VERSION "FL_IC_CANFD"

NS_ :

BS_:

BU_: AVAS BBCM CMSM DVR EAMP EPC FLZCU ICC PCL PLG SBOX SCU

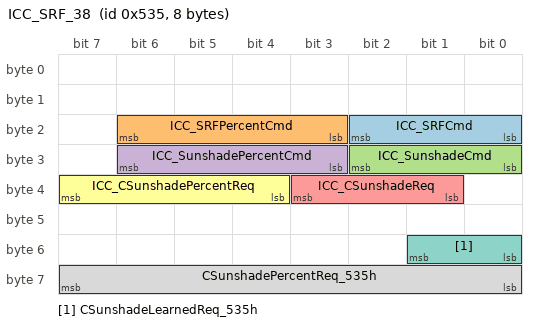
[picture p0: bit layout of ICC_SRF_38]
BO_ 1333 ICC_SRF_38: 8 ICC
 SG_ ICC_SRFCmd : 18|3@0+ (1,0) [0|7] ""  FLZCU
 SG_ ICC_SRFPercentCmd : 22|4@0+ (1,0) [0|15] ""  FLZCU
 SG_ ICC_SunshadeCmd : 26|3@0+ (1,0) [0|7] ""  FLZCU
 SG_ ICC_SunshadePercentCmd : 30|4@0+ (1,0) [0|15] ""  FLZCU
 SG_ ICC_CSunshadeReq : 35|3@0+ (1,0) [0|7] ""  FLZCU
 SG_ ICC_CSunshadePercentReq : 39|4@0+ (1,0) [0|15] ""  FLZCU
 SG_ CSunshadeLearnedReq_535h : 49|2@0+ (1,0) [0|3] ""  FLZCU
 SG_ CSunshadePercentReq_535h : 63|8@0+ (1,0) [0|255] "%"  FLZCU

BO_ 1335 ICC_CH_39: 32 ICC
 SG_ ICC_SET_EPS_SteerReturnRmdSts : 17|2@0+ (1,0) [0|3] ""  FLZCU
 SG_ ICC_SET_MFSShake : 19|2@0+ (1,0) [0|3] ""  FLZCU
 SG_ ICC_DMS_1_DistractionLevel : 22|3@0+ (1,0) [0|7] ""  FLZCU
 SG_ ICC_SET_EPS_AsociWithDrvModSts : 25|2@0+ (1,0) [0|3] ""  FLZCU
 SG_ ICC_OverLoadWarnShieldSet : 27|2@0+ (1,0) [0|3] ""  FLZCU
 SG_ ICC_BSWReq : 29|2@0+ (1,0) [0|3] ""  FLZCU
 SG_ ICC_horizontalReq : 31|2@0+ (1,0) [0|3] ""  FLZCU
 SG_ ICC_RolloverSetCmd : 33|2@0+ (1,0) [0|3] ""  FLZCU
 SG_ ICC_TrekThroughReq_537h : 35|2@0+ (1,0) [0|3] ""  FLZCU
 SG_ ICC_InflateReq_537h : 37|2@0+ (1,0) [0|3] ""  FLZCU
 SG_ ICC_UndergroundModeReq_537h : 39|2@0+ (1,0) [0|3] ""  FLZCU
 SG_ ICC_SandABSSw_537h : 41|2@0+ (1,0) [0|3] ""  FLZCU
 SG_ ICC_SandABSCmd_537h : 43|2@0+ (1,0) [0|3] ""  FLZCU
 SG_ ICC_EPBAUTOCmd_537h : 45|2@0+ (1,0) [0|3] ""  FLZCU
 SG_ ICC_SpeParkSet_537h : 47|2@0+ (1,0) [0|3] ""  FLZCU

BO_ 1337 ICC_TMS_40: 16 ICC
 SG_ ICC_SET_BT_ReduceWindSpeed : 17|2@0+ (1,0) [0|3] ""  FLZCU
 SG_ ICC_SET_IPM_FirstBlowing : 19|2@0+ (1,0) [0|3] ""  FLZCU
 SG_ ICC_SET_IPM_BlowerDelay : 21|2@0+ (1,0) [0|3] ""  FLZCU
 SG_ ICC_SET_CirculationInTunnels : 23|2@0+ (1,0) [0|3] ""  FLZCU
 SG_ ICC_UVCLuminanceReq : 25|2@0+ (1,0) [0|3] ""  FLZCU
 SG_ ICC_UVCControlReq : 27|2@0+ (1,0) [0|3] ""  FLZCU
 SG_ ICC_CrossCountryCoolingReq : 29|2@0+ (1,0) [0|3] ""  FLZCU
 SG_ ICC_KeepWarmReq : 31|2@0+ (1,0) [0|3] ""  FLZCU
 SG_ ICC_keepwarmSetTemperatureReq : 39|8@0+ (1,0) [0|255] ""  FLZCU
 SG_ ICC_ParkingAirConditioning : 41|2@0+ (1,0) [0|3] ""  FLZCU
 SG_ ICC_CoolantFill_Req : 43|2@0+ (1,0) [0|3] ""  FLZCU
 SG_ ICC_FraganceLightoffReq : 45|2@0+ (1,0) [0|3] ""  FLZCU
 SG_ ICC_FraganceMemoffReq : 47|2@0+ (1,0) [0|3] ""  FLZCU
 SG_ ICC_TimingLevel : 50|3@0+ (1,0) [0|7] ""  FLZCU
 SG_ ICC_CFSCycleLevel : 53|3@0+ (1,0) [0|7] ""  FLZCU
 SG_ ICC_AirPurgeReminderReq : 55|2@0+ (1,0) [0|3] ""  FLZCU
 SG_ ICC_TimedVentilationReq : 57|2@0+ (1,0) [0|3] ""  FLZCU
 SG_ ICC_BiochemicalFuncReq : 59|2@0+ (1,0) [0|3] ""  FLZCU
 SG_ ICC_ModeAdjustDisplaySts : 63|4@0+ (1,0) [0|15] ""  FLZCU
 SG_ ICC_PetModeSetTemperature_R_C : 82|5@0+ (0.5,15.5) [15.5|30.5] "℃"  FLZCU
 SG_ ICC_PetmodeSetTemperature_L_C : 87|5@0+ (0.5,15.5) [15.5|30.5] "℃"  FLZCU
 SG_ ICC_PetModeSetCirculationSts : 89|2@0+ (1,0) [0|3] ""  FLZCU
 SG_ ICC_PetModeSetAutoKeySts : 91|2@0+ (1,0) [0|3] ""  FLZCU
 SG_ ICC_PetModeSetCLMOn : 93|2@0+ (1,0) [0|3] ""  FLZCU
 SG_ ICC_ISSFctCmd_539h : 97|2@0+ (1,0) [0|3] ""  FLZCU

BO_ 1338 FMCU_1_G: 8 FLZCU
 SG_ FMCU_ErrLvlDis : 19|3@0+ (1,0) [0|7] ""  ICC
 SG_ FMCU_SpdAct_EDR : 39|16@0+ (1,-32767) [-32767|32766] "rpm"  ICC

BO_ 1341 BMS_44: 48 FLZCU
 SG_ BMS_44_PackPowerRealTime : 23|15@0+ (0.1,-1024) [-1024|1024] "kW"  ICC

BO_ 1345 DVR_1: 16 DVR
 SG_ DVR_1_DVRFailReasons : 20|3@0+ (1,0) [0|7] ""  ICC
 SG_ DVR_1_RecordSts : 22|2@0+ (1,0) [0|3] ""  ICC
 SG_ DVR_1_Sdcard_Sts : 26|3@0+ (1,0) [0|7] ""  ICC

BO_ 1349 SBOX_MSD_1: 16 SBOX
 SG_ SBOX_MSD_Res : 3|4@0+ (1,0) [0|15] ""  ICC
 SG_ SBOX_Ecallphonenub_Res : 7|4@0+ (1,0) [0|15] ""  ICC

BO_ 1351 SBOX_CFG_3: 32 SBOX
 SG_ SBOX_SetMsgTotal : 15|16@0+ (1,0) [0|1000] ""  ICC
 SG_ SBOX_SetMSDTotal : 31|16@0+ (1,0) [0|1000] ""  ICC
 SG_ SBOX_SetCallTimeThreshold : 55|16@0+ (1,0) [0|65535] "min"  ICC
 SG_ SBOX_SetTodayCallTimeThreshold : 71|16@0+ (1,0) [0|65535] "min"  ICC
 SG_ SBOX_SetCurretnCallTime : 87|16@0+ (1,0) [0|65535] "min"  ICC
 SG_ SBOX_SetCurretnMsgThreshold : 103|16@0+ (1,0) [0|1000] ""  ICC
 SG_ SBOX_SetMsgTotalThreshold : 119|16@0+ (1,0) [0|1000] ""  ICC
 SG_ SBOX_SetMsdThreshold : 135|16@0+ (1,0) [0|1000] ""  ICC
 SG_ SBOX_SetCurrenMsdCnt : 151|16@0+ (1,0) [0|1000] ""  ICC
 SG_ SBOX_SetCustomMsgThreshold : 167|16@0+ (1,0) [0|1000] ""  ICC
 SG_ SBOX_SetCurrentCustomMsgCnt : 183|16@0+ (1,0) [0|1000] ""  ICC

BO_ 1353 SBOX_CFG_4: 16 SBOX
 SG_ SBOX_ICC_MACReq : 0|1@0+ (1,0) [0|1] ""  ICC
 SG_ SBOX_MAC_Req0 : 15|8@0+ (1,0) [0|255] ""  ICC
 SG_ SBOX_MAC_Req1 : 23|8@0+ (1,0) [0|255] ""  ICC
 SG_ SBOX_MAC_Req2 : 31|8@0+ (1,0) [0|255] ""  ICC
 SG_ SBOX_MAC_Req3 : 39|8@0+ (1,0) [0|255] ""  ICC
 SG_ SBOX_MAC_Req4 : 47|8@0+ (1,0) [0|255] ""  ICC
 SG_ SBOX_MAC_Req5 : 55|8@0+ (1,0) [0|255] ""  ICC

BO_ 1354 ICC_CFG_46: 32 ICC
 SG_ ICC_SetMsgTotal : 15|16@0+ (1,0) [0|1000] ""  SBOX
 SG_ ICC_SetMSDTotal : 31|16@0+ (1,0) [0|1000] ""  SBOX
 SG_ ICC_SetCallTimeThreshold : 55|16@0+ (1,0) [0|65535] "min"  SBOX
 SG_ ICC_SetTodayCallTimeThreshold : 71|16@0+ (1,0) [0|65535] "min"  SBOX
 SG_ ICC_SetCurretnCallTime : 87|16@0+ (1,0) [0|65535] "min"  SBOX
 SG_ ICC_SetCurretnMsgThreshold : 103|16@0+ (1,0) [0|1000] ""  SBOX
 SG_ ICC_SetMsgTotalThreshold : 119|16@0+ (1,0) [0|1000] ""  SBOX
 SG_ ICC_SetMsdThreshold : 135|16@0+ (1,0) [0|1000] ""  SBOX
 SG_ ICC_SetCurrenMsdCnt : 151|16@0+ (1,0) [0|1000] ""  SBOX
 SG_ ICC_SetCustomMsgThreshold : 167|16@0+ (1,0) [0|1000] ""  SBOX
 SG_ ICC_SetCurrentCustomMsgCnt : 183|16@0+ (1,0) [0|1000] ""  SBOX

BO_ 1356 ICC_CFG_47: 32 ICC
 SG_ ICC_flag : 1|2@0+ (1,0) [0|3] ""  SBOX
 SG_ ICC_ActiveTsp_Req : 3|2@0+ (1,0) [0|3] ""  SBOX
 SG_ ICC_ActiveSim_Req : 5|2@0+ (1,0) [0|3] ""  SBOX
 SG_ ICC_GetMac_req : 6|1@0+ (1,0) [0|1] ""  SBOX
 SG_ ICC_GetIccid_Vin : 7|1@0+ (1,0) [0|1] ""  SBOX
 SG_ ICC_Platform_Phonenub1 : 11|4@0+ (1,0) [0|9] ""  SBOX
 SG_ ICC_Platform_Phonenub2 : 15|4@0+ (1,0) [0|9] ""  SBOX
 SG_ ICC_Platform_Phonenub3 : 19|4@0+ (1,0) [0|9] ""  SBOX
 SG_ ICC_Platform_Phonenub4 : 23|4@0+ (1,0) [0|9] ""  SBOX
 SG_ ICC_Platform_Phonenub5 : 27|4@0+ (1,0) [0|9] ""  SBOX
 SG_ ICC_Platform_Phonenub6 : 31|4@0+ (1,0) [0|9] ""  SBOX
 SG_ ICC_Platform_Phonenub7 : 35|4@0+ (1,0) [0|9] ""  SBOX
 SG_ ICC_Platform_Phonenub8 : 39|4@0+ (1,0) [0|9] ""  SBOX
 SG_ ICC_Platform_Phonenub9 : 43|4@0+ (1,0) [0|9] ""  SBOX
 SG_ ICC_Platform_Phonenub10 : 47|4@0+ (1,0) [0|9] ""  SBOX
 SG_ ICC_Platform_Phonenub11 : 51|4@0+ (1,0) [0|9] ""  SBOX
 SG_ ICC_Platform_Phonenub12 : 55|4@0+ (1,0) [0|9] ""  SBOX
 SG_ ICC_Platform_Phonenub13 : 59|4@0+ (1,0) [0|9] ""  SBOX
 SG_ ICC_Platform_Phonenub14 : 63|4@0+ (1,0) [0|9] ""  SBOX
 SG_ ICC_Platform_Phonenub15 : 67|4@0+ (1,0) [0|9] ""  SBOX
 SG_ ICC_Platform_Phonenub16 : 71|4@0+ (1,0) [0|9] ""  SBOX
 SG_ ICC_Platform_Phonenub17 : 75|4@0+ (1,0) [0|9] ""  SBOX
 SG_ ICC_Platform_Phonenub18 : 79|4@0+ (1,0) [0|9] ""  SBOX
 SG_ ICC_Platform_Phonenub19 : 83|4@0+ (1,0) [0|9] ""  SBOX
 SG_ ICC_Platform_Phonenub20 : 87|4@0+ (1,0) [0|9] ""  SBOX
 SG_ ICC_Mac0 : 95|8@0+ (1,0) [0|255] ""  SBOX
 SG_ ICC_Mac1 : 103|8@0+ (1,0) [0|255] ""  SBOX
 SG_ ICC_Mac2 : 111|8@0+ (1,0) [0|255] ""  SBOX
 SG_ ICC_Mac3 : 119|8@0+ (1,0) [0|255] ""  SBOX
 SG_ ICC_Mac4 : 127|8@0+ (1,0) [0|255] ""  SBOX
 SG_ ICC_Mac5 : 135|8@0+ (1,0) [0|255] ""  SBOX
 SG_ ICC_GivePlatformNumber_Flag : 248|1@0+ (1,0) [0|1] ""  SBOX
 SG_ ICC_Mac_Flag : 249|1@0+ (1,0) [0|1] ""  SBOX

BO_ 1358 SBOX_CFG_5: 64 SBOX
 SG_ SBOX_ActiveTsp_Res : 0|1@0+ (1,0) [0|1] ""  ICC
 SG_ SBOX_ActiveSim_Res : 1|1@0+ (1,0) [0|1] ""  ICC
 SG_ SBOX_GetPlatformNumberRes : 2|1@0+ (1,0) [0|1] ""  ICC
 SG_ SBOX_Mac_Res0 : 15|8@0+ (1,0) [0|255] ""  ICC
 SG_ SBOX_Mac_Res1 : 23|8@0+ (1,0) [0|255] ""  ICC
 SG_ SBOX_Mac_Res2 : 31|8@0+ (1,0) [0|255] ""  ICC
 SG_ SBOX_Mac_Res3 : 39|8@0+ (1,0) [0|255] ""  ICC
 SG_ SBOX_Mac_Res4 : 47|8@0+ (1,0) [0|255] ""  ICC
 SG_ SBOX_Mac_Res5 : 55|8@0+ (1,0) [0|255] ""  ICC
 SG_ SBOX_ICCId_Res0 : 99|4@0+ (1,0) [0|9] ""  ICC
 SG_ SBOX_ICCId_Res1 : 103|4@0+ (1,0) [0|9] ""  ICC
 SG_ SBOX_ICCId_Res2 : 107|4@0+ (1,0) [0|9] ""  ICC
 SG_ SBOX_ICCId_Res3 : 111|4@0+ (1,0) [0|9] ""  ICC
 SG_ SBOX_ICCId_Res4 : 115|4@0+ (1,0) [0|9] ""  ICC
 SG_ SBOX_ICCId_Res5 : 119|4@0+ (1,0) [0|9] ""  ICC
 SG_ SBOX_ICCId_Res6 : 123|4@0+ (1,0) [0|9] ""  ICC
 SG_ SBOX_ICCId_Res7 : 127|4@0+ (1,0) [0|9] ""  ICC
 SG_ SBOX_ICCId_Res8 : 131|4@0+ (1,0) [0|9] ""  ICC
 SG_ SBOX_ICCId_Res9 : 135|4@0+ (1,0) [0|9] ""  ICC
 SG_ SBOX_ICCId_Res10 : 139|4@0+ (1,0) [0|9] ""  ICC
 SG_ SBOX_ICCId_Res11 : 143|4@0+ (1,0) [0|9] ""  ICC
 SG_ SBOX_ICCId_Res12 : 147|4@0+ (1,0) [0|9] ""  ICC
 SG_ SBOX_ICCId_Res13 : 151|4@0+ (1,0) [0|9] ""  ICC
 SG_ SBOX_ICCId_Res14 : 155|4@0+ (1,0) [0|9] ""  ICC
 SG_ SBOX_ICCId_Res15 : 159|4@0+ (1,0) [0|9] ""  ICC
 SG_ SBOX_ICCId_Res16 : 163|4@0+ (1,0) [0|9] ""  ICC
 SG_ SBOX_ICCId_Res17 : 167|4@0+ (1,0) [0|9] ""  ICC
 SG_ SBOX_ICCId_Res18 : 171|4@0+ (1,0) [0|9] ""  ICC
 SG_ SBOX_ICCId_Res19 : 175|4@0+ (1,0) [0|9] ""  ICC
 SG_ SBOX_Vin0 : 183|8@0+ (1,0) [0|90] ""  ICC
 SG_ SBOX_Vin1 : 191|8@0+ (1,0) [0|90] ""  ICC
 SG_ SBOX_Vin2 : 199|8@0+ (1,0) [0|90] ""  ICC
 SG_ SBOX_Vin3 : 207|8@0+ (1,0) [0|90] ""  ICC
 SG_ SBOX_Vin4 : 215|8@0+ (1,0) [0|90] ""  ICC
 SG_ SBOX_Vin5 : 223|8@0+ (1,0) [0|90] ""  ICC
 SG_ SBOX_Vin6 : 231|8@0+ (1,0) [0|90] ""  ICC
 SG_ SBOX_Vin7 : 239|8@0+ (1,0) [0|90] ""  ICC
 SG_ SBOX_Vin8 : 247|8@0+ (1,0) [0|90] ""  ICC
 SG_ SBOX_Vin9 : 255|8@0+ (1,0) [0|90] ""  ICC
 SG_ SBOX_Vin10 : 263|8@0+ (1,0) [0|90] ""  ICC
 SG_ SBOX_Vin11 : 271|8@0+ (1,0) [0|90] ""  ICC
 SG_ SBOX_Vin12 : 279|8@0+ (1,0) [0|90] ""  ICC
 SG_ SBOX_Vin13 : 287|8@0+ (1,0) [0|90] ""  ICC
 SG_ SBOX_Vin14 : 295|8@0+ (1,0) [0|90] ""  ICC
 SG_ SBOX_Vin15 : 303|8@0+ (1,0) [0|90] ""  ICC
 SG_ SBOX_Vin16 : 311|8@0+ (1,0) [0|90] ""  ICC

BO_ 1360 ICC_LC_42: 64 ICC
 SG_ ICC_LISD_DisplaySwitch : 1|2@0+ (1,0) [0|3] ""  FLZCU
 SG_ ICC_LISD_ParkingShowCMD : 3|2@0+ (1,0) [0|3] ""  FLZCU
 SG_ ICC_RISD_DisplaySwitch : 7|2@0+ (1,0) [0|3] ""  FLZCU
 SG_ ICC_RISD_ParkingShowCMD : 9|2@0+ (1,0) [0|3] ""  FLZCU
 SG_ ICC_LogoParkingReq : 13|2@0+ (1,0) [0|3] ""  FLZCU
 SG_ ICC_LogoChargingReq : 15|2@0+ (1,0) [0|3] ""  FLZCU
 SG_ ICC_DRLSw : 17|2@0+ (1,0) [0|3] ""  FLZCU
 SG_ ICC_LISD_ParkingShowMod : 27|4@0+ (1,0) [0|15] ""  FLZCU
 SG_ ICC_RISD_ParkingShowMod : 31|4@0+ (1,0) [0|15] ""  FLZCU
 SG_ ICC_LogoColorReq : 33|9@0+ (1,0) [0|511] ""  FLZCU
 SG_ ICC_MusicLampShowSW : 35|2@0+ (1,0) [0|3] ""  FLZCU
 SG_ ICC_PenetrationLampSetF : 37|2@0+ (1,0) [0|3] ""  FLZCU
 SG_ ICC_XDriveMode : 40|5@0+ (1,0) [0|31] ""  FLZCU
 SG_ ICC_DowWaringSw : 57|2@0+ (1,0) [0|3] ""  FLZCU
 SG_ ICC_CarSearhSetSwitchSts : 59|2@0+ (1,0) [0|3] ""  FLZCU
 SG_ ICC_TDL_NightBright_SW_550h : 61|2@0+ (1,0) [0|3] ""  FLZCU

BO_ 1361 EPC_1: 64 EPC
 SG_ EPC_LeftPedalSystem_Sts : 27|4@0+ (1,0) [0|15] ""  ICC
 SG_ EPC_RightPedalSystem_Sts : 31|4@0+ (1,0) [0|15] ""  ICC
 SG_ EPC_LeftPedalTimeTravel : 39|8@0+ (1,0) [0|100] "%"  ICC
 SG_ EPC_RightPedalTimeTravel : 47|8@0+ (1,0) [0|100] "%"  ICC
 SG_ EPC_RightPedalRealTime_Sts : 50|3@0+ (1,0) [0|7] ""  ICC
 SG_ EPC_LeftPedalBreakIce_Sts : 52|2@0+ (1,0) [0|3] ""  ICC
 SG_ EPC_LeftPedalRealTime_Sts : 55|3@0+ (1,0) [0|7] ""  ICC
 SG_ EPC_RightPedalCmdStatus : 57|2@0+ (1,0) [0|3] ""  ICC
 SG_ EPC_LeftPedalCmdStatus : 59|2@0+ (1,0) [0|3] ""  ICC
 SG_ EPC_Enable_CmdStatus : 61|2@0+ (1,0) [0|3] ""  ICC
 SG_ EPC_RightPedalBreakIce_Sts : 63|2@0+ (1,0) [0|3] ""  ICC
 SG_ EPC_RightPedal3D_Sts : 253|2@0+ (1,0) [0|3] ""  ICC
 SG_ EPC_LeftPedal3D_Sts : 255|2@0+ (1,0) [0|3] ""  ICC

BO_ 1362 ICC_LISD_43: 64 ICC
 SG_ ICC_LISD_FrameCounter : 1|2@0+ (1,0) [0|3] ""  FLZCU
 SG_ ICC_LISD_RollingCounter : 3|2@0+ (1,0) [0|3] ""  FLZCU
 SG_ ICC_LISD_Pixel1_OnOff : 8|1@0+ (1,0) [0|1] ""  FLZCU
 SG_ ICC_LISD_Pixel2_OnOff : 9|1@0+ (1,0) [0|1] ""  FLZCU
 SG_ ICC_LISD_Pixel3_OnOff : 10|1@0+ (1,0) [0|1] ""  FLZCU
 SG_ ICC_LISD_Pixel4_OnOff : 11|1@0+ (1,0) [0|1] ""  FLZCU
 SG_ ICC_LISD_Pixel5_OnOff : 12|1@0+ (1,0) [0|1] ""  FLZCU
 SG_ ICC_LISD_Pixel6_OnOff : 13|1@0+ (1,0) [0|1] ""  FLZCU
 SG_ ICC_LISD_Pixel7_OnOff : 14|1@0+ (1,0) [0|1] ""  FLZCU
 SG_ ICC_LISD_Pixel8_OnOff : 15|1@0+ (1,0) [0|1] ""  FLZCU
 SG_ ICC_LISD_Pixel9_OnOff : 16|1@0+ (1,0) [0|1] ""  FLZCU
 SG_ ICC_LISD_Pixel10_OnOff : 17|1@0+ (1,0) [0|1] ""  FLZCU
 SG_ ICC_LISD_Pixel11_OnOff : 18|1@0+ (1,0) [0|1] ""  FLZCU
 SG_ ICC_LISD_Pixel12_OnOff : 19|1@0+ (1,0) [0|1] ""  FLZCU
 SG_ ICC_LISD_Pixel13_OnOff : 20|1@0+ (1,0) [0|1] ""  FLZCU
 SG_ ICC_LISD_Pixel14_OnOff : 21|1@0+ (1,0) [0|1] ""  FLZCU
 SG_ ICC_LISD_Pixel15_OnOff : 22|1@0+ (1,0) [0|1] ""  FLZCU
 SG_ ICC_LISD_Pixel16_OnOff : 23|1@0+ (1,0) [0|1] ""  FLZCU
 SG_ ICC_LISD_Pixel17_OnOff : 24|1@0+ (1,0) [0|1] ""  FLZCU
 SG_ ICC_LISD_Pixel18_OnOff : 25|1@0+ (1,0) [0|1] ""  FLZCU
 SG_ ICC_LISD_Pixel19_OnOff : 26|1@0+ (1,0) [0|1] ""  FLZCU
 SG_ ICC_LISD_Pixel20_OnOff : 27|1@0+ (1,0) [0|1] ""  FLZCU
 SG_ ICC_LISD_Pixel21_OnOff : 28|1@0+ (1,0) [0|1] ""  FLZCU
 SG_ ICC_LISD_Pixel22_OnOff : 29|1@0+ (1,0) [0|1] ""  FLZCU
 SG_ ICC_LISD_Pixel23_OnOff : 30|1@0+ (1,0) [0|1] ""  FLZCU
 SG_ ICC_LISD_Pixel24_OnOff : 31|1@0+ (1,0) [0|1] ""  FLZCU
 SG_ ICC_LISD_Pixel25_OnOff : 32|1@0+ (1,0) [0|1] ""  FLZCU
 SG_ ICC_LISD_Pixel26_OnOff : 33|1@0+ (1,0) [0|1] ""  FLZCU
 SG_ ICC_LISD_Pixel27_OnOff : 34|1@0+ (1,0) [0|1] ""  FLZCU
 SG_ ICC_LISD_Pixel28_OnOff : 35|1@0+ (1,0) [0|1] ""  FLZCU
 SG_ ICC_LISD_Pixel29_OnOff : 36|1@0+ (1,0) [0|1] ""  FLZCU
 SG_ ICC_LISD_Pixel30_OnOff : 37|1@0+ (1,0) [0|1] ""  FLZCU
 SG_ ICC_LISD_Pixel31_OnOff : 38|1@0+ (1,0) [0|1] ""  FLZCU
 SG_ ICC_LISD_Pixel32_OnOff : 39|1@0+ (1,0) [0|1] ""  FLZCU
 SG_ ICC_LISD_Pixel33_OnOff : 40|1@0+ (1,0) [0|1] ""  FLZCU
 SG_ ICC_LISD_Pixel34_OnOff : 41|1@0+ (1,0) [0|1] ""  FLZCU
 SG_ ICC_LISD_Pixel35_OnOff : 42|1@0+ (1,0) [0|1] ""  FLZCU
 SG_ ICC_LISD_Pixel36_OnOff : 43|1@0+ (1,0) [0|1] ""  FLZCU
 SG_ ICC_LISD_Pixel37_OnOff : 44|1@0+ (1,0) [0|1] ""  FLZCU
 SG_ ICC_LISD_Pixel38_OnOff : 45|1@0+ (1,0) [0|1] ""  FLZCU
 SG_ ICC_LISD_Pixel39_OnOff : 46|1@0+ (1,0) [0|1] ""  FLZCU
 SG_ ICC_LISD_Pixel40_OnOff : 47|1@0+ (1,0) [0|1] ""  FLZCU
 SG_ ICC_LISD_Pixel41_OnOff : 48|1@0+ (1,0) [0|1] ""  FLZCU
 SG_ ICC_LISD_Pixel42_OnOff : 49|1@0+ (1,0) [0|1] ""  FLZCU
 SG_ ICC_LISD_Pixel43_OnOff : 50|1@0+ (1,0) [0|1] ""  FLZCU
 SG_ ICC_LISD_Pixel44_OnOff : 51|1@0+ (1,0) [0|1] ""  FLZCU
 SG_ ICC_LISD_Pixel45_OnOff : 52|1@0+ (1,0) [0|1] ""  FLZCU
 SG_ ICC_LISD_Pixel46_OnOff : 53|1@0+ (1,0) [0|1] ""  FLZCU
 SG_ ICC_LISD_Pixel47_OnOff : 54|1@0+ (1,0) [0|1] ""  FLZCU
 SG_ ICC_LISD_Pixel48_OnOff : 55|1@0+ (1,0) [0|1] ""  FLZCU
 SG_ ICC_LISD_Pixel49_OnOff : 56|1@0+ (1,0) [0|1] ""  FLZCU
 SG_ ICC_LISD_Pixel50_OnOff : 57|1@0+ (1,0) [0|1] ""  FLZCU
 SG_ ICC_LISD_Pixel51_OnOff : 58|1@0+ (1,0) [0|1] ""  FLZCU
 SG_ ICC_LISD_Pixel52_OnOff : 59|1@0+ (1,0) [0|1] ""  FLZCU
 SG_ ICC_LISD_Pixel53_OnOff : 60|1@0+ (1,0) [0|1] ""  FLZCU
 SG_ ICC_LISD_Pixel54_OnOff : 61|1@0+ (1,0) [0|1] ""  FLZCU
 SG_ ICC_LISD_Pixel55_OnOff : 62|1@0+ (1,0) [0|1] ""  FLZCU
 SG_ ICC_LISD_Pixel56_OnOff : 63|1@0+ (1,0) [0|1] ""  FLZCU
 SG_ ICC_LISD_Pixel57_OnOff : 64|1@0+ (1,0) [0|1] ""  FLZCU
 SG_ ICC_LISD_Pixel58_OnOff : 65|1@0+ (1,0) [0|1] ""  FLZCU
 SG_ ICC_LISD_Pixel59_OnOff : 66|1@0+ (1,0) [0|1] ""  FLZCU
 SG_ ICC_LISD_Pixel60_OnOff : 67|1@0+ (1,0) [0|1] ""  FLZCU
 SG_ ICC_LISD_Pixel61_OnOff : 68|1@0+ (1,0) [0|1] ""  FLZCU
 SG_ ICC_LISD_Pixel62_OnOff : 69|1@0+ (1,0) [0|1] ""  FLZCU
 SG_ ICC_LISD_Pixel63_OnOff : 70|1@0+ (1,0) [0|1] ""  FLZCU
 SG_ ICC_LISD_Pixel64_OnOff : 71|1@0+ (1,0) [0|1] ""  FLZCU
 SG_ ICC_LISD_Pixel65_OnOff : 72|1@0+ (1,0) [0|1] ""  FLZCU
 SG_ ICC_LISD_Pixel66_OnOff : 73|1@0+ (1,0) [0|1] ""  FLZCU
 SG_ ICC_LISD_Pixel67_OnOff : 74|1@0+ (1,0) [0|1] ""  FLZCU
 SG_ ICC_LISD_Pixel68_OnOff : 75|1@0+ (1,0) [0|1] ""  FLZCU
 SG_ ICC_LISD_Pixel69_OnOff : 76|1@0+ (1,0) [0|1] ""  FLZCU
 SG_ ICC_LISD_Pixel70_OnOff : 77|1@0+ (1,0) [0|1] ""  FLZCU
 SG_ ICC_LISD_Pixel71_OnOff : 78|1@0+ (1,0) [0|1] ""  FLZCU
 SG_ ICC_LISD_Pixel72_OnOff : 79|1@0+ (1,0) [0|1] ""  FLZCU
 SG_ ICC_LISD_Pixel73_OnOff : 80|1@0+ (1,0) [0|1] ""  FLZCU
 SG_ ICC_LISD_Pixel74_OnOff : 81|1@0+ (1,0) [0|1] ""  FLZCU
 SG_ ICC_LISD_Pixel75_OnOff : 82|1@0+ (1,0) [0|1] ""  FLZCU
 SG_ ICC_LISD_Pixel76_OnOff : 83|1@0+ (1,0) [0|1] ""  FLZCU
 SG_ ICC_LISD_Pixel77_OnOff : 84|1@0+ (1,0) [0|1] ""  FLZCU
 SG_ ICC_LISD_Pixel78_OnOff : 85|1@0+ (1,0) [0|1] ""  FLZCU
 SG_ ICC_LISD_Pixel79_OnOff : 86|1@0+ (1,0) [0|1] ""  FLZCU
 SG_ ICC_LISD_Pixel80_OnOff : 87|1@0+ (1,0) [0|1] ""  FLZCU
 SG_ ICC_LISD_Pixel81_OnOff : 88|1@0+ (1,0) [0|1] ""  FLZCU
 SG_ ICC_LISD_Pixel82_OnOff : 89|1@0+ (1,0) [0|1] ""  FLZCU
 SG_ ICC_LISD_Pixel83_OnOff : 90|1@0+ (1,0) [0|1] ""  FLZCU
 SG_ ICC_LISD_Pixel84_OnOff : 91|1@0+ (1,0) [0|1] ""  FLZCU
 SG_ ICC_LISD_Pixel85_OnOff : 92|1@0+ (1,0) [0|1] ""  FLZCU
 SG_ ICC_LISD_Pixel86_OnOff : 93|1@0+ (1,0) [0|1] ""  FLZCU
 SG_ ICC_LISD_Pixel87_OnOff : 94|1@0+ (1,0) [0|1] ""  FLZCU
 SG_ ICC_LISD_Pixel88_OnOff : 95|1@0+ (1,0) [0|1] ""  FLZCU
 SG_ ICC_LISD_Pixel89_OnOff : 96|1@0+ (1,0) [0|1] ""  FLZCU
 SG_ ICC_LISD_Pixel90_OnOff : 97|1@0+ (1,0) [0|1] ""  FLZCU
 SG_ ICC_LISD_Pixel91_OnOff : 98|1@0+ (1,0) [0|1] ""  FLZCU
 SG_ ICC_LISD_Pixel92_OnOff : 99|1@0+ (1,0) [0|1] ""  FLZCU
 SG_ ICC_LISD_Pixel93_OnOff : 100|1@0+ (1,0) [0|1] ""  FLZCU
 SG_ ICC_LISD_Pixel94_OnOff : 101|1@0+ (1,0) [0|1] ""  FLZCU
 SG_ ICC_LISD_Pixel95_OnOff : 102|1@0+ (1,0) [0|1] ""  FLZCU
 SG_ ICC_LISD_Pixel96_OnOff : 103|1@0+ (1,0) [0|1] ""  FLZCU
 SG_ ICC_LISD_Pixel97_OnOff : 104|1@0+ (1,0) [0|1] ""  FLZCU
 SG_ ICC_LISD_Pixel98_OnOff : 105|1@0+ (1,0) [0|1] ""  FLZCU
 SG_ ICC_LISD_Pixel99_OnOff : 106|1@0+ (1,0) [0|1] ""  FLZCU
 SG_ ICC_LISD_Pixel100_OnOff : 107|1@0+ (1,0) [0|1] ""  FLZCU
 SG_ ICC_LISD_Pixel101_OnOff : 108|1@0+ (1,0) [0|1] ""  FLZCU
 SG_ ICC_LISD_Pixel102_OnOff : 109|1@0+ (1,0) [0|1] ""  FLZCU
 SG_ ICC_LISD_Pixel103_OnOff : 110|1@0+ (1,0) [0|1] ""  FLZCU
 SG_ ICC_LISD_Pixel104_OnOff : 111|1@0+ (1,0) [0|1] ""  FLZCU
 SG_ ICC_LISD_Pixel105_OnOff : 112|1@0+ (1,0) [0|1] ""  FLZCU
 SG_ ICC_LISD_Pixel106_OnOff : 113|1@0+ (1,0) [0|1] ""  FLZCU
 SG_ ICC_LISD_Pixel107_OnOff : 114|1@0+ (1,0) [0|1] ""  FLZCU
 SG_ ICC_LISD_Pixel108_OnOff : 115|1@0+ (1,0) [0|1] ""  FLZCU
 SG_ ICC_LISD_Pixel109_OnOff : 116|1@0+ (1,0) [0|1] ""  FLZCU
 SG_ ICC_LISD_Pixel110_OnOff : 117|1@0+ (1,0) [0|1] ""  FLZCU
 SG_ ICC_LISD_Pixel111_OnOff : 118|1@0+ (1,0) [0|1] ""  FLZCU
 SG_ ICC_LISD_Pixel112_OnOff : 119|1@0+ (1,0) [0|1] ""  FLZCU
 SG_ ICC_LISD_Pixel113_OnOff : 120|1@0+ (1,0) [0|1] ""  FLZCU
 SG_ ICC_LISD_Pixel114_OnOff : 121|1@0+ (1,0) [0|1] ""  FLZCU
 SG_ ICC_LISD_Pixel115_OnOff : 122|1@0+ (1,0) [0|1] ""  FLZCU
 SG_ ICC_LISD_Pixel116_OnOff : 123|1@0+ (1,0) [0|1] ""  FLZCU
 SG_ ICC_LISD_Pixel117_OnOff : 124|1@0+ (1,0) [0|1] ""  FLZCU
 SG_ ICC_LISD_Pixel118_OnOff : 125|1@0+ (1,0) [0|1] ""  FLZCU
 SG_ ICC_LISD_Pixel119_OnOff : 126|1@0+ (1,0) [0|1] ""  FLZCU
 SG_ ICC_LISD_Pixel120_OnOff : 127|1@0+ (1,0) [0|1] ""  FLZCU
 SG_ ICC_LISD_Pixel121_OnOff : 128|1@0+ (1,0) [0|1] ""  FLZCU
 SG_ ICC_LISD_Pixel122_OnOff : 129|1@0+ (1,0) [0|1] ""  FLZCU
 SG_ ICC_LISD_Pixel123_OnOff : 130|1@0+ (1,0) [0|1] ""  FLZCU
 SG_ ICC_LISD_Pixel124_OnOff : 131|1@0+ (1,0) [0|1] ""  FLZCU
 SG_ ICC_LISD_Pixel125_OnOff : 132|1@0+ (1,0) [0|1] ""  FLZCU
 SG_ ICC_LISD_Pixel126_OnOff : 133|1@0+ (1,0) [0|1] ""  FLZCU
 SG_ ICC_LISD_Pixel127_OnOff : 134|1@0+ (1,0) [0|1] ""  FLZCU
 SG_ ICC_LISD_Pixel128_OnOff : 135|1@0+ (1,0) [0|1] ""  FLZCU
 SG_ ICC_LISD_Pixel129_OnOff : 136|1@0+ (1,0) [0|1] ""  FLZCU
 SG_ ICC_LISD_Pixel130_OnOff : 137|1@0+ (1,0) [0|1] ""  FLZCU
 SG_ ICC_LISD_Pixel131_OnOff : 138|1@0+ (1,0) [0|1] ""  FLZCU
 SG_ ICC_LISD_Pixel132_OnOff : 139|1@0+ (1,0) [0|1] ""  FLZCU
 SG_ ICC_LISD_Pixel133_OnOff : 140|1@0+ (1,0) [0|1] ""  FLZCU
 SG_ ICC_LISD_Pixel134_OnOff : 141|1@0+ (1,0) [0|1] ""  FLZCU
 SG_ ICC_LISD_Pixel135_OnOff : 142|1@0+ (1,0) [0|1] ""  FLZCU
 SG_ ICC_LISD_Pixel136_OnOff : 143|1@0+ (1,0) [0|1] ""  FLZCU
 SG_ ICC_LISD_Pixel137_OnOff : 144|1@0+ (1,0) [0|1] ""  FLZCU
 SG_ ICC_LISD_Pixel138_OnOff : 145|1@0+ (1,0) [0|1] ""  FLZCU
 SG_ ICC_LISD_Pixel139_OnOff : 146|1@0+ (1,0) [0|1] ""  FLZCU
 SG_ ICC_LISD_Pixel140_OnOff : 147|1@0+ (1,0) [0|1] ""  FLZCU
 SG_ ICC_LISD_Pixel141_OnOff : 148|1@0+ (1,0) [0|1] ""  FLZCU
 SG_ ICC_LISD_Pixel142_OnOff : 149|1@0+ (1,0) [0|1] ""  FLZCU
 SG_ ICC_LISD_Pixel143_OnOff : 150|1@0+ (1,0) [0|1] ""  FLZCU
 SG_ ICC_LISD_Pixel144_OnOff : 151|1@0+ (1,0) [0|1] ""  FLZCU
 SG_ ICC_LISD_Pixel145_OnOff : 152|1@0+ (1,0) [0|1] ""  FLZCU
 SG_ ICC_LISD_Pixel146_OnOff : 153|1@0+ (1,0) [0|1] ""  FLZCU
 SG_ ICC_LISD_Pixel147_OnOff : 154|1@0+ (1,0) [0|1] ""  FLZCU
 SG_ ICC_LISD_Pixel148_OnOff : 155|1@0+ (1,0) [0|1] ""  FLZCU
 SG_ ICC_LISD_Pixel149_OnOff : 156|1@0+ (1,0) [0|1] ""  FLZCU
 SG_ ICC_LISD_Pixel150_OnOff : 157|1@0+ (1,0) [0|1] ""  FLZCU
 SG_ ICC_LISD_Pixel151_OnOff : 158|1@0+ (1,0) [0|1] ""  FLZCU
 SG_ ICC_LISD_Pixel152_OnOff : 159|1@0+ (1,0) [0|1] ""  FLZCU
 SG_ ICC_LISD_Pixel153_OnOff : 160|1@0+ (1,0) [0|1] ""  FLZCU
 SG_ ICC_LISD_Pixel154_OnOff : 161|1@0+ (1,0) [0|1] ""  FLZCU
 SG_ ICC_LISD_Pixel155_OnOff : 162|1@0+ (1,0) [0|1] ""  FLZCU
 SG_ ICC_LISD_Pixel156_OnOff : 163|1@0+ (1,0) [0|1] ""  FLZCU
 SG_ ICC_LISD_Pixel157_OnOff : 164|1@0+ (1,0) [0|1] ""  FLZCU
 SG_ ICC_LISD_Pixel158_OnOff : 165|1@0+ (1,0) [0|1] ""  FLZCU
 SG_ ICC_LISD_Pixel159_OnOff : 166|1@0+ (1,0) [0|1] ""  FLZCU
 SG_ ICC_LISD_Pixel160_OnOff : 167|1@0+ (1,0) [0|1] ""  FLZCU
 SG_ ICC_LISD_Pixel161_OnOff : 168|1@0+ (1,0) [0|1] ""  FLZCU
 SG_ ICC_LISD_Pixel162_OnOff : 169|1@0+ (1,0) [0|1] ""  FLZCU
 SG_ ICC_LISD_Pixel163_OnOff : 170|1@0+ (1,0) [0|1] ""  FLZCU
 SG_ ICC_LISD_Pixel164_OnOff : 171|1@0+ (1,0) [0|1] ""  FLZCU
 SG_ ICC_LISD_Pixel165_OnOff : 172|1@0+ (1,0) [0|1] ""  FLZCU
 SG_ ICC_LISD_Pixel166_OnOff : 173|1@0+ (1,0) [0|1] ""  FLZCU
 SG_ ICC_LISD_Pixel167_OnOff : 174|1@0+ (1,0) [0|1] ""  FLZCU
 SG_ ICC_LISD_Pixel168_OnOff : 175|1@0+ (1,0) [0|1] ""  FLZCU
 SG_ ICC_LISD_Pixel169_OnOff : 176|1@0+ (1,0) [0|1] ""  FLZCU
 SG_ ICC_LISD_Pixel170_OnOff : 177|1@0+ (1,0) [0|1] ""  FLZCU
 SG_ ICC_LISD_Pixel171_OnOff : 178|1@0+ (1,0) [0|1] ""  FLZCU
 SG_ ICC_LISD_Pixel172_OnOff : 179|1@0+ (1,0) [0|1] ""  FLZCU
 SG_ ICC_LISD_Pixel173_OnOff : 180|1@0+ (1,0) [0|1] ""  FLZCU
 SG_ ICC_LISD_Pixel174_OnOff : 181|1@0+ (1,0) [0|1] ""  FLZCU
 SG_ ICC_LISD_Pixel175_OnOff : 182|1@0+ (1,0) [0|1] ""  FLZCU
 SG_ ICC_LISD_Pixel176_OnOff : 183|1@0+ (1,0) [0|1] ""  FLZCU
 SG_ ICC_LISD_Pixel177_OnOff : 184|1@0+ (1,0) [0|1] ""  FLZCU
 SG_ ICC_LISD_Pixel178_OnOff : 185|1@0+ (1,0) [0|1] ""  FLZCU
 SG_ ICC_LISD_Pixel179_OnOff : 186|1@0+ (1,0) [0|1] ""  FLZCU
 SG_ ICC_LISD_Pixel180_OnOff : 187|1@0+ (1,0) [0|1] ""  FLZCU
 SG_ ICC_LISD_Pixel181_OnOff : 188|1@0+ (1,0) [0|1] ""  FLZCU
 SG_ ICC_LISD_Pixel182_OnOff : 189|1@0+ (1,0) [0|1] ""  FLZCU
 SG_ ICC_LISD_Pixel183_OnOff : 190|1@0+ (1,0) [0|1] ""  FLZCU
 SG_ ICC_LISD_Pixel184_OnOff : 191|1@0+ (1,0) [0|1] ""  FLZCU
 SG_ ICC_LISD_Pixel185_OnOff : 192|1@0+ (1,0) [0|1] ""  FLZCU
 SG_ ICC_LISD_Pixel186_OnOff : 193|1@0+ (1,0) [0|1] ""  FLZCU
 SG_ ICC_LISD_Pixel187_OnOff : 194|1@0+ (1,0) [0|1] ""  FLZCU
 SG_ ICC_LISD_Pixel188_OnOff : 195|1@0+ (1,0) [0|1] ""  FLZCU
 SG_ ICC_LISD_Pixel189_OnOff : 196|1@0+ (1,0) [0|1] ""  FLZCU
 SG_ ICC_LISD_Pixel190_OnOff : 197|1@0+ (1,0) [0|1] ""  FLZCU
 SG_ ICC_LISD_Pixel191_OnOff : 198|1@0+ (1,0) [0|1] ""  FLZCU
 SG_ ICC_LISD_Pixel192_OnOff : 199|1@0+ (1,0) [0|1] ""  FLZCU
 SG_ ICC_LISD_Pixel193_OnOff : 200|1@0+ (1,0) [0|1] ""  FLZCU
 SG_ ICC_LISD_Pixel194_OnOff : 201|1@0+ (1,0) [0|1] ""  FLZCU
 SG_ ICC_LISD_Pixel195_OnOff : 202|1@0+ (1,0) [0|1] ""  FLZCU
 SG_ ICC_LISD_Pixel196_OnOff : 203|1@0+ (1,0) [0|1] ""  FLZCU
 SG_ ICC_LISD_Pixel197_OnOff : 204|1@0+ (1,0) [0|1] ""  FLZCU
 SG_ ICC_LISD_Pixel198_OnOff : 205|1@0+ (1,0) [0|1] ""  FLZCU
 SG_ ICC_LISD_Pixel199_OnOff : 206|1@0+ (1,0) [0|1] ""  FLZCU
 SG_ ICC_LISD_Pixel200_OnOff : 207|1@0+ (1,0) [0|1] ""  FLZCU
 SG_ ICC_LISD_Pixel201_OnOff : 208|1@0+ (1,0) [0|1] ""  FLZCU
 SG_ ICC_LISD_Pixel202_OnOff : 209|1@0+ (1,0) [0|1] ""  FLZCU
 SG_ ICC_LISD_Pixel203_OnOff : 210|1@0+ (1,0) [0|1] ""  FLZCU
 SG_ ICC_LISD_Pixel204_OnOff : 211|1@0+ (1,0) [0|1] ""  FLZCU
 SG_ ICC_LISD_Pixel205_OnOff : 212|1@0+ (1,0) [0|1] ""  FLZCU
 SG_ ICC_LISD_Pixel206_OnOff : 213|1@0+ (1,0) [0|1] ""  FLZCU
 SG_ ICC_LISD_Pixel207_OnOff : 214|1@0+ (1,0) [0|1] ""  FLZCU
 SG_ ICC_LISD_Pixel208_OnOff : 215|1@0+ (1,0) [0|1] ""  FLZCU
 SG_ ICC_LISD_Pixel209_OnOff : 216|1@0+ (1,0) [0|1] ""  FLZCU
 SG_ ICC_LISD_Pixel210_OnOff : 217|1@0+ (1,0) [0|1] ""  FLZCU
 SG_ ICC_LISD_Pixel211_OnOff : 218|1@0+ (1,0) [0|1] ""  FLZCU
 SG_ ICC_LISD_Pixel212_OnOff : 219|1@0+ (1,0) [0|1] ""  FLZCU
 SG_ ICC_LISD_Pixel213_OnOff : 220|1@0+ (1,0) [0|1] ""  FLZCU
 SG_ ICC_LISD_Pixel214_OnOff : 221|1@0+ (1,0) [0|1] ""  FLZCU
 SG_ ICC_LISD_Pixel215_OnOff : 222|1@0+ (1,0) [0|1] ""  FLZCU
 SG_ ICC_LISD_Pixel216_OnOff : 223|1@0+ (1,0) [0|1] ""  FLZCU
 SG_ ICC_LISD_Pixel217_OnOff : 224|1@0+ (1,0) [0|1] ""  FLZCU
 SG_ ICC_LISD_Pixel218_OnOff : 225|1@0+ (1,0) [0|1] ""  FLZCU
 SG_ ICC_LISD_Pixel219_OnOff : 226|1@0+ (1,0) [0|1] ""  FLZCU
 SG_ ICC_LISD_Pixel220_OnOff : 227|1@0+ (1,0) [0|1] ""  FLZCU
 SG_ ICC_LISD_Pixel221_OnOff : 228|1@0+ (1,0) [0|1] ""  FLZCU
 SG_ ICC_LISD_Pixel222_OnOff : 229|1@0+ (1,0) [0|1] ""  FLZCU
 SG_ ICC_LISD_Pixel223_OnOff : 230|1@0+ (1,0) [0|1] ""  FLZCU
 SG_ ICC_LISD_Pixel224_OnOff : 231|1@0+ (1,0) [0|1] ""  FLZCU
 SG_ ICC_LISD_Pixel225_OnOff : 232|1@0+ (1,0) [0|1] ""  FLZCU
 SG_ ICC_LISD_Pixel226_OnOff : 233|1@0+ (1,0) [0|1] ""  FLZCU
 SG_ ICC_LISD_Pixel227_OnOff : 234|1@0+ (1,0) [0|1] ""  FLZCU
 SG_ ICC_LISD_Pixel228_OnOff : 235|1@0+ (1,0) [0|1] ""  FLZCU
 SG_ ICC_LISD_Pixel229_OnOff : 236|1@0+ (1,0) [0|1] ""  FLZCU
 SG_ ICC_LISD_Pixel230_OnOff : 237|1@0+ (1,0) [0|1] ""  FLZCU
 SG_ ICC_LISD_Pixel231_OnOff : 238|1@0+ (1,0) [0|1] ""  FLZCU
 SG_ ICC_LISD_Pixel232_OnOff : 239|1@0+ (1,0) [0|1] ""  FLZCU
 SG_ ICC_LISD_Pixel233_OnOff : 240|1@0+ (1,0) [0|1] ""  FLZCU
 SG_ ICC_LISD_Pixel234_OnOff : 241|1@0+ (1,0) [0|1] ""  FLZCU
 SG_ ICC_LISD_Pixel235_OnOff : 242|1@0+ (1,0) [0|1] ""  FLZCU
 SG_ ICC_LISD_Pixel236_OnOff : 243|1@0+ (1,0) [0|1] ""  FLZCU
 SG_ ICC_LISD_Pixel237_OnOff : 244|1@0+ (1,0) [0|1] ""  FLZCU
 SG_ ICC_LISD_Pixel238_OnOff : 245|1@0+ (1,0) [0|1] ""  FLZCU
 SG_ ICC_LISD_Pixel239_OnOff : 246|1@0+ (1,0) [0|1] ""  FLZCU
 SG_ ICC_LISD_Pixel240_OnOff : 247|1@0+ (1,0) [0|1] ""  FLZCU
 SG_ ICC_LISD_Pixel241_OnOff : 248|1@0+ (1,0) [0|1] ""  FLZCU
 SG_ ICC_LISD_Pixel242_OnOff : 249|1@0+ (1,0) [0|1] ""  FLZCU
 SG_ ICC_LISD_Pixel243_OnOff : 250|1@0+ (1,0) [0|1] ""  FLZCU
 SG_ ICC_LISD_Pixel244_OnOff : 251|1@0+ (1,0) [0|1] ""  FLZCU
 SG_ ICC_LISD_Pixel245_OnOff : 252|1@0+ (1,0) [0|1] ""  FLZCU
 SG_ ICC_LISD_Pixel246_OnOff : 253|1@0+ (1,0) [0|1] ""  FLZCU
 SG_ ICC_LISD_Pixel247_OnOff : 254|1@0+ (1,0) [0|1] ""  FLZCU
 SG_ ICC_LISD_Pixel248_OnOff : 255|1@0+ (1,0) [0|1] ""  FLZCU
 SG_ ICC_LISD_Pixel249_OnOff : 256|1@0+ (1,0) [0|1] ""  FLZCU
 SG_ ICC_LISD_Pixel250_OnOff : 257|1@0+ (1,0) [0|1] ""  FLZCU
 SG_ ICC_LISD_Pixel251_OnOff : 258|1@0+ (1,0) [0|1] ""  FLZCU
 SG_ ICC_LISD_Pixel252_OnOff : 259|1@0+ (1,0) [0|1] ""  FLZCU
 SG_ ICC_LISD_Pixel253_OnOff : 260|1@0+ (1,0) [0|1] ""  FLZCU
 SG_ ICC_LISD_Pixel254_OnOff : 261|1@0+ (1,0) [0|1] ""  FLZCU
 SG_ ICC_LISD_Pixel255_OnOff : 262|1@0+ (1,0) [0|1] ""  FLZCU
 SG_ ICC_LISD_Pixel256_OnOff : 263|1@0+ (1,0) [0|1] ""  FLZCU
 SG_ ICC_LISD_Pixel257_OnOff : 264|1@0+ (1,0) [0|1] ""  FLZCU
 SG_ ICC_LISD_Pixel258_OnOff : 265|1@0+ (1,0) [0|1] ""  FLZCU
 SG_ ICC_LISD_Pixel259_OnOff : 266|1@0+ (1,0) [0|1] ""  FLZCU
 SG_ ICC_LISD_Pixel260_OnOff : 267|1@0+ (1,0) [0|1] ""  FLZCU
 SG_ ICC_LISD_Pixel261_OnOff : 268|1@0+ (1,0) [0|1] ""  FLZCU
 SG_ ICC_LISD_Pixel262_OnOff : 269|1@0+ (1,0) [0|1] ""  FLZCU
 SG_ ICC_LISD_Pixel263_OnOff : 270|1@0+ (1,0) [0|1] ""  FLZCU
 SG_ ICC_LISD_Pixel264_OnOff : 271|1@0+ (1,0) [0|1] ""  FLZCU
 SG_ ICC_LISD_Pixel265_OnOff : 272|1@0+ (1,0) [0|1] ""  FLZCU
 SG_ ICC_LISD_Pixel266_OnOff : 273|1@0+ (1,0) [0|1] ""  FLZCU
 SG_ ICC_LISD_Pixel267_OnOff : 274|1@0+ (1,0) [0|1] ""  FLZCU
 SG_ ICC_LISD_Pixel268_OnOff : 275|1@0+ (1,0) [0|1] ""  FLZCU
 SG_ ICC_LISD_Pixel269_OnOff : 276|1@0+ (1,0) [0|1] ""  FLZCU
 SG_ ICC_LISD_Pixel270_OnOff : 277|1@0+ (1,0) [0|1] ""  FLZCU
 SG_ ICC_LISD_Pixel271_OnOff : 278|1@0+ (1,0) [0|1] ""  FLZCU
 SG_ ICC_LISD_Pixel272_OnOff : 279|1@0+ (1,0) [0|1] ""  FLZCU
 SG_ ICC_LISD_Pixel273_OnOff : 280|1@0+ (1,0) [0|1] ""  FLZCU
 SG_ ICC_LISD_Pixel274_OnOff : 281|1@0+ (1,0) [0|1] ""  FLZCU
 SG_ ICC_LISD_Pixel275_OnOff : 282|1@0+ (1,0) [0|1] ""  FLZCU
 SG_ ICC_LISD_Pixel276_OnOff : 283|1@0+ (1,0) [0|1] ""  FLZCU
 SG_ ICC_LISD_Pixel277_OnOff : 284|1@0+ (1,0) [0|1] ""  FLZCU
 SG_ ICC_LISD_Pixel278_OnOff : 285|1@0+ (1,0) [0|1] ""  FLZCU
 SG_ ICC_LISD_Pixel279_OnOff : 286|1@0+ (1,0) [0|1] ""  FLZCU
 SG_ ICC_LISD_Pixel280_OnOff : 287|1@0+ (1,0) [0|1] ""  FLZCU
 SG_ ICC_LISD_Pixel281_OnOff : 288|1@0+ (1,0) [0|1] ""  FLZCU
 SG_ ICC_LISD_Pixel282_OnOff : 289|1@0+ (1,0) [0|1] ""  FLZCU
 SG_ ICC_LISD_Pixel283_OnOff : 290|1@0+ (1,0) [0|1] ""  FLZCU
 SG_ ICC_LISD_Pixel284_OnOff : 291|1@0+ (1,0) [0|1] ""  FLZCU
 SG_ ICC_LISD_Pixel285_OnOff : 292|1@0+ (1,0) [0|1] ""  FLZCU
 SG_ ICC_LISD_Pixel286_OnOff : 293|1@0+ (1,0) [0|1] ""  FLZCU
 SG_ ICC_LISD_Pixel287_OnOff : 294|1@0+ (1,0) [0|1] ""  FLZCU
 SG_ ICC_LISD_Pixel288_OnOff : 295|1@0+ (1,0) [0|1] ""  FLZCU
 SG_ ICC_LISD_Pixel289_OnOff : 296|1@0+ (1,0) [0|1] ""  FLZCU
 SG_ ICC_LISD_Pixel290_OnOff : 297|1@0+ (1,0) [0|1] ""  FLZCU
 SG_ ICC_LISD_Pixel291_OnOff : 298|1@0+ (1,0) [0|1] ""  FLZCU
 SG_ ICC_LISD_Pixel292_OnOff : 299|1@0+ (1,0) [0|1] ""  FLZCU
 SG_ ICC_LISD_Pixel293_OnOff : 300|1@0+ (1,0) [0|1] ""  FLZCU
 SG_ ICC_LISD_Pixel294_OnOff : 301|1@0+ (1,0) [0|1] ""  FLZCU
 SG_ ICC_LISD_Pixel295_OnOff : 302|1@0+ (1,0) [0|1] ""  FLZCU
 SG_ ICC_LISD_Pixel296_OnOff : 303|1@0+ (1,0) [0|1] ""  FLZCU
 SG_ ICC_LISD_Pixel297_OnOff : 304|1@0+ (1,0) [0|1] ""  FLZCU
 SG_ ICC_LISD_Pixel298_OnOff : 305|1@0+ (1,0) [0|1] ""  FLZCU
 SG_ ICC_LISD_Pixel299_OnOff : 306|1@0+ (1,0) [0|1] ""  FLZCU
 SG_ ICC_LISD_Pixel300_OnOff : 307|1@0+ (1,0) [0|1] ""  FLZCU
 SG_ ICC_LISD_Pixel301_OnOff : 308|1@0+ (1,0) [0|1] ""  FLZCU
 SG_ ICC_LISD_Pixel302_OnOff : 309|1@0+ (1,0) [0|1] ""  FLZCU
 SG_ ICC_LISD_Pixel303_OnOff : 310|1@0+ (1,0) [0|1] ""  FLZCU
 SG_ ICC_LISD_Pixel304_OnOff : 311|1@0+ (1,0) [0|1] ""  FLZCU
 SG_ ICC_LISD_Pixel305_OnOff : 312|1@0+ (1,0) [0|1] ""  FLZCU
 SG_ ICC_LISD_Pixel306_OnOff : 313|1@0+ (1,0) [0|1] ""  FLZCU
 SG_ ICC_LISD_Pixel307_OnOff : 314|1@0+ (1,0) [0|1] ""  FLZCU
 SG_ ICC_LISD_Pixel308_OnOff : 315|1@0+ (1,0) [0|1] ""  FLZCU
 SG_ ICC_LISD_Pixel309_OnOff : 316|1@0+ (1,0) [0|1] ""  FLZCU
 SG_ ICC_LISD_Pixel310_OnOff : 317|1@0+ (1,0) [0|1] ""  FLZCU
 SG_ ICC_LISD_Pixel311_OnOff : 318|1@0+ (1,0) [0|1] ""  FLZCU
 SG_ ICC_LISD_Pixel312_OnOff : 319|1@0+ (1,0) [0|1] ""  FLZCU
 SG_ ICC_LISD_Pixel313_OnOff : 320|1@0+ (1,0) [0|1] ""  FLZCU
 SG_ ICC_LISD_Pixel314_OnOff : 321|1@0+ (1,0) [0|1] ""  FLZCU
 SG_ ICC_LISD_Pixel315_OnOff : 322|1@0+ (1,0) [0|1] ""  FLZCU
 SG_ ICC_LISD_Pixel316_OnOff : 323|1@0+ (1,0) [0|1] ""  FLZCU
 SG_ ICC_LISD_Pixel317_OnOff : 324|1@0+ (1,0) [0|1] ""  FLZCU
 SG_ ICC_LISD_Pixel318_OnOff : 325|1@0+ (1,0) [0|1] ""  FLZCU
 SG_ ICC_LISD_Pixel319_OnOff : 326|1@0+ (1,0) [0|1] ""  FLZCU
 SG_ ICC_LISD_Pixel320_OnOff : 327|1@0+ (1,0) [0|1] ""  FLZCU
 SG_ ICC_LISD_Pixel321_OnOff : 328|1@0+ (1,0) [0|1] ""  FLZCU
 SG_ ICC_LISD_Pixel322_OnOff : 329|1@0+ (1,0) [0|1] ""  FLZCU
 SG_ ICC_LISD_Pixel323_OnOff : 330|1@0+ (1,0) [0|1] ""  FLZCU
 SG_ ICC_LISD_Pixel324_OnOff : 331|1@0+ (1,0) [0|1] ""  FLZCU
 SG_ ICC_LISD_Pixel325_OnOff : 332|1@0+ (1,0) [0|1] ""  FLZCU
 SG_ ICC_LISD_Pixel326_OnOff : 333|1@0+ (1,0) [0|1] ""  FLZCU
 SG_ ICC_LISD_Pixel327_OnOff : 334|1@0+ (1,0) [0|1] ""  FLZCU
 SG_ ICC_LISD_Pixel328_OnOff : 335|1@0+ (1,0) [0|1] ""  FLZCU
 SG_ ICC_LISD_Pixel329_OnOff : 336|1@0+ (1,0) [0|1] ""  FLZCU
 SG_ ICC_LISD_Pixel330_OnOff : 337|1@0+ (1,0) [0|1] ""  FLZCU
 SG_ ICC_LISD_Pixel331_OnOff : 338|1@0+ (1,0) [0|1] ""  FLZCU
 SG_ ICC_LISD_Pixel332_OnOff : 339|1@0+ (1,0) [0|1] ""  FLZCU
 SG_ ICC_LISD_Pixel333_OnOff : 340|1@0+ (1,0) [0|1] ""  FLZCU
 SG_ ICC_LISD_Pixel334_OnOff : 341|1@0+ (1,0) [0|1] ""  FLZCU
 SG_ ICC_LISD_Pixel335_OnOff : 342|1@0+ (1,0) [0|1] ""  FLZCU
 SG_ ICC_LISD_Pixel336_OnOff : 343|1@0+ (1,0) [0|1] ""  FLZCU
 SG_ ICC_LISD_Pixel337_OnOff : 344|1@0+ (1,0) [0|1] ""  FLZCU
 SG_ ICC_LISD_Pixel338_OnOff : 345|1@0+ (1,0) [0|1] ""  FLZCU
 SG_ ICC_LISD_Pixel339_OnOff : 346|1@0+ (1,0) [0|1] ""  FLZCU
 SG_ ICC_LISD_Pixel340_OnOff : 347|1@0+ (1,0) [0|1] ""  FLZCU
 SG_ ICC_LISD_Pixel341_OnOff : 348|1@0+ (1,0) [0|1] ""  FLZCU
 SG_ ICC_LISD_Pixel342_OnOff : 349|1@0+ (1,0) [0|1] ""  FLZCU
 SG_ ICC_LISD_Pixel343_OnOff : 350|1@0+ (1,0) [0|1] ""  FLZCU
 SG_ ICC_LISD_Pixel344_OnOff : 351|1@0+ (1,0) [0|1] ""  FLZCU
 SG_ ICC_LISD_Pixel345_OnOff : 352|1@0+ (1,0) [0|1] ""  FLZCU
 SG_ ICC_LISD_Pixel346_OnOff : 353|1@0+ (1,0) [0|1] ""  FLZCU
 SG_ ICC_LISD_Pixel347_OnOff : 354|1@0+ (1,0) [0|1] ""  FLZCU
 SG_ ICC_LISD_Pixel348_OnOff : 355|1@0+ (1,0) [0|1] ""  FLZCU
 SG_ ICC_LISD_Pixel349_OnOff : 356|1@0+ (1,0) [0|1] ""  FLZCU
 SG_ ICC_LISD_Pixel350_OnOff : 357|1@0+ (1,0) [0|1] ""  FLZCU
 SG_ ICC_LISD_Pixel351_OnOff : 358|1@0+ (1,0) [0|1] ""  FLZCU
 SG_ ICC_LISD_Pixel352_OnOff : 359|1@0+ (1,0) [0|1] ""  FLZCU
 SG_ ICC_LISD_Pixel353_OnOff : 360|1@0+ (1,0) [0|1] ""  FLZCU
 SG_ ICC_LISD_Pixel354_OnOff : 361|1@0+ (1,0) [0|1] ""  FLZCU
 SG_ ICC_LISD_Pixel355_OnOff : 362|1@0+ (1,0) [0|1] ""  FLZCU
 SG_ ICC_LISD_Pixel356_OnOff : 363|1@0+ (1,0) [0|1] ""  FLZCU
 SG_ ICC_LISD_Pixel357_OnOff : 364|1@0+ (1,0) [0|1] ""  FLZCU
 SG_ ICC_LISD_Pixel358_OnOff : 365|1@0+ (1,0) [0|1] ""  FLZCU
 SG_ ICC_LISD_Pixel359_OnOff : 366|1@0+ (1,0) [0|1] ""  FLZCU
 SG_ ICC_LISD_Pixel360_OnOff : 367|1@0+ (1,0) [0|1] ""  FLZCU
 SG_ ICC_LISD_Pixel361_OnOff : 368|1@0+ (1,0) [0|1] ""  FLZCU
 SG_ ICC_LISD_Pixel362_OnOff : 369|1@0+ (1,0) [0|1] ""  FLZCU
 SG_ ICC_LISD_Pixel363_OnOff : 370|1@0+ (1,0) [0|1] ""  FLZCU
 SG_ ICC_LISD_Pixel364_OnOff : 371|1@0+ (1,0) [0|1] ""  FLZCU
 SG_ ICC_LISD_Pixel365_OnOff : 372|1@0+ (1,0) [0|1] ""  FLZCU
 SG_ ICC_LISD_Pixel366_OnOff : 373|1@0+ (1,0) [0|1] ""  FLZCU
 SG_ ICC_LISD_Pixel367_OnOff : 374|1@0+ (1,0) [0|1] ""  FLZCU
 SG_ ICC_LISD_Pixel368_OnOff : 375|1@0+ (1,0) [0|1] ""  FLZCU
 SG_ ICC_LISD_Pixel369_OnOff : 376|1@0+ (1,0) [0|1] ""  FLZCU
 SG_ ICC_LISD_Pixel370_OnOff : 377|1@0+ (1,0) [0|1] ""  FLZCU
 SG_ ICC_LISD_Pixel371_OnOff : 378|1@0+ (1,0) [0|1] ""  FLZCU
 SG_ ICC_LISD_Pixel372_OnOff : 379|1@0+ (1,0) [0|1] ""  FLZCU
 SG_ ICC_LISD_Pixel373_OnOff : 380|1@0+ (1,0) [0|1] ""  FLZCU
 SG_ ICC_LISD_Pixel374_OnOff : 381|1@0+ (1,0) [0|1] ""  FLZCU
 SG_ ICC_LISD_Pixel375_OnOff : 382|1@0+ (1,0) [0|1] ""  FLZCU
 SG_ ICC_LISD_Pixel376_OnOff : 383|1@0+ (1,0) [0|1] ""  FLZCU
 SG_ ICC_LISD_Pixel377_OnOff : 384|1@0+ (1,0) [0|1] ""  FLZCU
 SG_ ICC_LISD_Pixel378_OnOff : 385|1@0+ (1,0) [0|1] ""  FLZCU
 SG_ ICC_LISD_Pixel379_OnOff : 386|1@0+ (1,0) [0|1] ""  FLZCU
 SG_ ICC_LISD_Pixel380_OnOff : 387|1@0+ (1,0) [0|1] ""  FLZCU
 SG_ ICC_LISD_Pixel381_OnOff : 388|1@0+ (1,0) [0|1] ""  FLZCU
 SG_ ICC_LISD_Pixel382_OnOff : 389|1@0+ (1,0) [0|1] ""  FLZCU
 SG_ ICC_LISD_Pixel383_OnOff : 390|1@0+ (1,0) [0|1] ""  FLZCU
 SG_ ICC_LISD_Pixel384_OnOff : 391|1@0+ (1,0) [0|1] ""  FLZCU
 SG_ ICC_LISD_Pixel385_OnOff : 392|1@0+ (1,0) [0|1] ""  FLZCU
 SG_ ICC_LISD_Pixel386_OnOff : 393|1@0+ (1,0) [0|1] ""  FLZCU
 SG_ ICC_LISD_Pixel387_OnOff : 394|1@0+ (1,0) [0|1] ""  FLZCU
 SG_ ICC_LISD_Pixel388_OnOff : 395|1@0+ (1,0) [0|1] ""  FLZCU
 SG_ ICC_LISD_Pixel389_OnOff : 396|1@0+ (1,0) [0|1] ""  FLZCU
 SG_ ICC_LISD_Pixel390_OnOff : 397|1@0+ (1,0) [0|1] ""  FLZCU
 SG_ ICC_LISD_Pixel391_OnOff : 398|1@0+ (1,0) [0|1] ""  FLZCU
 SG_ ICC_LISD_Pixel392_OnOff : 399|1@0+ (1,0) [0|1] ""  FLZCU
 SG_ ICC_LISD_Pixel393_OnOff : 400|1@0+ (1,0) [0|1] ""  FLZCU
 SG_ ICC_LISD_Pixel394_OnOff : 401|1@0+ (1,0) [0|1] ""  FLZCU
 SG_ ICC_LISD_Pixel395_OnOff : 402|1@0+ (1,0) [0|1] ""  FLZCU
 SG_ ICC_LISD_Pixel396_OnOff : 403|1@0+ (1,0) [0|1] ""  FLZCU
 SG_ ICC_LISD_Pixel397_OnOff : 404|1@0+ (1,0) [0|1] ""  FLZCU
 SG_ ICC_LISD_Pixel398_OnOff : 405|1@0+ (1,0) [0|1] ""  FLZCU
 SG_ ICC_LISD_Pixel399_OnOff : 406|1@0+ (1,0) [0|1] ""  FLZCU
 SG_ ICC_LISD_Pixel400_OnOff : 407|1@0+ (1,0) [0|1] ""  FLZCU
 SG_ ICC_LISD_Pixel401_OnOff : 408|1@0+ (1,0) [0|1] ""  FLZCU
 SG_ ICC_LISD_Pixel402_OnOff : 409|1@0+ (1,0) [0|1] ""  FLZCU
 SG_ ICC_LISD_Pixel403_OnOff : 410|1@0+ (1,0) [0|1] ""  FLZCU
 SG_ ICC_LISD_Pixel404_OnOff : 411|1@0+ (1,0) [0|1] ""  FLZCU
 SG_ ICC_LISD_Pixel405_OnOff : 412|1@0+ (1,0) [0|1] ""  FLZCU
 SG_ ICC_LISD_Pixel406_OnOff : 413|1@0+ (1,0) [0|1] ""  FLZCU
 SG_ ICC_LISD_Pixel407_OnOff : 414|1@0+ (1,0) [0|1] ""  FLZCU
 SG_ ICC_LISD_Pixel408_OnOff : 415|1@0+ (1,0) [0|1] ""  FLZCU
 SG_ ICC_LISD_Pixel409_OnOff : 416|1@0+ (1,0) [0|1] ""  FLZCU
 SG_ ICC_LISD_Pixel410_OnOff : 417|1@0+ (1,0) [0|1] ""  FLZCU
 SG_ ICC_LISD_Pixel411_OnOff : 418|1@0+ (1,0) [0|1] ""  FLZCU
 SG_ ICC_LISD_Pixel412_OnOff : 419|1@0+ (1,0) [0|1] ""  FLZCU
 SG_ ICC_LISD_Pixel413_OnOff : 420|1@0+ (1,0) [0|1] ""  FLZCU
 SG_ ICC_LISD_Pixel414_OnOff : 421|1@0+ (1,0) [0|1] ""  FLZCU
 SG_ ICC_LISD_Pixel415_OnOff : 422|1@0+ (1,0) [0|1] ""  FLZCU
 SG_ ICC_LISD_Pixel416_OnOff : 423|1@0+ (1,0) [0|1] ""  FLZCU
 SG_ ICC_LISD_Pixel417_OnOff : 424|1@0+ (1,0) [0|1] ""  FLZCU
 SG_ ICC_LISD_Pixel418_OnOff : 425|1@0+ (1,0) [0|1] ""  FLZCU
 SG_ ICC_LISD_Pixel419_OnOff : 426|1@0+ (1,0) [0|1] ""  FLZCU
 SG_ ICC_LISD_Pixel420_OnOff : 427|1@0+ (1,0) [0|1] ""  FLZCU
 SG_ ICC_LISD_Pixel421_OnOff : 428|1@0+ (1,0) [0|1] ""  FLZCU
 SG_ ICC_LISD_Pixel422_OnOff : 429|1@0+ (1,0) [0|1] ""  FLZCU
 SG_ ICC_LISD_Pixel423_OnOff : 430|1@0+ (1,0) [0|1] ""  FLZCU
 SG_ ICC_LISD_Pixel424_OnOff : 431|1@0+ (1,0) [0|1] ""  FLZCU
 SG_ ICC_LISD_Pixel425_OnOff : 432|1@0+ (1,0) [0|1] ""  FLZCU
 SG_ ICC_LISD_Pixel426_OnOff : 433|1@0+ (1,0) [0|1] ""  FLZCU
 SG_ ICC_LISD_Pixel427_OnOff : 434|1@0+ (1,0) [0|1] ""  FLZCU
 SG_ ICC_LISD_Pixel428_OnOff : 435|1@0+ (1,0) [0|1] ""  FLZCU
 SG_ ICC_LISD_Pixel429_OnOff : 436|1@0+ (1,0) [0|1] ""  FLZCU
 SG_ ICC_LISD_Pixel430_OnOff : 437|1@0+ (1,0) [0|1] ""  FLZCU
 SG_ ICC_LISD_Pixel431_OnOff : 438|1@0+ (1,0) [0|1] ""  FLZCU
 SG_ ICC_LISD_Pixel432_OnOff : 439|1@0+ (1,0) [0|1] ""  FLZCU
 SG_ ICC_LISD_Pixel433_OnOff : 440|1@0+ (1,0) [0|1] ""  FLZCU
 SG_ ICC_LISD_Pixel434_OnOff : 441|1@0+ (1,0) [0|1] ""  FLZCU
 SG_ ICC_LISD_Pixel435_OnOff : 442|1@0+ (1,0) [0|1] ""  FLZCU
 SG_ ICC_LISD_Pixel436_OnOff : 443|1@0+ (1,0) [0|1] ""  FLZCU
 SG_ ICC_LISD_Pixel437_OnOff : 444|1@0+ (1,0) [0|1] ""  FLZCU
 SG_ ICC_LISD_Pixel438_OnOff : 445|1@0+ (1,0) [0|1] ""  FLZCU
 SG_ ICC_LISD_Pixel439_OnOff : 446|1@0+ (1,0) [0|1] ""  FLZCU
 SG_ ICC_LISD_Pixel440_OnOff : 447|1@0+ (1,0) [0|1] ""  FLZCU
 SG_ ICC_LISD_Pixel441_OnOff : 448|1@0+ (1,0) [0|1] ""  FLZCU
 SG_ ICC_LISD_Pixel442_OnOff : 449|1@0+ (1,0) [0|1] ""  FLZCU
 SG_ ICC_LISD_Pixel443_OnOff : 450|1@0+ (1,0) [0|1] ""  FLZCU
 SG_ ICC_LISD_Pixel444_OnOff : 451|1@0+ (1,0) [0|1] ""  FLZCU
 SG_ ICC_LISD_Pixel445_OnOff : 452|1@0+ (1,0) [0|1] ""  FLZCU
 SG_ ICC_LISD_Pixel446_OnOff : 453|1@0+ (1,0) [0|1] ""  FLZCU
 SG_ ICC_LISD_Pixel447_OnOff : 454|1@0+ (1,0) [0|1] ""  FLZCU
 SG_ ICC_LISD_Pixel448_OnOff : 455|1@0+ (1,0) [0|1] ""  FLZCU
 SG_ ICC_LISD_Pixel449_OnOff : 456|1@0+ (1,0) [0|1] ""  FLZCU
 SG_ ICC_LISD_Pixel450_OnOff : 457|1@0+ (1,0) [0|1] ""  FLZCU
 SG_ ICC_LISD_Pixel451_OnOff : 458|1@0+ (1,0) [0|1] ""  FLZCU
 SG_ ICC_LISD_Pixel452_OnOff : 459|1@0+ (1,0) [0|1] ""  FLZCU
 SG_ ICC_LISD_Pixel453_OnOff : 460|1@0+ (1,0) [0|1] ""  FLZCU
 SG_ ICC_LISD_Pixel454_OnOff : 461|1@0+ (1,0) [0|1] ""  FLZCU
 SG_ ICC_LISD_Pixel455_OnOff : 462|1@0+ (1,0) [0|1] ""  FLZCU
 SG_ ICC_LISD_Pixel456_OnOff : 463|1@0+ (1,0) [0|1] ""  FLZCU
 SG_ ICC_LISD_Pixel457_OnOff : 464|1@0+ (1,0) [0|1] ""  FLZCU
 SG_ ICC_LISD_Pixel458_OnOff : 465|1@0+ (1,0) [0|1] ""  FLZCU
 SG_ ICC_LISD_Pixel459_OnOff : 466|1@0+ (1,0) [0|1] ""  FLZCU
 SG_ ICC_LISD_Pixel460_OnOff : 467|1@0+ (1,0) [0|1] ""  FLZCU
 SG_ ICC_LISD_Pixel461_OnOff : 468|1@0+ (1,0) [0|1] ""  FLZCU
 SG_ ICC_LISD_Pixel462_OnOff : 469|1@0+ (1,0) [0|1] ""  FLZCU
 SG_ ICC_LISD_Pixel463_OnOff : 470|1@0+ (1,0) [0|1] ""  FLZCU
 SG_ ICC_LISD_Pixel464_OnOff : 471|1@0+ (1,0) [0|1] ""  FLZCU
 SG_ ICC_LISD_Pixel465_OnOff : 472|1@0+ (1,0) [0|1] ""  FLZCU
 SG_ ICC_LISD_Pixel466_OnOff : 473|1@0+ (1,0) [0|1] ""  FLZCU
 SG_ ICC_LISD_Pixel467_OnOff : 474|1@0+ (1,0) [0|1] ""  FLZCU
 SG_ ICC_LISD_Pixel468_OnOff : 475|1@0+ (1,0) [0|1] ""  FLZCU
 SG_ ICC_LISD_Pixel469_OnOff : 476|1@0+ (1,0) [0|1] ""  FLZCU
 SG_ ICC_LISD_Pixel470_OnOff : 477|1@0+ (1,0) [0|1] ""  FLZCU
 SG_ ICC_LISD_Pixel471_OnOff : 478|1@0+ (1,0) [0|1] ""  FLZCU
 SG_ ICC_LISD_Pixel472_OnOff : 479|1@0+ (1,0) [0|1] ""  FLZCU
 SG_ ICC_LISD_Pixel473_OnOff : 480|1@0+ (1,0) [0|1] ""  FLZCU
 SG_ ICC_LISD_Pixel474_OnOff : 481|1@0+ (1,0) [0|1] ""  FLZCU
 SG_ ICC_LISD_Pixel475_OnOff : 482|1@0+ (1,0) [0|1] ""  FLZCU
 SG_ ICC_LISD_Pixel476_OnOff : 483|1@0+ (1,0) [0|1] ""  FLZCU
 SG_ ICC_LISD_Pixel477_OnOff : 484|1@0+ (1,0) [0|1] ""  FLZCU
 SG_ ICC_LISD_Pixel478_OnOff : 485|1@0+ (1,0) [0|1] ""  FLZCU
 SG_ ICC_LISD_Pixel479_OnOff : 486|1@0+ (1,0) [0|1] ""  FLZCU
 SG_ ICC_LISD_Pixel480_OnOff : 487|1@0+ (1,0) [0|1] ""  FLZCU
 SG_ ICC_LISD_Pixel481_OnOff : 488|1@0+ (1,0) [0|1] ""  FLZCU
 SG_ ICC_LISD_Pixel482_OnOff : 489|1@0+ (1,0) [0|1] ""  FLZCU
 SG_ ICC_LISD_Pixel483_OnOff : 490|1@0+ (1,0) [0|1] ""  FLZCU
 SG_ ICC_LISD_Pixel484_OnOff : 491|1@0+ (1,0) [0|1] ""  FLZCU
 SG_ ICC_LISD_Pixel485_OnOff : 492|1@0+ (1,0) [0|1] ""  FLZCU
 SG_ ICC_LISD_Pixel486_OnOff : 493|1@0+ (1,0) [0|1] ""  FLZCU
 SG_ ICC_LISD_Pixel487_OnOff : 494|1@0+ (1,0) [0|1] ""  FLZCU
 SG_ ICC_LISD_Pixel488_OnOff : 495|1@0+ (1,0) [0|1] ""  FLZCU
 SG_ ICC_LISD_Pixel489_OnOff : 496|1@0+ (1,0) [0|1] ""  FLZCU
 SG_ ICC_LISD_Pixel490_OnOff : 497|1@0+ (1,0) [0|1] ""  FLZCU
 SG_ ICC_LISD_Pixel491_OnOff : 498|1@0+ (1,0) [0|1] ""  FLZCU
 SG_ ICC_LISD_Pixel492_OnOff : 499|1@0+ (1,0) [0|1] ""  FLZCU
 SG_ ICC_LISD_Pixel493_OnOff : 500|1@0+ (1,0) [0|1] ""  FLZCU
 SG_ ICC_LISD_Pixel494_OnOff : 501|1@0+ (1,0) [0|1] ""  FLZCU
 SG_ ICC_LISD_Pixel495_OnOff : 502|1@0+ (1,0) [0|1] ""  FLZCU
 SG_ ICC_LISD_Pixel496_OnOff : 503|1@0+ (1,0) [0|1] ""  FLZCU
 SG_ ICC_LISD_Pixel497_OnOff : 504|1@0+ (1,0) [0|1] ""  FLZCU
 SG_ ICC_LISD_Pixel498_OnOff : 505|1@0+ (1,0) [0|1] ""  FLZCU
 SG_ ICC_LISD_Pixel499_OnOff : 506|1@0+ (1,0) [0|1] ""  FLZCU
 SG_ ICC_LISD_Pixel500_OnOff : 507|1@0+ (1,0) [0|1] ""  FLZCU
 SG_ ICC_LISD_Pixel501_OnOff : 508|1@0+ (1,0) [0|1] ""  FLZCU
 SG_ ICC_LISD_Pixel502_OnOff : 509|1@0+ (1,0) [0|1] ""  FLZCU
 SG_ ICC_LISD_Pixel503_OnOff : 510|1@0+ (1,0) [0|1] ""  FLZCU
 SG_ ICC_LISD_Pixel504_OnOff : 511|1@0+ (1,0) [0|1] ""  FLZCU

CM_ BO_ 1333 "触发一次发送三帧有效+三帧 Not Active";
CM_ SG_ 1333 ICC_SRFCmd "天窗开关设置
全开
全关
翘起";
CM_ SG_ 1333 ICC_SRFPercentCmd "手滑动开启天窗百分比";
CM_ SG_ 1333 ICC_SunshadeCmd "遮阳帘开关设置
全开
全关
一半";
CM_ SG_ 1333 ICC_SunshadePercentCmd "手滑动开启遮阳帘百分比";
CM_ SG_ 1333 ICC_CSunshadeReq "天幕遮阳帘开关设置";
CM_ SG_ 1333 ICC_CSunshadePercentReq "手滑动开启天幕遮阳帘百分比";
CM_ SG_ 1333 CSunshadeLearnedReq_535h "遮阳帘学习请求";
CM_ SG_ 1333 CSunshadePercentReq_535h "遮阳帘开度";
CM_ BO_ 1335 "触发一次发送三帧有效+三帧 Not Active";
CM_ SG_ 1335 ICC_SET_EPS_SteerReturnRmdSts "方向盘回正开关";
CM_ SG_ 1335 ICC_SET_MFSShake "方向盘震动开关";
CM_ SG_ 1335 ICC_DMS_1_DistractionLevel "方向盘震动等级调节";
CM_ SG_ 1335 ICC_SET_EPS_AsociWithDrvModSts "EPS与驾驶模式关联开关";
CM_ SG_ 1335 ICC_OverLoadWarnShieldSet "重量报警屏蔽软开关";
CM_ SG_ 1335 ICC_BSWReq "智能擦盘开启信号";
CM_ SG_ 1335 ICC_horizontalReq "露营找平软开关";
CM_ SG_ 1335 ICC_RolloverSetCmd "翻滚设置开关";
CM_ SG_ 1335 ICC_TrekThroughReq_537h "越野穿越开关";
CM_ SG_ 1335 ICC_InflateReq_537h "一键充气开关";
CM_ SG_ 1335 ICC_UndergroundModeReq_537h "地库模式开关";
CM_ SG_ 1335 ICC_SandABSSw_537h "沙地ABS模式-ABS状态请求";
CM_ SG_ 1335 ICC_SandABSCmd_537h "沙地ABS模式-开启请求";
CM_ SG_ 1335 ICC_EPBAUTOCmd_537h "熄火自动驻车
EPB AUTO开关
0x1:开关按钮点亮，功能开启
0x2:开关按钮熄灭，功能关闭";
CM_ SG_ 1335 ICC_SpeParkSet_537h "熄火移车/印尼驻车";
CM_ BO_ 1337 "触发一次发送三帧有效+三帧 Not Active";
CM_ SG_ 1337 ICC_SET_BT_ReduceWindSpeed "大屏设置蓝牙通话降低风速";
CM_ SG_ 1337 ICC_SET_IPM_FirstBlowing "夏日热风规避_大屏设置空调启动时第一口风";
CM_ SG_ 1337 ICC_SET_IPM_BlowerDelay "大屏设置车辆熄火空调鼓风机延时";
CM_ SG_ 1337 ICC_SET_CirculationInTunnels "大屏设置隧道内循环";
CM_ SG_ 1337 ICC_UVCLuminanceReq "大屏设置紫外线杀菌灯强度请求";
CM_ SG_ 1337 ICC_UVCControlReq "大屏设置紫外线杀菌灯";
CM_ SG_ 1337 ICC_CrossCountryCoolingReq "越野散热开关";
CM_ SG_ 1337 ICC_KeepWarmReq "恒温模式状态开关请求";
CM_ SG_ 1337 ICC_keepwarmSetTemperatureReq "恒温模式温度设置请求";
CM_ SG_ 1337 ICC_ParkingAirConditioning "驻车空调使能开关
ventilate通风";
CM_ SG_ 1337 ICC_CoolantFill_Req "冷却液加注开关请求";
CM_ SG_ 1337 ICC_FraganceLightoffReq "香氛氛围灯开关状态";
CM_ SG_ 1337 ICC_FraganceMemoffReq "香氛记忆开关状态";
CM_ SG_ 1337 ICC_TimingLevel "香氛定时等级";
CM_ SG_ 1337 ICC_CFSCycleLevel "香氛循环等级";
CM_ SG_ 1337 ICC_AirPurgeReminderReq "空气净化提醒开关请求";
CM_ SG_ 1337 ICC_TimedVentilationReq "大屏定时换气功能开关";
CM_ SG_ 1337 ICC_BiochemicalFuncReq "大屏生化功能开关";
CM_ SG_ 1337 ICC_ModeAdjustDisplaySts "空调模式";
CM_ SG_ 1337 ICC_PetModeSetTemperature_R_C "宠物模式前右空调温度设置";
CM_ SG_ 1337 ICC_PetmodeSetTemperature_L_C "宠物模式前左空调温度设置";
CM_ SG_ 1337 ICC_PetModeSetCirculationSts "宠物模式空调内外循环切换设置";
CM_ SG_ 1337 ICC_PetModeSetAutoKeySts "宠物模式空调自动模式设置";
CM_ SG_ 1337 ICC_PetModeSetCLMOn "宠物模式空调开关设置";
CM_ SG_ 1337 ICC_ISSFctCmd_539h "启停开关信号";
CM_ SG_ 1338 FMCU_ErrLvlDis "前驱动电机故障等级";
CM_ SG_ 1338 FMCU_SpdAct_EDR "前驱动电机实际转速";
CM_ BO_ 1341 "该报文为捷途在4.X平台上新增报文";
CM_ SG_ 1341 BMS_44_PackPowerRealTime "捷途新增动力电池包实时功率";
CM_ BO_ 1345 "捷途ID新增";
CM_ SG_ 1345 DVR_1_DVRFailReasons "DVR失效原因";
CM_ SG_ 1345 DVR_1_RecordSts "DVR普通录像状态";
CM_ SG_ 1345 DVR_1_Sdcard_Sts "DVR TF卡状态
0x0: Normal（正常）
0x1: Not inserted（TF卡未插入）
0x2: Filesystem unsupported（TF卡文件系统不支持）
0x3: Capacity unsupported（TF卡容量不支持）
0x4: Abnormal（TF卡异常）
0x5: Full（TF卡满）
0x6~0x7: Reserved";
CM_ BO_ 1349 "捷途ID新增";
CM_ SG_ 1349 SBOX_MSD_Res "MSD发送状态
0x0:inial
0x4:短信条数不够";
CM_ SG_ 1349 SBOX_Ecallphonenub_Res "通话状态";
CM_ BO_ 1351 "捷途ID新增";
CM_ SG_ 1351 SBOX_SetMsgTotal "当前短信总条数";
CM_ SG_ 1351 SBOX_SetMSDTotal "设置MSD短信阈值";
CM_ SG_ 1351 SBOX_SetCallTimeThreshold "设置通话总时长阈值";
CM_ SG_ 1351 SBOX_SetTodayCallTimeThreshold "设置当日通话时长阈值";
CM_ SG_ 1351 SBOX_SetCurretnCallTime "设置当前通话总时长";
CM_ SG_ 1351 SBOX_SetCurretnMsgThreshold "设置当前短信总条数";
CM_ SG_ 1351 SBOX_SetMsgTotalThreshold "设置短信总条数阈值";
CM_ SG_ 1351 SBOX_SetMsdThreshold "设置MSD短信阈值";
CM_ SG_ 1351 SBOX_SetCurrenMsdCnt "设置当前MSD短条数";
CM_ SG_ 1351 SBOX_SetCustomMsgThreshold "设置客户短信阈值";
CM_ SG_ 1351 SBOX_SetCurrentCustomMsgCnt "设置当前客户短信条数";
CM_ BO_ 1353 "捷途ID新增";
CM_ SG_ 1353 SBOX_ICC_MACReq "SBOX请求车机连接蓝牙";
CM_ SG_ 1353 SBOX_MAC_Req0 "本地MAC第0个字节";
CM_ SG_ 1353 SBOX_MAC_Req1 "本地MAC第1个字节";
CM_ SG_ 1353 SBOX_MAC_Req2 "本地MAC第2个字节";
CM_ SG_ 1353 SBOX_MAC_Req3 "本地MAC第3个字节";
CM_ SG_ 1353 SBOX_MAC_Req4 "本地MAC第4个字节";
CM_ SG_ 1353 SBOX_MAC_Req5 "本地MAC第5个字节";
CM_ SG_ 1354 ICC_SetMsgTotal "当前短信总条数";
CM_ SG_ 1354 ICC_SetMSDTotal "设置MSD短信阈值";
CM_ SG_ 1354 ICC_SetCallTimeThreshold "设置通话总时长阈值";
CM_ SG_ 1354 ICC_SetTodayCallTimeThreshold "设置当日通话时长阈值";
CM_ SG_ 1354 ICC_SetCurretnCallTime "设置当前通话总时长";
CM_ SG_ 1354 ICC_SetCurretnMsgThreshold "设置当前短信总条数";
CM_ SG_ 1354 ICC_SetMsgTotalThreshold "设置短信总条数阈值";
CM_ SG_ 1354 ICC_SetMsdThreshold "设置MSD短信阈值";
CM_ SG_ 1354 ICC_SetCurrenMsdCnt "设置当前MSD短条数";
CM_ SG_ 1354 ICC_SetCustomMsgThreshold "设置客户短信阈值";
CM_ SG_ 1354 ICC_SetCurrentCustomMsgCnt "设置当前客户短信条数";
CM_ SG_ 1356 ICC_flag "选择激活类型";
CM_ SG_ 1356 ICC_ActiveTsp_Req "车机发起SBOX端的TSP注册";
CM_ SG_ 1356 ICC_ActiveSim_Req "车机切换sbox sim卡激活与未激活状态";
CM_ SG_ 1356 ICC_GetMac_req "请求查询MAC地址";
CM_ SG_ 1356 ICC_GetIccid_Vin "查询VIN和ICCID请求";
CM_ SG_ 1356 ICC_Platform_Phonenub1 "平台号码第1个数（从最左边开始）";
CM_ SG_ 1356 ICC_Platform_Phonenub2 "平台号码第2个数";
CM_ SG_ 1356 ICC_Platform_Phonenub3 "平台号码第3个数";
CM_ SG_ 1356 ICC_Platform_Phonenub4 "平台号码第4个数";
CM_ SG_ 1356 ICC_Platform_Phonenub5 "平台号码第5个数";
CM_ SG_ 1356 ICC_Platform_Phonenub6 "平台号码第6个数";
CM_ SG_ 1356 ICC_Platform_Phonenub7 "平台号码第7个数";
CM_ SG_ 1356 ICC_Platform_Phonenub8 "平台号码第8个数";
CM_ SG_ 1356 ICC_Platform_Phonenub9 "平台号码第9个数";
CM_ SG_ 1356 ICC_Platform_Phonenub10 "平台号码第10个数";
CM_ SG_ 1356 ICC_Platform_Phonenub11 "平台号码第11个数";
CM_ SG_ 1356 ICC_Platform_Phonenub12 "平台号码第12个数";
CM_ SG_ 1356 ICC_Platform_Phonenub13 "平台号码第13个数";
CM_ SG_ 1356 ICC_Platform_Phonenub14 "平台号码第14个数";
CM_ SG_ 1356 ICC_Platform_Phonenub15 "平台号码第15个数";
CM_ SG_ 1356 ICC_Platform_Phonenub16 "平台号码第16个数";
CM_ SG_ 1356 ICC_Platform_Phonenub17 "平台号码第17个数";
CM_ SG_ 1356 ICC_Platform_Phonenub18 "平台号码第18个数";
CM_ SG_ 1356 ICC_Platform_Phonenub19 "平台号码第19个数";
CM_ SG_ 1356 ICC_Platform_Phonenub20 "平台号码第20个数";
CM_ SG_ 1356 ICC_Mac0 "车机MAC第0个字节";
CM_ SG_ 1356 ICC_Mac1 "车机MAC第1个字节";
CM_ SG_ 1356 ICC_Mac2 "车机MAC第2个字节";
CM_ SG_ 1356 ICC_Mac3 "车机MAC第3个字节";
CM_ SG_ 1356 ICC_Mac4 "车机MAC第4个字节";
CM_ SG_ 1356 ICC_Mac5 "车机MAC第5个字节";
CM_ SG_ 1356 ICC_GivePlatformNumber_Flag "平台号码是否有效";
CM_ SG_ 1356 ICC_Mac_Flag "车机蓝牙MAC是否有效";
CM_ BO_ 1358 "捷途ID新增";
CM_ SG_ 1358 SBOX_ActiveTsp_Res "TSP激活状态";
CM_ SG_ 1358 SBOX_ActiveSim_Res "SIM激活状态";
CM_ SG_ 1358 SBOX_GetPlatformNumberRes "平台号状态（有效，无效）";
CM_ SG_ 1358 SBOX_Mac_Res0 "本地MAC第0个字节";
CM_ SG_ 1358 SBOX_Mac_Res1 "本地MAC第1个字节";
CM_ SG_ 1358 SBOX_Mac_Res2 "本地MAC第2个字节";
CM_ SG_ 1358 SBOX_Mac_Res3 "本地MAC第3个字节";
CM_ SG_ 1358 SBOX_Mac_Res4 "本地MAC第4个字节";
CM_ SG_ 1358 SBOX_Mac_Res5 "本地MAC第5个字节";
CM_ SG_ 1358 SBOX_ICCId_Res0 "ICCID第0个字节（从左边开始）";
CM_ SG_ 1358 SBOX_ICCId_Res1 "ICCID第1个字节";
CM_ SG_ 1358 SBOX_ICCId_Res2 "ICCID第2个字节";
CM_ SG_ 1358 SBOX_ICCId_Res3 "ICCID第3个字节";
CM_ SG_ 1358 SBOX_ICCId_Res4 "ICCID第4个字节";
CM_ SG_ 1358 SBOX_ICCId_Res5 "ICCID第5个字节";
CM_ SG_ 1358 SBOX_ICCId_Res6 "ICCID第6个字节";
CM_ SG_ 1358 SBOX_ICCId_Res7 "ICCID第7个字节";
CM_ SG_ 1358 SBOX_ICCId_Res8 "ICCID第8个字节";
CM_ SG_ 1358 SBOX_ICCId_Res9 "ICCID第9个字节";
CM_ SG_ 1358 SBOX_ICCId_Res10 "ICCID第10个字节";
CM_ SG_ 1358 SBOX_ICCId_Res11 "ICCID第11个字节";
CM_ SG_ 1358 SBOX_ICCId_Res12 "ICCID第12个字节";
CM_ SG_ 1358 SBOX_ICCId_Res13 "ICCID第13个字节";
CM_ SG_ 1358 SBOX_ICCId_Res14 "ICCID第14个字节";
CM_ SG_ 1358 SBOX_ICCId_Res15 "ICCID第15个字节";
CM_ SG_ 1358 SBOX_ICCId_Res16 "ICCID第16个字节";
CM_ SG_ 1358 SBOX_ICCId_Res17 "ICCID第17个字节";
CM_ SG_ 1358 SBOX_ICCId_Res18 "ICCID第18个字节";
CM_ SG_ 1358 SBOX_ICCId_Res19 "ICCID第19个字节";
CM_ SG_ 1358 SBOX_Vin0 "VIN第0个字节（从左边开始）";
CM_ SG_ 1358 SBOX_Vin1 "VIN第1个字节('Z'-->5A(0101 1010))";
CM_ SG_ 1358 SBOX_Vin2 "VIN第2个字节";
CM_ SG_ 1358 SBOX_Vin3 "VIN第3个字节";
CM_ SG_ 1358 SBOX_Vin4 "VIN第4个字节";
CM_ SG_ 1358 SBOX_Vin5 "VIN第5个字节";
CM_ SG_ 1358 SBOX_Vin6 "VIN第6个字节";
CM_ SG_ 1358 SBOX_Vin7 "VIN第7个字节";
CM_ SG_ 1358 SBOX_Vin8 "VIN第8个字节";
CM_ SG_ 1358 SBOX_Vin9 "VIN第9个字节";
CM_ SG_ 1358 SBOX_Vin10 "VIN第10个字节";
CM_ SG_ 1358 SBOX_Vin11 "VIN第11个字节";
CM_ SG_ 1358 SBOX_Vin12 "VIN第12个字节";
CM_ SG_ 1358 SBOX_Vin13 "VIN第13个字节";
CM_ SG_ 1358 SBOX_Vin14 "VIN第14个字节";
CM_ SG_ 1358 SBOX_Vin15 "VIN第15个字节";
CM_ SG_ 1358 SBOX_Vin16 "VIN第16个字节";
CM_ BO_ 1360 "触发一次发送三帧有效+三帧 Not Active";
CM_ SG_ 1360 ICC_LISD_DisplaySwitch "自定义图片实时显示功能开关";
CM_ SG_ 1360 ICC_LISD_ParkingShowCMD "驻车动画开关（反馈已有）";
CM_ SG_ 1360 ICC_RISD_DisplaySwitch "自定义图片实时显示功能开关";
CM_ SG_ 1360 ICC_RISD_ParkingShowCMD "驻车动画开关（反馈已有）";
CM_ SG_ 1360 ICC_LogoParkingReq "前LOGO驻车点亮开关请求";
CM_ SG_ 1360 ICC_LogoChargingReq "前LOGO充电灯效开关请求";
CM_ SG_ 1360 ICC_DRLSw "日间行车灯软开关";
CM_ SG_ 1360 ICC_LISD_ParkingShowMod "LISD驻车动画模式";
CM_ SG_ 1360 ICC_RISD_ParkingShowMod "RISD驻车动画模式";
CM_ SG_ 1360 ICC_LogoColorReq "Logo灯颜色设置，1-256分别对应256种颜色";
CM_ SG_ 1360 ICC_MusicLampShowSW "0x0: 灯光秀总开关关闭
0x1: 灯光秀总开关开启";
CM_ SG_ 1360 ICC_PenetrationLampSetF "前贯穿灯软开关(D01P使用)";
CM_ SG_ 1360 ICC_XDriveMode "ICC通过视频流发给VCU进行驾驶模式设置
0x0:Not Active
0x1:无法判断 unidentifiable
0x2:普通1 Normal
0x3:雪地1 SNOW
0x4:泥地1 MUD
0x5:岩石1 ROCK
0x6:沙地1 SAND
0x7:水面1 WATER SURFACE
0x8：普通2 Normal
0x9:雪地2 SNOW
0xA:泥地2 MUD
0xB: 岩石2 ROCK
0xC:沙地2 SAND
0xD:水面2 WATER SURFACE
0xE:普通3 Normal
0xF:雪地3 SNOW
0x10:泥地3 MUD
0x11:岩石3 ROCK
0x12:沙地3 SAND";
CM_ SG_ 1360 ICC_DowWaringSw "盲区检测氛围灯联动闪烁开关";
CM_ SG_ 1360 ICC_CarSearhSetSwitchSts "寻车设置";
CM_ SG_ 1360 ICC_TDL_NightBright_SW_550h "夜间亮度开关";
CM_ BO_ 1361 "捷途ID新增";
CM_ SG_ 1361 EPC_LeftPedalSystem_Sts "左边电踏系统故障状态
0:正常
1:电压保护
2:系统故障
3:热保护
4:模式禁用
5:左边行驶保护
6:左边防夹保护";
CM_ SG_ 1361 EPC_RightPedalSystem_Sts "右边电踏系统状态
0:正常
1:电压保护
2:系统故障
3:热保护
4:模式禁用
5:右边行驶保护
6:右边防夹保护";
CM_ SG_ 1361 EPC_LeftPedalTimeTravel "左边电踏行程百分比";
CM_ SG_ 1361 EPC_RightPedalTimeTravel "右边电踏行程百分比";
CM_ SG_ 1361 EPC_RightPedalRealTime_Sts "右边电踏实时状态
0:无效
1:右边踏板收回到位
2:右边踏板收回中
3:右边踏板收回失败
4:右边踏板展开到位
5:右边踏板展开中
6:右边踏板展开失败";
CM_ SG_ 1361 EPC_LeftPedalBreakIce_Sts "左边电踏实时破冰状态
0:无效
1:左边正在破冰
2:左边破冰成功
3:左边破冰失败";
CM_ SG_ 1361 EPC_LeftPedalRealTime_Sts "左边电踏实时状态
0:无效
1:左边踏板收回到位
2:左边踏板收回中
3:左边踏板收回失败
4:左边踏板展开到位
5:左边踏板展开中
6:左边踏板展开失败";
CM_ SG_ 1361 EPC_RightPedalCmdStatus "右边踏板反馈信号
0x1:右边踏板展开
0x2:右边踏板回收
0x3:自动";
CM_ SG_ 1361 EPC_LeftPedalCmdStatus "左边踏板反馈信号
0x1:左踏板展开
0x2:左踏板回收
0x3:自动";
CM_ SG_ 1361 EPC_Enable_CmdStatus "电踏功能模式使能反馈
0x0:无效值
0x1:踏板功能使能
0x2:踏板功能禁能";
CM_ SG_ 1361 EPC_RightPedalBreakIce_Sts "右边电踏实时破冰状态
0:无效
1:右边正在破冰
2:右边破冰成功
3:右边破冰失败";
CM_ SG_ 1361 EPC_RightPedal3D_Sts "右电踏收回和展开反馈（前提自动打开）
0x1:踏板3D软开关开启
0x2:踏板3D软开关关闭";
CM_ SG_ 1361 EPC_LeftPedal3D_Sts "左电踏收回和展开反馈（前提自动打开）
0x1:踏板3D软开关开启
0x2:踏板3D软开关关闭";
CM_ SG_ 1362 ICC_LISD_RollingCounter "顺序计数器，确保图片数据按预期顺序发送、接收。";
CM_ SG_ 1362 ICC_LISD_Pixel1_OnOff "对应像素点的亮灭";
CM_ SG_ 1362 ICC_LISD_Pixel2_OnOff "对应像素点的亮灭";
CM_ SG_ 1362 ICC_LISD_Pixel3_OnOff "对应像素点的亮灭";
CM_ SG_ 1362 ICC_LISD_Pixel4_OnOff "对应像素点的亮灭";
CM_ SG_ 1362 ICC_LISD_Pixel5_OnOff "对应像素点的亮灭";
CM_ SG_ 1362 ICC_LISD_Pixel6_OnOff "对应像素点的亮灭";
CM_ SG_ 1362 ICC_LISD_Pixel7_OnOff "对应像素点的亮灭";
CM_ SG_ 1362 ICC_LISD_Pixel8_OnOff "对应像素点的亮灭";
CM_ SG_ 1362 ICC_LISD_Pixel9_OnOff "对应像素点的亮灭";
CM_ SG_ 1362 ICC_LISD_Pixel10_OnOff "对应像素点的亮灭";
CM_ SG_ 1362 ICC_LISD_Pixel11_OnOff "对应像素点的亮灭";
CM_ SG_ 1362 ICC_LISD_Pixel12_OnOff "对应像素点的亮灭";
CM_ SG_ 1362 ICC_LISD_Pixel13_OnOff "对应像素点的亮灭";
CM_ SG_ 1362 ICC_LISD_Pixel14_OnOff "对应像素点的亮灭";
CM_ SG_ 1362 ICC_LISD_Pixel15_OnOff "对应像素点的亮灭";
CM_ SG_ 1362 ICC_LISD_Pixel16_OnOff "对应像素点的亮灭";
CM_ SG_ 1362 ICC_LISD_Pixel17_OnOff "对应像素点的亮灭";
CM_ SG_ 1362 ICC_LISD_Pixel18_OnOff "对应像素点的亮灭";
CM_ SG_ 1362 ICC_LISD_Pixel19_OnOff "对应像素点的亮灭";
CM_ SG_ 1362 ICC_LISD_Pixel20_OnOff "对应像素点的亮灭";
CM_ SG_ 1362 ICC_LISD_Pixel21_OnOff "对应像素点的亮灭";
CM_ SG_ 1362 ICC_LISD_Pixel22_OnOff "对应像素点的亮灭";
CM_ SG_ 1362 ICC_LISD_Pixel23_OnOff "对应像素点的亮灭";
CM_ SG_ 1362 ICC_LISD_Pixel24_OnOff "对应像素点的亮灭";
CM_ SG_ 1362 ICC_LISD_Pixel25_OnOff "对应像素点的亮灭";
CM_ SG_ 1362 ICC_LISD_Pixel26_OnOff "对应像素点的亮灭";
CM_ SG_ 1362 ICC_LISD_Pixel27_OnOff "对应像素点的亮灭";
CM_ SG_ 1362 ICC_LISD_Pixel28_OnOff "对应像素点的亮灭";
CM_ SG_ 1362 ICC_LISD_Pixel29_OnOff "对应像素点的亮灭";
CM_ SG_ 1362 ICC_LISD_Pixel30_OnOff "对应像素点的亮灭";
CM_ SG_ 1362 ICC_LISD_Pixel31_OnOff "对应像素点的亮灭";
CM_ SG_ 1362 ICC_LISD_Pixel32_OnOff "对应像素点的亮灭";
CM_ SG_ 1362 ICC_LISD_Pixel33_OnOff "对应像素点的亮灭";
CM_ SG_ 1362 ICC_LISD_Pixel34_OnOff "对应像素点的亮灭";
CM_ SG_ 1362 ICC_LISD_Pixel35_OnOff "对应像素点的亮灭";
CM_ SG_ 1362 ICC_LISD_Pixel36_OnOff "对应像素点的亮灭";
CM_ SG_ 1362 ICC_LISD_Pixel37_OnOff "对应像素点的亮灭";
CM_ SG_ 1362 ICC_LISD_Pixel38_OnOff "对应像素点的亮灭";
CM_ SG_ 1362 ICC_LISD_Pixel39_OnOff "对应像素点的亮灭";
CM_ SG_ 1362 ICC_LISD_Pixel40_OnOff "对应像素点的亮灭";
CM_ SG_ 1362 ICC_LISD_Pixel41_OnOff "对应像素点的亮灭";
CM_ SG_ 1362 ICC_LISD_Pixel42_OnOff "对应像素点的亮灭";
CM_ SG_ 1362 ICC_LISD_Pixel43_OnOff "对应像素点的亮灭";
CM_ SG_ 1362 ICC_LISD_Pixel44_OnOff "对应像素点的亮灭";
CM_ SG_ 1362 ICC_LISD_Pixel45_OnOff "对应像素点的亮灭";
CM_ SG_ 1362 ICC_LISD_Pixel46_OnOff "对应像素点的亮灭";
CM_ SG_ 1362 ICC_LISD_Pixel47_OnOff "对应像素点的亮灭";
CM_ SG_ 1362 ICC_LISD_Pixel48_OnOff "对应像素点的亮灭";
CM_ SG_ 1362 ICC_LISD_Pixel49_OnOff "对应像素点的亮灭";
CM_ SG_ 1362 ICC_LISD_Pixel50_OnOff "对应像素点的亮灭";
CM_ SG_ 1362 ICC_LISD_Pixel51_OnOff "对应像素点的亮灭";
CM_ SG_ 1362 ICC_LISD_Pixel52_OnOff "对应像素点的亮灭";
CM_ SG_ 1362 ICC_LISD_Pixel53_OnOff "对应像素点的亮灭";
CM_ SG_ 1362 ICC_LISD_Pixel54_OnOff "对应像素点的亮灭";
CM_ SG_ 1362 ICC_LISD_Pixel55_OnOff "对应像素点的亮灭";
CM_ SG_ 1362 ICC_LISD_Pixel56_OnOff "对应像素点的亮灭";
CM_ SG_ 1362 ICC_LISD_Pixel57_OnOff "对应像素点的亮灭";
CM_ SG_ 1362 ICC_LISD_Pixel58_OnOff "对应像素点的亮灭";
CM_ SG_ 1362 ICC_LISD_Pixel59_OnOff "对应像素点的亮灭";
CM_ SG_ 1362 ICC_LISD_Pixel60_OnOff "对应像素点的亮灭";
CM_ SG_ 1362 ICC_LISD_Pixel61_OnOff "对应像素点的亮灭";
CM_ SG_ 1362 ICC_LISD_Pixel62_OnOff "对应像素点的亮灭";
CM_ SG_ 1362 ICC_LISD_Pixel63_OnOff "对应像素点的亮灭";
CM_ SG_ 1362 ICC_LISD_Pixel64_OnOff "对应像素点的亮灭";
CM_ SG_ 1362 ICC_LISD_Pixel65_OnOff "对应像素点的亮灭";
CM_ SG_ 1362 ICC_LISD_Pixel66_OnOff "对应像素点的亮灭";
CM_ SG_ 1362 ICC_LISD_Pixel67_OnOff "对应像素点的亮灭";
CM_ SG_ 1362 ICC_LISD_Pixel68_OnOff "对应像素点的亮灭";
CM_ SG_ 1362 ICC_LISD_Pixel69_OnOff "对应像素点的亮灭";
CM_ SG_ 1362 ICC_LISD_Pixel70_OnOff "对应像素点的亮灭";
CM_ SG_ 1362 ICC_LISD_Pixel71_OnOff "对应像素点的亮灭";
CM_ SG_ 1362 ICC_LISD_Pixel72_OnOff "对应像素点的亮灭";
CM_ SG_ 1362 ICC_LISD_Pixel73_OnOff "对应像素点的亮灭";
CM_ SG_ 1362 ICC_LISD_Pixel74_OnOff "对应像素点的亮灭";
CM_ SG_ 1362 ICC_LISD_Pixel75_OnOff "对应像素点的亮灭";
CM_ SG_ 1362 ICC_LISD_Pixel76_OnOff "对应像素点的亮灭";
CM_ SG_ 1362 ICC_LISD_Pixel77_OnOff "对应像素点的亮灭";
CM_ SG_ 1362 ICC_LISD_Pixel78_OnOff "对应像素点的亮灭";
CM_ SG_ 1362 ICC_LISD_Pixel79_OnOff "对应像素点的亮灭";
CM_ SG_ 1362 ICC_LISD_Pixel80_OnOff "对应像素点的亮灭";
CM_ SG_ 1362 ICC_LISD_Pixel81_OnOff "对应像素点的亮灭";
CM_ SG_ 1362 ICC_LISD_Pixel82_OnOff "对应像素点的亮灭";
CM_ SG_ 1362 ICC_LISD_Pixel83_OnOff "对应像素点的亮灭";
CM_ SG_ 1362 ICC_LISD_Pixel84_OnOff "对应像素点的亮灭";
CM_ SG_ 1362 ICC_LISD_Pixel85_OnOff "对应像素点的亮灭";
CM_ SG_ 1362 ICC_LISD_Pixel86_OnOff "对应像素点的亮灭";
CM_ SG_ 1362 ICC_LISD_Pixel87_OnOff "对应像素点的亮灭";
CM_ SG_ 1362 ICC_LISD_Pixel88_OnOff "对应像素点的亮灭";
CM_ SG_ 1362 ICC_LISD_Pixel89_OnOff "对应像素点的亮灭";
CM_ SG_ 1362 ICC_LISD_Pixel90_OnOff "对应像素点的亮灭";
CM_ SG_ 1362 ICC_LISD_Pixel91_OnOff "对应像素点的亮灭";
CM_ SG_ 1362 ICC_LISD_Pixel92_OnOff "对应像素点的亮灭";
CM_ SG_ 1362 ICC_LISD_Pixel93_OnOff "对应像素点的亮灭";
CM_ SG_ 1362 ICC_LISD_Pixel94_OnOff "对应像素点的亮灭";
CM_ SG_ 1362 ICC_LISD_Pixel95_OnOff "对应像素点的亮灭";
CM_ SG_ 1362 ICC_LISD_Pixel96_OnOff "对应像素点的亮灭";
CM_ SG_ 1362 ICC_LISD_Pixel97_OnOff "对应像素点的亮灭";
CM_ SG_ 1362 ICC_LISD_Pixel98_OnOff "对应像素点的亮灭";
CM_ SG_ 1362 ICC_LISD_Pixel99_OnOff "对应像素点的亮灭";
CM_ SG_ 1362 ICC_LISD_Pixel100_OnOff "对应像素点的亮灭";
CM_ SG_ 1362 ICC_LISD_Pixel101_OnOff "对应像素点的亮灭";
CM_ SG_ 1362 ICC_LISD_Pixel102_OnOff "对应像素点的亮灭";
CM_ SG_ 1362 ICC_LISD_Pixel103_OnOff "对应像素点的亮灭";
CM_ SG_ 1362 ICC_LISD_Pixel104_OnOff "对应像素点的亮灭";
CM_ SG_ 1362 ICC_LISD_Pixel105_OnOff "对应像素点的亮灭";
CM_ SG_ 1362 ICC_LISD_Pixel106_OnOff "对应像素点的亮灭";
CM_ SG_ 1362 ICC_LISD_Pixel107_OnOff "对应像素点的亮灭";
CM_ SG_ 1362 ICC_LISD_Pixel108_OnOff "对应像素点的亮灭";
CM_ SG_ 1362 ICC_LISD_Pixel109_OnOff "对应像素点的亮灭";
CM_ SG_ 1362 ICC_LISD_Pixel110_OnOff "对应像素点的亮灭";
CM_ SG_ 1362 ICC_LISD_Pixel111_OnOff "对应像素点的亮灭";
CM_ SG_ 1362 ICC_LISD_Pixel112_OnOff "对应像素点的亮灭";
CM_ SG_ 1362 ICC_LISD_Pixel113_OnOff "对应像素点的亮灭";
CM_ SG_ 1362 ICC_LISD_Pixel114_OnOff "对应像素点的亮灭";
CM_ SG_ 1362 ICC_LISD_Pixel115_OnOff "对应像素点的亮灭";
CM_ SG_ 1362 ICC_LISD_Pixel116_OnOff "对应像素点的亮灭";
CM_ SG_ 1362 ICC_LISD_Pixel117_OnOff "对应像素点的亮灭";
CM_ SG_ 1362 ICC_LISD_Pixel118_OnOff "对应像素点的亮灭";
CM_ SG_ 1362 ICC_LISD_Pixel119_OnOff "对应像素点的亮灭";
CM_ SG_ 1362 ICC_LISD_Pixel120_OnOff "对应像素点的亮灭";
CM_ SG_ 1362 ICC_LISD_Pixel121_OnOff "对应像素点的亮灭";
CM_ SG_ 1362 ICC_LISD_Pixel122_OnOff "对应像素点的亮灭";
CM_ SG_ 1362 ICC_LISD_Pixel123_OnOff "对应像素点的亮灭";
CM_ SG_ 1362 ICC_LISD_Pixel124_OnOff "对应像素点的亮灭";
CM_ SG_ 1362 ICC_LISD_Pixel125_OnOff "对应像素点的亮灭";
CM_ SG_ 1362 ICC_LISD_Pixel126_OnOff "对应像素点的亮灭";
CM_ SG_ 1362 ICC_LISD_Pixel127_OnOff "对应像素点的亮灭";
CM_ SG_ 1362 ICC_LISD_Pixel128_OnOff "对应像素点的亮灭";
CM_ SG_ 1362 ICC_LISD_Pixel129_OnOff "对应像素点的亮灭";
CM_ SG_ 1362 ICC_LISD_Pixel130_OnOff "对应像素点的亮灭";
CM_ SG_ 1362 ICC_LISD_Pixel131_OnOff "对应像素点的亮灭";
CM_ SG_ 1362 ICC_LISD_Pixel132_OnOff "对应像素点的亮灭";
CM_ SG_ 1362 ICC_LISD_Pixel133_OnOff "对应像素点的亮灭";
CM_ SG_ 1362 ICC_LISD_Pixel134_OnOff "对应像素点的亮灭";
CM_ SG_ 1362 ICC_LISD_Pixel135_OnOff "对应像素点的亮灭";
CM_ SG_ 1362 ICC_LISD_Pixel136_OnOff "对应像素点的亮灭";
CM_ SG_ 1362 ICC_LISD_Pixel137_OnOff "对应像素点的亮灭";
CM_ SG_ 1362 ICC_LISD_Pixel138_OnOff "对应像素点的亮灭";
CM_ SG_ 1362 ICC_LISD_Pixel139_OnOff "对应像素点的亮灭";
CM_ SG_ 1362 ICC_LISD_Pixel140_OnOff "对应像素点的亮灭";
CM_ SG_ 1362 ICC_LISD_Pixel141_OnOff "对应像素点的亮灭";
CM_ SG_ 1362 ICC_LISD_Pixel142_OnOff "对应像素点的亮灭";
CM_ SG_ 1362 ICC_LISD_Pixel143_OnOff "对应像素点的亮灭";
CM_ SG_ 1362 ICC_LISD_Pixel144_OnOff "对应像素点的亮灭";
CM_ SG_ 1362 ICC_LISD_Pixel145_OnOff "对应像素点的亮灭";
CM_ SG_ 1362 ICC_LISD_Pixel146_OnOff "对应像素点的亮灭";
CM_ SG_ 1362 ICC_LISD_Pixel147_OnOff "对应像素点的亮灭";
CM_ SG_ 1362 ICC_LISD_Pixel148_OnOff "对应像素点的亮灭";
CM_ SG_ 1362 ICC_LISD_Pixel149_OnOff "对应像素点的亮灭";
CM_ SG_ 1362 ICC_LISD_Pixel150_OnOff "对应像素点的亮灭";
CM_ SG_ 1362 ICC_LISD_Pixel151_OnOff "对应像素点的亮灭";
CM_ SG_ 1362 ICC_LISD_Pixel152_OnOff "对应像素点的亮灭";
CM_ SG_ 1362 ICC_LISD_Pixel153_OnOff "对应像素点的亮灭";
CM_ SG_ 1362 ICC_LISD_Pixel154_OnOff "对应像素点的亮灭";
CM_ SG_ 1362 ICC_LISD_Pixel155_OnOff "对应像素点的亮灭";
CM_ SG_ 1362 ICC_LISD_Pixel156_OnOff "对应像素点的亮灭";
CM_ SG_ 1362 ICC_LISD_Pixel157_OnOff "对应像素点的亮灭";
CM_ SG_ 1362 ICC_LISD_Pixel158_OnOff "对应像素点的亮灭";
CM_ SG_ 1362 ICC_LISD_Pixel159_OnOff "对应像素点的亮灭";
CM_ SG_ 1362 ICC_LISD_Pixel160_OnOff "对应像素点的亮灭";
CM_ SG_ 1362 ICC_LISD_Pixel161_OnOff "对应像素点的亮灭";
CM_ SG_ 1362 ICC_LISD_Pixel162_OnOff "对应像素点的亮灭";
CM_ SG_ 1362 ICC_LISD_Pixel163_OnOff "对应像素点的亮灭";
CM_ SG_ 1362 ICC_LISD_Pixel164_OnOff "对应像素点的亮灭";
CM_ SG_ 1362 ICC_LISD_Pixel165_OnOff "对应像素点的亮灭";
CM_ SG_ 1362 ICC_LISD_Pixel166_OnOff "对应像素点的亮灭";
CM_ SG_ 1362 ICC_LISD_Pixel167_OnOff "对应像素点的亮灭";
CM_ SG_ 1362 ICC_LISD_Pixel168_OnOff "对应像素点的亮灭";
CM_ SG_ 1362 ICC_LISD_Pixel169_OnOff "对应像素点的亮灭";
CM_ SG_ 1362 ICC_LISD_Pixel170_OnOff "对应像素点的亮灭";
CM_ SG_ 1362 ICC_LISD_Pixel171_OnOff "对应像素点的亮灭";
CM_ SG_ 1362 ICC_LISD_Pixel172_OnOff "对应像素点的亮灭";
CM_ SG_ 1362 ICC_LISD_Pixel173_OnOff "对应像素点的亮灭";
CM_ SG_ 1362 ICC_LISD_Pixel174_OnOff "对应像素点的亮灭";
CM_ SG_ 1362 ICC_LISD_Pixel175_OnOff "对应像素点的亮灭";
CM_ SG_ 1362 ICC_LISD_Pixel176_OnOff "对应像素点的亮灭";
CM_ SG_ 1362 ICC_LISD_Pixel177_OnOff "对应像素点的亮灭";
CM_ SG_ 1362 ICC_LISD_Pixel178_OnOff "对应像素点的亮灭";
CM_ SG_ 1362 ICC_LISD_Pixel179_OnOff "对应像素点的亮灭";
CM_ SG_ 1362 ICC_LISD_Pixel180_OnOff "对应像素点的亮灭";
CM_ SG_ 1362 ICC_LISD_Pixel181_OnOff "对应像素点的亮灭";
CM_ SG_ 1362 ICC_LISD_Pixel182_OnOff "对应像素点的亮灭";
CM_ SG_ 1362 ICC_LISD_Pixel183_OnOff "对应像素点的亮灭";
CM_ SG_ 1362 ICC_LISD_Pixel184_OnOff "对应像素点的亮灭";
CM_ SG_ 1362 ICC_LISD_Pixel185_OnOff "对应像素点的亮灭";
CM_ SG_ 1362 ICC_LISD_Pixel186_OnOff "对应像素点的亮灭";
CM_ SG_ 1362 ICC_LISD_Pixel187_OnOff "对应像素点的亮灭";
CM_ SG_ 1362 ICC_LISD_Pixel188_OnOff "对应像素点的亮灭";
CM_ SG_ 1362 ICC_LISD_Pixel189_OnOff "对应像素点的亮灭";
CM_ SG_ 1362 ICC_LISD_Pixel190_OnOff "对应像素点的亮灭";
CM_ SG_ 1362 ICC_LISD_Pixel191_OnOff "对应像素点的亮灭";
CM_ SG_ 1362 ICC_LISD_Pixel192_OnOff "对应像素点的亮灭";
CM_ SG_ 1362 ICC_LISD_Pixel193_OnOff "对应像素点的亮灭";
CM_ SG_ 1362 ICC_LISD_Pixel194_OnOff "对应像素点的亮灭";
CM_ SG_ 1362 ICC_LISD_Pixel195_OnOff "对应像素点的亮灭";
CM_ SG_ 1362 ICC_LISD_Pixel196_OnOff "对应像素点的亮灭";
CM_ SG_ 1362 ICC_LISD_Pixel197_OnOff "对应像素点的亮灭";
CM_ SG_ 1362 ICC_LISD_Pixel198_OnOff "对应像素点的亮灭";
CM_ SG_ 1362 ICC_LISD_Pixel199_OnOff "对应像素点的亮灭";
CM_ SG_ 1362 ICC_LISD_Pixel200_OnOff "对应像素点的亮灭";
CM_ SG_ 1362 ICC_LISD_Pixel201_OnOff "对应像素点的亮灭";
CM_ SG_ 1362 ICC_LISD_Pixel202_OnOff "对应像素点的亮灭";
CM_ SG_ 1362 ICC_LISD_Pixel203_OnOff "对应像素点的亮灭";
CM_ SG_ 1362 ICC_LISD_Pixel204_OnOff "对应像素点的亮灭";
CM_ SG_ 1362 ICC_LISD_Pixel205_OnOff "对应像素点的亮灭";
CM_ SG_ 1362 ICC_LISD_Pixel206_OnOff "对应像素点的亮灭";
CM_ SG_ 1362 ICC_LISD_Pixel207_OnOff "对应像素点的亮灭";
CM_ SG_ 1362 ICC_LISD_Pixel208_OnOff "对应像素点的亮灭";
CM_ SG_ 1362 ICC_LISD_Pixel209_OnOff "对应像素点的亮灭";
CM_ SG_ 1362 ICC_LISD_Pixel210_OnOff "对应像素点的亮灭";
CM_ SG_ 1362 ICC_LISD_Pixel211_OnOff "对应像素点的亮灭";
CM_ SG_ 1362 ICC_LISD_Pixel212_OnOff "对应像素点的亮灭";
CM_ SG_ 1362 ICC_LISD_Pixel213_OnOff "对应像素点的亮灭";
CM_ SG_ 1362 ICC_LISD_Pixel214_OnOff "对应像素点的亮灭";
CM_ SG_ 1362 ICC_LISD_Pixel215_OnOff "对应像素点的亮灭";
CM_ SG_ 1362 ICC_LISD_Pixel216_OnOff "对应像素点的亮灭";
CM_ SG_ 1362 ICC_LISD_Pixel217_OnOff "对应像素点的亮灭";
CM_ SG_ 1362 ICC_LISD_Pixel218_OnOff "对应像素点的亮灭";
CM_ SG_ 1362 ICC_LISD_Pixel219_OnOff "对应像素点的亮灭";
CM_ SG_ 1362 ICC_LISD_Pixel220_OnOff "对应像素点的亮灭";
CM_ SG_ 1362 ICC_LISD_Pixel221_OnOff "对应像素点的亮灭";
CM_ SG_ 1362 ICC_LISD_Pixel222_OnOff "对应像素点的亮灭";
CM_ SG_ 1362 ICC_LISD_Pixel223_OnOff "对应像素点的亮灭";
CM_ SG_ 1362 ICC_LISD_Pixel224_OnOff "对应像素点的亮灭";
CM_ SG_ 1362 ICC_LISD_Pixel225_OnOff "对应像素点的亮灭";
CM_ SG_ 1362 ICC_LISD_Pixel226_OnOff "对应像素点的亮灭";
CM_ SG_ 1362 ICC_LISD_Pixel227_OnOff "对应像素点的亮灭";
CM_ SG_ 1362 ICC_LISD_Pixel228_OnOff "对应像素点的亮灭";
CM_ SG_ 1362 ICC_LISD_Pixel229_OnOff "对应像素点的亮灭";
CM_ SG_ 1362 ICC_LISD_Pixel230_OnOff "对应像素点的亮灭";
CM_ SG_ 1362 ICC_LISD_Pixel231_OnOff "对应像素点的亮灭";
CM_ SG_ 1362 ICC_LISD_Pixel232_OnOff "对应像素点的亮灭";
CM_ SG_ 1362 ICC_LISD_Pixel233_OnOff "对应像素点的亮灭";
CM_ SG_ 1362 ICC_LISD_Pixel234_OnOff "对应像素点的亮灭";
CM_ SG_ 1362 ICC_LISD_Pixel235_OnOff "对应像素点的亮灭";
CM_ SG_ 1362 ICC_LISD_Pixel236_OnOff "对应像素点的亮灭";
CM_ SG_ 1362 ICC_LISD_Pixel237_OnOff "对应像素点的亮灭";
CM_ SG_ 1362 ICC_LISD_Pixel238_OnOff "对应像素点的亮灭";
CM_ SG_ 1362 ICC_LISD_Pixel239_OnOff "对应像素点的亮灭";
CM_ SG_ 1362 ICC_LISD_Pixel240_OnOff "对应像素点的亮灭";
CM_ SG_ 1362 ICC_LISD_Pixel241_OnOff "对应像素点的亮灭";
CM_ SG_ 1362 ICC_LISD_Pixel242_OnOff "对应像素点的亮灭";
CM_ SG_ 1362 ICC_LISD_Pixel243_OnOff "对应像素点的亮灭";
CM_ SG_ 1362 ICC_LISD_Pixel244_OnOff "对应像素点的亮灭";
CM_ SG_ 1362 ICC_LISD_Pixel245_OnOff "对应像素点的亮灭";
CM_ SG_ 1362 ICC_LISD_Pixel246_OnOff "对应像素点的亮灭";
CM_ SG_ 1362 ICC_LISD_Pixel247_OnOff "对应像素点的亮灭";
CM_ SG_ 1362 ICC_LISD_Pixel248_OnOff "对应像素点的亮灭";
CM_ SG_ 1362 ICC_LISD_Pixel249_OnOff "对应像素点的亮灭";
CM_ SG_ 1362 ICC_LISD_Pixel250_OnOff "对应像素点的亮灭";
CM_ SG_ 1362 ICC_LISD_Pixel251_OnOff "对应像素点的亮灭";
CM_ SG_ 1362 ICC_LISD_Pixel252_OnOff "对应像素点的亮灭";
CM_ SG_ 1362 ICC_LISD_Pixel253_OnOff "对应像素点的亮灭";
CM_ SG_ 1362 ICC_LISD_Pixel254_OnOff "对应像素点的亮灭";
CM_ SG_ 1362 ICC_LISD_Pixel255_OnOff "对应像素点的亮灭";
CM_ SG_ 1362 ICC_LISD_Pixel256_OnOff "对应像素点的亮灭";
CM_ SG_ 1362 ICC_LISD_Pixel257_OnOff "对应像素点的亮灭";
CM_ SG_ 1362 ICC_LISD_Pixel258_OnOff "对应像素点的亮灭";
CM_ SG_ 1362 ICC_LISD_Pixel259_OnOff "对应像素点的亮灭";
CM_ SG_ 1362 ICC_LISD_Pixel260_OnOff "对应像素点的亮灭";
CM_ SG_ 1362 ICC_LISD_Pixel261_OnOff "对应像素点的亮灭";
CM_ SG_ 1362 ICC_LISD_Pixel262_OnOff "对应像素点的亮灭";
CM_ SG_ 1362 ICC_LISD_Pixel263_OnOff "对应像素点的亮灭";
CM_ SG_ 1362 ICC_LISD_Pixel264_OnOff "对应像素点的亮灭";
CM_ SG_ 1362 ICC_LISD_Pixel265_OnOff "对应像素点的亮灭";
CM_ SG_ 1362 ICC_LISD_Pixel266_OnOff "对应像素点的亮灭";
CM_ SG_ 1362 ICC_LISD_Pixel267_OnOff "对应像素点的亮灭";
CM_ SG_ 1362 ICC_LISD_Pixel268_OnOff "对应像素点的亮灭";
CM_ SG_ 1362 ICC_LISD_Pixel269_OnOff "对应像素点的亮灭";
CM_ SG_ 1362 ICC_LISD_Pixel270_OnOff "对应像素点的亮灭";
CM_ SG_ 1362 ICC_LISD_Pixel271_OnOff "对应像素点的亮灭";
CM_ SG_ 1362 ICC_LISD_Pixel272_OnOff "对应像素点的亮灭";
CM_ SG_ 1362 ICC_LISD_Pixel273_OnOff "对应像素点的亮灭";
CM_ SG_ 1362 ICC_LISD_Pixel274_OnOff "对应像素点的亮灭";
CM_ SG_ 1362 ICC_LISD_Pixel275_OnOff "对应像素点的亮灭";
CM_ SG_ 1362 ICC_LISD_Pixel276_OnOff "对应像素点的亮灭";
CM_ SG_ 1362 ICC_LISD_Pixel277_OnOff "对应像素点的亮灭";
CM_ SG_ 1362 ICC_LISD_Pixel278_OnOff "对应像素点的亮灭";
CM_ SG_ 1362 ICC_LISD_Pixel279_OnOff "对应像素点的亮灭";
CM_ SG_ 1362 ICC_LISD_Pixel280_OnOff "对应像素点的亮灭";
CM_ SG_ 1362 ICC_LISD_Pixel281_OnOff "对应像素点的亮灭";
CM_ SG_ 1362 ICC_LISD_Pixel282_OnOff "对应像素点的亮灭";
CM_ SG_ 1362 ICC_LISD_Pixel283_OnOff "对应像素点的亮灭";
CM_ SG_ 1362 ICC_LISD_Pixel284_OnOff "对应像素点的亮灭";
CM_ SG_ 1362 ICC_LISD_Pixel285_OnOff "对应像素点的亮灭";
CM_ SG_ 1362 ICC_LISD_Pixel286_OnOff "对应像素点的亮灭";
CM_ SG_ 1362 ICC_LISD_Pixel287_OnOff "对应像素点的亮灭";
CM_ SG_ 1362 ICC_LISD_Pixel288_OnOff "对应像素点的亮灭";
CM_ SG_ 1362 ICC_LISD_Pixel289_OnOff "对应像素点的亮灭";
CM_ SG_ 1362 ICC_LISD_Pixel290_OnOff "对应像素点的亮灭";
CM_ SG_ 1362 ICC_LISD_Pixel291_OnOff "对应像素点的亮灭";
CM_ SG_ 1362 ICC_LISD_Pixel292_OnOff "对应像素点的亮灭";
CM_ SG_ 1362 ICC_LISD_Pixel293_OnOff "对应像素点的亮灭";
CM_ SG_ 1362 ICC_LISD_Pixel294_OnOff "对应像素点的亮灭";
CM_ SG_ 1362 ICC_LISD_Pixel295_OnOff "对应像素点的亮灭";
CM_ SG_ 1362 ICC_LISD_Pixel296_OnOff "对应像素点的亮灭";
CM_ SG_ 1362 ICC_LISD_Pixel297_OnOff "对应像素点的亮灭";
CM_ SG_ 1362 ICC_LISD_Pixel298_OnOff "对应像素点的亮灭";
CM_ SG_ 1362 ICC_LISD_Pixel299_OnOff "对应像素点的亮灭";
CM_ SG_ 1362 ICC_LISD_Pixel300_OnOff "对应像素点的亮灭";
CM_ SG_ 1362 ICC_LISD_Pixel301_OnOff "对应像素点的亮灭";
CM_ SG_ 1362 ICC_LISD_Pixel302_OnOff "对应像素点的亮灭";
CM_ SG_ 1362 ICC_LISD_Pixel303_OnOff "对应像素点的亮灭";
CM_ SG_ 1362 ICC_LISD_Pixel304_OnOff "对应像素点的亮灭";
CM_ SG_ 1362 ICC_LISD_Pixel305_OnOff "对应像素点的亮灭";
CM_ SG_ 1362 ICC_LISD_Pixel306_OnOff "对应像素点的亮灭";
CM_ SG_ 1362 ICC_LISD_Pixel307_OnOff "对应像素点的亮灭";
CM_ SG_ 1362 ICC_LISD_Pixel308_OnOff "对应像素点的亮灭";
CM_ SG_ 1362 ICC_LISD_Pixel309_OnOff "对应像素点的亮灭";
CM_ SG_ 1362 ICC_LISD_Pixel310_OnOff "对应像素点的亮灭";
CM_ SG_ 1362 ICC_LISD_Pixel311_OnOff "对应像素点的亮灭";
CM_ SG_ 1362 ICC_LISD_Pixel312_OnOff "对应像素点的亮灭";
CM_ SG_ 1362 ICC_LISD_Pixel313_OnOff "对应像素点的亮灭";
CM_ SG_ 1362 ICC_LISD_Pixel314_OnOff "对应像素点的亮灭";
CM_ SG_ 1362 ICC_LISD_Pixel315_OnOff "对应像素点的亮灭";
CM_ SG_ 1362 ICC_LISD_Pixel316_OnOff "对应像素点的亮灭";
CM_ SG_ 1362 ICC_LISD_Pixel317_OnOff "对应像素点的亮灭";
CM_ SG_ 1362 ICC_LISD_Pixel318_OnOff "对应像素点的亮灭";
CM_ SG_ 1362 ICC_LISD_Pixel319_OnOff "对应像素点的亮灭";
CM_ SG_ 1362 ICC_LISD_Pixel320_OnOff "对应像素点的亮灭";
CM_ SG_ 1362 ICC_LISD_Pixel321_OnOff "对应像素点的亮灭";
CM_ SG_ 1362 ICC_LISD_Pixel322_OnOff "对应像素点的亮灭";
CM_ SG_ 1362 ICC_LISD_Pixel323_OnOff "对应像素点的亮灭";
CM_ SG_ 1362 ICC_LISD_Pixel324_OnOff "对应像素点的亮灭";
CM_ SG_ 1362 ICC_LISD_Pixel325_OnOff "对应像素点的亮灭";
CM_ SG_ 1362 ICC_LISD_Pixel326_OnOff "对应像素点的亮灭";
CM_ SG_ 1362 ICC_LISD_Pixel327_OnOff "对应像素点的亮灭";
CM_ SG_ 1362 ICC_LISD_Pixel328_OnOff "对应像素点的亮灭";
CM_ SG_ 1362 ICC_LISD_Pixel329_OnOff "对应像素点的亮灭";
CM_ SG_ 1362 ICC_LISD_Pixel330_OnOff "对应像素点的亮灭";
CM_ SG_ 1362 ICC_LISD_Pixel331_OnOff "对应像素点的亮灭";
CM_ SG_ 1362 ICC_LISD_Pixel332_OnOff "对应像素点的亮灭";
CM_ SG_ 1362 ICC_LISD_Pixel333_OnOff "对应像素点的亮灭";
CM_ SG_ 1362 ICC_LISD_Pixel334_OnOff "对应像素点的亮灭";
CM_ SG_ 1362 ICC_LISD_Pixel335_OnOff "对应像素点的亮灭";
CM_ SG_ 1362 ICC_LISD_Pixel336_OnOff "对应像素点的亮灭";
CM_ SG_ 1362 ICC_LISD_Pixel337_OnOff "对应像素点的亮灭";
CM_ SG_ 1362 ICC_LISD_Pixel338_OnOff "对应像素点的亮灭";
CM_ SG_ 1362 ICC_LISD_Pixel339_OnOff "对应像素点的亮灭";
CM_ SG_ 1362 ICC_LISD_Pixel340_OnOff "对应像素点的亮灭";
CM_ SG_ 1362 ICC_LISD_Pixel341_OnOff "对应像素点的亮灭";
CM_ SG_ 1362 ICC_LISD_Pixel342_OnOff "对应像素点的亮灭";
CM_ SG_ 1362 ICC_LISD_Pixel343_OnOff "对应像素点的亮灭";
CM_ SG_ 1362 ICC_LISD_Pixel344_OnOff "对应像素点的亮灭";
CM_ SG_ 1362 ICC_LISD_Pixel345_OnOff "对应像素点的亮灭";
CM_ SG_ 1362 ICC_LISD_Pixel346_OnOff "对应像素点的亮灭";
CM_ SG_ 1362 ICC_LISD_Pixel347_OnOff "对应像素点的亮灭";
CM_ SG_ 1362 ICC_LISD_Pixel348_OnOff "对应像素点的亮灭";
CM_ SG_ 1362 ICC_LISD_Pixel349_OnOff "对应像素点的亮灭";
CM_ SG_ 1362 ICC_LISD_Pixel350_OnOff "对应像素点的亮灭";
CM_ SG_ 1362 ICC_LISD_Pixel351_OnOff "对应像素点的亮灭";
CM_ SG_ 1362 ICC_LISD_Pixel352_OnOff "对应像素点的亮灭";
CM_ SG_ 1362 ICC_LISD_Pixel353_OnOff "对应像素点的亮灭";
CM_ SG_ 1362 ICC_LISD_Pixel354_OnOff "对应像素点的亮灭";
CM_ SG_ 1362 ICC_LISD_Pixel355_OnOff "对应像素点的亮灭";
CM_ SG_ 1362 ICC_LISD_Pixel356_OnOff "对应像素点的亮灭";
CM_ SG_ 1362 ICC_LISD_Pixel357_OnOff "对应像素点的亮灭";
CM_ SG_ 1362 ICC_LISD_Pixel358_OnOff "对应像素点的亮灭";
CM_ SG_ 1362 ICC_LISD_Pixel359_OnOff "对应像素点的亮灭";
CM_ SG_ 1362 ICC_LISD_Pixel360_OnOff "对应像素点的亮灭";
CM_ SG_ 1362 ICC_LISD_Pixel361_OnOff "对应像素点的亮灭";
CM_ SG_ 1362 ICC_LISD_Pixel362_OnOff "对应像素点的亮灭";
CM_ SG_ 1362 ICC_LISD_Pixel363_OnOff "对应像素点的亮灭";
CM_ SG_ 1362 ICC_LISD_Pixel364_OnOff "对应像素点的亮灭";
CM_ SG_ 1362 ICC_LISD_Pixel365_OnOff "对应像素点的亮灭";
CM_ SG_ 1362 ICC_LISD_Pixel366_OnOff "对应像素点的亮灭";
CM_ SG_ 1362 ICC_LISD_Pixel367_OnOff "对应像素点的亮灭";
CM_ SG_ 1362 ICC_LISD_Pixel368_OnOff "对应像素点的亮灭";
CM_ SG_ 1362 ICC_LISD_Pixel369_OnOff "对应像素点的亮灭";
CM_ SG_ 1362 ICC_LISD_Pixel370_OnOff "对应像素点的亮灭";
CM_ SG_ 1362 ICC_LISD_Pixel371_OnOff "对应像素点的亮灭";
CM_ SG_ 1362 ICC_LISD_Pixel372_OnOff "对应像素点的亮灭";
CM_ SG_ 1362 ICC_LISD_Pixel373_OnOff "对应像素点的亮灭";
CM_ SG_ 1362 ICC_LISD_Pixel374_OnOff "对应像素点的亮灭";
CM_ SG_ 1362 ICC_LISD_Pixel375_OnOff "对应像素点的亮灭";
CM_ SG_ 1362 ICC_LISD_Pixel376_OnOff "对应像素点的亮灭";
CM_ SG_ 1362 ICC_LISD_Pixel377_OnOff "对应像素点的亮灭";
CM_ SG_ 1362 ICC_LISD_Pixel378_OnOff "对应像素点的亮灭";
CM_ SG_ 1362 ICC_LISD_Pixel379_OnOff "对应像素点的亮灭";
CM_ SG_ 1362 ICC_LISD_Pixel380_OnOff "对应像素点的亮灭";
CM_ SG_ 1362 ICC_LISD_Pixel381_OnOff "对应像素点的亮灭";
CM_ SG_ 1362 ICC_LISD_Pixel382_OnOff "对应像素点的亮灭";
CM_ SG_ 1362 ICC_LISD_Pixel383_OnOff "对应像素点的亮灭";
CM_ SG_ 1362 ICC_LISD_Pixel384_OnOff "对应像素点的亮灭";
CM_ SG_ 1362 ICC_LISD_Pixel385_OnOff "对应像素点的亮灭";
CM_ SG_ 1362 ICC_LISD_Pixel386_OnOff "对应像素点的亮灭";
CM_ SG_ 1362 ICC_LISD_Pixel387_OnOff "对应像素点的亮灭";
CM_ SG_ 1362 ICC_LISD_Pixel388_OnOff "对应像素点的亮灭";
CM_ SG_ 1362 ICC_LISD_Pixel389_OnOff "对应像素点的亮灭";
CM_ SG_ 1362 ICC_LISD_Pixel390_OnOff "对应像素点的亮灭";
CM_ SG_ 1362 ICC_LISD_Pixel391_OnOff "对应像素点的亮灭";
CM_ SG_ 1362 ICC_LISD_Pixel392_OnOff "对应像素点的亮灭";
CM_ SG_ 1362 ICC_LISD_Pixel393_OnOff "对应像素点的亮灭";
CM_ SG_ 1362 ICC_LISD_Pixel394_OnOff "对应像素点的亮灭";
CM_ SG_ 1362 ICC_LISD_Pixel395_OnOff "对应像素点的亮灭";
CM_ SG_ 1362 ICC_LISD_Pixel396_OnOff "对应像素点的亮灭";
CM_ SG_ 1362 ICC_LISD_Pixel397_OnOff "对应像素点的亮灭";
CM_ SG_ 1362 ICC_LISD_Pixel398_OnOff "对应像素点的亮灭";
CM_ SG_ 1362 ICC_LISD_Pixel399_OnOff "对应像素点的亮灭";
CM_ SG_ 1362 ICC_LISD_Pixel400_OnOff "对应像素点的亮灭";
CM_ SG_ 1362 ICC_LISD_Pixel401_OnOff "对应像素点的亮灭";
CM_ SG_ 1362 ICC_LISD_Pixel402_OnOff "对应像素点的亮灭";
CM_ SG_ 1362 ICC_LISD_Pixel403_OnOff "对应像素点的亮灭";
CM_ SG_ 1362 ICC_LISD_Pixel404_OnOff "对应像素点的亮灭";
CM_ SG_ 1362 ICC_LISD_Pixel405_OnOff "对应像素点的亮灭";
CM_ SG_ 1362 ICC_LISD_Pixel406_OnOff "对应像素点的亮灭";
CM_ SG_ 1362 ICC_LISD_Pixel407_OnOff "对应像素点的亮灭";
CM_ SG_ 1362 ICC_LISD_Pixel408_OnOff "对应像素点的亮灭";
CM_ SG_ 1362 ICC_LISD_Pixel409_OnOff "对应像素点的亮灭";
CM_ SG_ 1362 ICC_LISD_Pixel410_OnOff "对应像素点的亮灭";
CM_ SG_ 1362 ICC_LISD_Pixel411_OnOff "对应像素点的亮灭";
CM_ SG_ 1362 ICC_LISD_Pixel412_OnOff "对应像素点的亮灭";
CM_ SG_ 1362 ICC_LISD_Pixel413_OnOff "对应像素点的亮灭";
CM_ SG_ 1362 ICC_LISD_Pixel414_OnOff "对应像素点的亮灭";
CM_ SG_ 1362 ICC_LISD_Pixel415_OnOff "对应像素点的亮灭";
CM_ SG_ 1362 ICC_LISD_Pixel416_OnOff "对应像素点的亮灭";
CM_ SG_ 1362 ICC_LISD_Pixel417_OnOff "对应像素点的亮灭";
CM_ SG_ 1362 ICC_LISD_Pixel418_OnOff "对应像素点的亮灭";
CM_ SG_ 1362 ICC_LISD_Pixel419_OnOff "对应像素点的亮灭";
CM_ SG_ 1362 ICC_LISD_Pixel420_OnOff "对应像素点的亮灭";
CM_ SG_ 1362 ICC_LISD_Pixel421_OnOff "对应像素点的亮灭";
CM_ SG_ 1362 ICC_LISD_Pixel422_OnOff "对应像素点的亮灭";
CM_ SG_ 1362 ICC_LISD_Pixel423_OnOff "对应像素点的亮灭";
CM_ SG_ 1362 ICC_LISD_Pixel424_OnOff "对应像素点的亮灭";
CM_ SG_ 1362 ICC_LISD_Pixel425_OnOff "对应像素点的亮灭";
CM_ SG_ 1362 ICC_LISD_Pixel426_OnOff "对应像素点的亮灭";
CM_ SG_ 1362 ICC_LISD_Pixel427_OnOff "对应像素点的亮灭";
CM_ SG_ 1362 ICC_LISD_Pixel428_OnOff "对应像素点的亮灭";
CM_ SG_ 1362 ICC_LISD_Pixel429_OnOff "对应像素点的亮灭";
CM_ SG_ 1362 ICC_LISD_Pixel430_OnOff "对应像素点的亮灭";
CM_ SG_ 1362 ICC_LISD_Pixel431_OnOff "对应像素点的亮灭";
CM_ SG_ 1362 ICC_LISD_Pixel432_OnOff "对应像素点的亮灭";
CM_ SG_ 1362 ICC_LISD_Pixel433_OnOff "对应像素点的亮灭";
CM_ SG_ 1362 ICC_LISD_Pixel434_OnOff "对应像素点的亮灭";
CM_ SG_ 1362 ICC_LISD_Pixel435_OnOff "对应像素点的亮灭";
CM_ SG_ 1362 ICC_LISD_Pixel436_OnOff "对应像素点的亮灭";
CM_ SG_ 1362 ICC_LISD_Pixel437_OnOff "对应像素点的亮灭";
CM_ SG_ 1362 ICC_LISD_Pixel438_OnOff "对应像素点的亮灭";
CM_ SG_ 1362 ICC_LISD_Pixel439_OnOff "对应像素点的亮灭";
CM_ SG_ 1362 ICC_LISD_Pixel440_OnOff "对应像素点的亮灭";
CM_ SG_ 1362 ICC_LISD_Pixel441_OnOff "对应像素点的亮灭";
CM_ SG_ 1362 ICC_LISD_Pixel442_OnOff "对应像素点的亮灭";
CM_ SG_ 1362 ICC_LISD_Pixel443_OnOff "对应像素点的亮灭";
CM_ SG_ 1362 ICC_LISD_Pixel444_OnOff "对应像素点的亮灭";
CM_ SG_ 1362 ICC_LISD_Pixel445_OnOff "对应像素点的亮灭";
CM_ SG_ 1362 ICC_LISD_Pixel446_OnOff "对应像素点的亮灭";
CM_ SG_ 1362 ICC_LISD_Pixel447_OnOff "对应像素点的亮灭";
CM_ SG_ 1362 ICC_LISD_Pixel448_OnOff "对应像素点的亮灭";
CM_ SG_ 1362 ICC_LISD_Pixel449_OnOff "对应像素点的亮灭";
CM_ SG_ 1362 ICC_LISD_Pixel450_OnOff "对应像素点的亮灭";
CM_ SG_ 1362 ICC_LISD_Pixel451_OnOff "对应像素点的亮灭";
CM_ SG_ 1362 ICC_LISD_Pixel452_OnOff "对应像素点的亮灭";
CM_ SG_ 1362 ICC_LISD_Pixel453_OnOff "对应像素点的亮灭";
CM_ SG_ 1362 ICC_LISD_Pixel454_OnOff "对应像素点的亮灭";
CM_ SG_ 1362 ICC_LISD_Pixel455_OnOff "对应像素点的亮灭";
CM_ SG_ 1362 ICC_LISD_Pixel456_OnOff "对应像素点的亮灭";
CM_ SG_ 1362 ICC_LISD_Pixel457_OnOff "对应像素点的亮灭";
CM_ SG_ 1362 ICC_LISD_Pixel458_OnOff "对应像素点的亮灭";
CM_ SG_ 1362 ICC_LISD_Pixel459_OnOff "对应像素点的亮灭";
CM_ SG_ 1362 ICC_LISD_Pixel460_OnOff "对应像素点的亮灭";
CM_ SG_ 1362 ICC_LISD_Pixel461_OnOff "对应像素点的亮灭";
CM_ SG_ 1362 ICC_LISD_Pixel462_OnOff "对应像素点的亮灭";
CM_ SG_ 1362 ICC_LISD_Pixel463_OnOff "对应像素点的亮灭";
CM_ SG_ 1362 ICC_LISD_Pixel464_OnOff "对应像素点的亮灭";
CM_ SG_ 1362 ICC_LISD_Pixel465_OnOff "对应像素点的亮灭";
CM_ SG_ 1362 ICC_LISD_Pixel466_OnOff "对应像素点的亮灭";
CM_ SG_ 1362 ICC_LISD_Pixel467_OnOff "对应像素点的亮灭";
CM_ SG_ 1362 ICC_LISD_Pixel468_OnOff "对应像素点的亮灭";
CM_ SG_ 1362 ICC_LISD_Pixel469_OnOff "对应像素点的亮灭";
CM_ SG_ 1362 ICC_LISD_Pixel470_OnOff "对应像素点的亮灭";
CM_ SG_ 1362 ICC_LISD_Pixel471_OnOff "对应像素点的亮灭";
CM_ SG_ 1362 ICC_LISD_Pixel472_OnOff "对应像素点的亮灭";
CM_ SG_ 1362 ICC_LISD_Pixel473_OnOff "对应像素点的亮灭";
CM_ SG_ 1362 ICC_LISD_Pixel474_OnOff "对应像素点的亮灭";
CM_ SG_ 1362 ICC_LISD_Pixel475_OnOff "对应像素点的亮灭";
CM_ SG_ 1362 ICC_LISD_Pixel476_OnOff "对应像素点的亮灭";
CM_ SG_ 1362 ICC_LISD_Pixel477_OnOff "对应像素点的亮灭";
CM_ SG_ 1362 ICC_LISD_Pixel478_OnOff "对应像素点的亮灭";
CM_ SG_ 1362 ICC_LISD_Pixel479_OnOff "对应像素点的亮灭";
CM_ SG_ 1362 ICC_LISD_Pixel480_OnOff "对应像素点的亮灭";
CM_ SG_ 1362 ICC_LISD_Pixel481_OnOff "对应像素点的亮灭";
CM_ SG_ 1362 ICC_LISD_Pixel482_OnOff "对应像素点的亮灭";
CM_ SG_ 1362 ICC_LISD_Pixel483_OnOff "对应像素点的亮灭";
CM_ SG_ 1362 ICC_LISD_Pixel484_OnOff "对应像素点的亮灭";
CM_ SG_ 1362 ICC_LISD_Pixel485_OnOff "对应像素点的亮灭";
CM_ SG_ 1362 ICC_LISD_Pixel486_OnOff "对应像素点的亮灭";
CM_ SG_ 1362 ICC_LISD_Pixel487_OnOff "对应像素点的亮灭";
CM_ SG_ 1362 ICC_LISD_Pixel488_OnOff "对应像素点的亮灭";
CM_ SG_ 1362 ICC_LISD_Pixel489_OnOff "对应像素点的亮灭";
CM_ SG_ 1362 ICC_LISD_Pixel490_OnOff "对应像素点的亮灭";
CM_ SG_ 1362 ICC_LISD_Pixel491_OnOff "对应像素点的亮灭";
CM_ SG_ 1362 ICC_LISD_Pixel492_OnOff "对应像素点的亮灭";
CM_ SG_ 1362 ICC_LISD_Pixel493_OnOff "对应像素点的亮灭";
CM_ SG_ 1362 ICC_LISD_Pixel494_OnOff "对应像素点的亮灭";
CM_ SG_ 1362 ICC_LISD_Pixel495_OnOff "对应像素点的亮灭";
CM_ SG_ 1362 ICC_LISD_Pixel496_OnOff "对应像素点的亮灭";
CM_ SG_ 1362 ICC_LISD_Pixel497_OnOff "对应像素点的亮灭";
CM_ SG_ 1362 ICC_LISD_Pixel498_OnOff "对应像素点的亮灭";
CM_ SG_ 1362 ICC_LISD_Pixel499_OnOff "对应像素点的亮灭";
CM_ SG_ 1362 ICC_LISD_Pixel500_OnOff "对应像素点的亮灭";
CM_ SG_ 1362 ICC_LISD_Pixel501_OnOff "对应像素点的亮灭";
CM_ SG_ 1362 ICC_LISD_Pixel502_OnOff "对应像素点的亮灭";
CM_ SG_ 1362 ICC_LISD_Pixel503_OnOff "对应像素点的亮灭";
CM_ SG_ 1362 ICC_LISD_Pixel504_OnOff "对应像素点的亮灭";
BA_DEF_ SG_  "ASIL" ENUM  "QM","A","B","C","D";
BA_DEF_ SG_  "E2EDataLength" INT 0 65535;
BA_DEF_ SG_  "GenSigInactiveValue" HEX 0 80000000;
BA_DEF_ SG_  "GenSigInvalidValue" HEX 0 281474976710655;
BA_DEF_ SG_  "GenSigStartValue" HEX 0 80000000;
BA_DEF_ SG_  "GenSigSendType" ENUM  "Cyclic","OnWrite","OnWriteWithRepetition","OnChange","OnChangeWithRepetition","IfActive","IfActiveWithRepetition","NoSigSendType";
BA_DEF_ BO_  "CANFD_BRS" ENUM  "0","1";
BA_DEF_ BO_  "DiagRequest" ENUM  "No","Yes";
BA_DEF_ BO_  "DiagResponse" ENUM  "No","Yes";
BA_DEF_ BO_  "DiagState" ENUM  "No","Yes";
BA_DEF_ BO_  "DiagUudtResponse" ENUM  "True","False";
BA_DEF_ BO_  "GenMsgCycleTime" INT 0 65535;
BA_DEF_ BO_  "GenMsgCycleTimeFast" INT 0 65535;
BA_DEF_ BO_  "GenMsgDelayTime" INT 0 65535;
BA_DEF_ BO_  "GenMsgILSupport" ENUM  "No","Yes";
BA_DEF_ BO_  "GenMsgNrOfRepetition" INT 0 255;
BA_DEF_ BO_  "GenMsgSendType" ENUM  "Cyclic","Event","IfActive","CE","CA","NoMsgSendType";
BA_DEF_ BO_  "MsgType" ENUM  "IL","NM","DIAG","APPL";
BA_DEF_ BO_  "NmAsrMessage" ENUM  "No","Yes";
BA_DEF_ BO_  "SCP_AuthInfoTxLength" INT 9 512;
BA_DEF_ BO_  "SCP_FreshnessValueLength" INT 0 512;
BA_DEF_ BO_  "SCP_FreshnessValueTxLength" INT 0 512;
BA_DEF_ BO_  "VFrameFormat" ENUM  "StandardCAN","ExtendedCAN","reserved","J1939PG","reserved","reserved","reserved","reserved","reserved","reserved","reserved","reserved","reserved","reserved","StandardCAN_FD","ExtendedCAN_FD";
BA_DEF_DEF_  "ASIL" "QM";
BA_DEF_DEF_  "E2EDataLength" 64;
BA_DEF_DEF_  "GenSigInactiveValue" 0;
BA_DEF_DEF_  "GenSigInvalidValue" 0;
BA_DEF_DEF_  "GenSigStartValue" 0;
BA_DEF_DEF_  "GenSigSendType" "NoSigSendType";
BA_DEF_DEF_  "CANFD_BRS" "1";
BA_DEF_DEF_  "DiagRequest" "No";
BA_DEF_DEF_  "DiagResponse" "No";
BA_DEF_DEF_  "DiagState" "No";
BA_DEF_DEF_  "DiagUudtResponse" "True";
BA_DEF_DEF_  "GenMsgCycleTime" 0;
BA_DEF_DEF_  "GenMsgCycleTimeFast" 0;
BA_DEF_DEF_  "GenMsgDelayTime" 0;
BA_DEF_DEF_  "GenMsgILSupport" "Yes";
BA_DEF_DEF_  "GenMsgNrOfRepetition" 0;
BA_DEF_DEF_  "GenMsgSendType" "Cyclic";
BA_DEF_DEF_  "MsgType" "IL";
BA_DEF_DEF_  "NmAsrMessage" "No";
BA_DEF_DEF_  "SCP_AuthInfoTxLength" 28;
BA_DEF_DEF_  "SCP_FreshnessValueLength" 48;
BA_DEF_DEF_  "SCP_FreshnessValueTxLength" 4;
BA_DEF_DEF_  "VFrameFormat" "J1939PG";
BA_ "GenMsgSendType" BO_ 1333 1;
BA_ "GenMsgCycleTimeFast" BO_ 1333 100;
BA_ "GenMsgDelayTime" BO_ 1333 5;
BA_ "GenMsgNrOfRepetition" BO_ 1333 2;
BA_ "VFrameFormat" BO_ 1333 14;
BA_ "GenMsgSendType" BO_ 1335 3;
BA_ "GenMsgCycleTimeFast" BO_ 1335 20;
BA_ "GenMsgDelayTime" BO_ 1335 5;
BA_ "GenMsgCycleTime" BO_ 1335 100;
BA_ "GenMsgNrOfRepetition" BO_ 1335 2;
BA_ "VFrameFormat" BO_ 1335 14;
BA_ "GenMsgSendType" BO_ 1337 1;
BA_ "GenMsgCycleTimeFast" BO_ 1337 100;
BA_ "GenMsgDelayTime" BO_ 1337 5;
BA_ "GenMsgNrOfRepetition" BO_ 1337 2;
BA_ "VFrameFormat" BO_ 1337 14;
BA_ "GenMsgCycleTime" BO_ 1338 500;
BA_ "VFrameFormat" BO_ 1338 14;
BA_ "GenMsgCycleTime" BO_ 1341 100;
BA_ "VFrameFormat" BO_ 1341 14;
BA_ "GenMsgSendType" BO_ 1345 3;
BA_ "GenMsgCycleTimeFast" BO_ 1345 50;
BA_ "GenMsgDelayTime" BO_ 1345 5;
BA_ "GenMsgCycleTime" BO_ 1345 100;
BA_ "GenMsgNrOfRepetition" BO_ 1345 3;
BA_ "VFrameFormat" BO_ 1345 14;
BA_ "GenMsgSendType" BO_ 1349 1;
BA_ "GenMsgCycleTimeFast" BO_ 1349 100;
BA_ "GenMsgDelayTime" BO_ 1349 5;
BA_ "GenMsgNrOfRepetition" BO_ 1349 3;
BA_ "VFrameFormat" BO_ 1349 14;
BA_ "GenMsgSendType" BO_ 1351 1;
BA_ "GenMsgCycleTimeFast" BO_ 1351 100;
BA_ "GenMsgDelayTime" BO_ 1351 5;
BA_ "GenMsgNrOfRepetition" BO_ 1351 3;
BA_ "VFrameFormat" BO_ 1351 14;
BA_ "GenMsgSendType" BO_ 1353 1;
BA_ "GenMsgCycleTimeFast" BO_ 1353 100;
BA_ "GenMsgDelayTime" BO_ 1353 5;
BA_ "GenMsgNrOfRepetition" BO_ 1353 3;
BA_ "VFrameFormat" BO_ 1353 14;
BA_ "GenMsgSendType" BO_ 1354 1;
BA_ "GenMsgCycleTimeFast" BO_ 1354 100;
BA_ "GenMsgDelayTime" BO_ 1354 5;
BA_ "GenMsgNrOfRepetition" BO_ 1354 2;
BA_ "VFrameFormat" BO_ 1354 14;
BA_ "GenMsgSendType" BO_ 1356 1;
BA_ "GenMsgCycleTimeFast" BO_ 1356 100;
BA_ "GenMsgDelayTime" BO_ 1356 5;
BA_ "GenMsgNrOfRepetition" BO_ 1356 2;
BA_ "VFrameFormat" BO_ 1356 14;
BA_ "GenMsgSendType" BO_ 1358 1;
BA_ "GenMsgCycleTimeFast" BO_ 1358 100;
BA_ "GenMsgDelayTime" BO_ 1358 5;
BA_ "GenMsgNrOfRepetition" BO_ 1358 3;
BA_ "VFrameFormat" BO_ 1358 14;
BA_ "GenMsgSendType" BO_ 1360 3;
BA_ "GenMsgCycleTimeFast" BO_ 1360 100;
BA_ "GenMsgDelayTime" BO_ 1360 5;
BA_ "GenMsgCycleTime" BO_ 1360 100;
BA_ "GenMsgNrOfRepetition" BO_ 1360 2;
BA_ "VFrameFormat" BO_ 1360 14;
BA_ "GenMsgCycleTime" BO_ 1361 100;
BA_ "VFrameFormat" BO_ 1361 14;
BA_ "GenMsgSendType" BO_ 1362 1;
BA_ "GenMsgCycleTimeFast" BO_ 1362 100;
BA_ "GenMsgDelayTime" BO_ 1362 5;
BA_ "GenMsgNrOfRepetition" BO_ 1362 2;
BA_ "VFrameFormat" BO_ 1362 14;
BA_ "GenSigSendType" SG_ 1333 ICC_SRFCmd 2;
BA_ "GenSigSendType" SG_ 1333 ICC_SRFPercentCmd 2;
BA_ "GenSigSendType" SG_ 1333 ICC_SunshadeCmd 2;
BA_ "GenSigSendType" SG_ 1333 ICC_SunshadePercentCmd 2;
BA_ "GenSigSendType" SG_ 1333 ICC_CSunshadeReq 2;
BA_ "GenSigSendType" SG_ 1333 ICC_CSunshadePercentReq 2;
BA_ "GenSigSendType" SG_ 1333 CSunshadeLearnedReq_535h 2;
BA_ "GenSigSendType" SG_ 1333 CSunshadePercentReq_535h 2;
BA_ "GenSigSendType" SG_ 1335 ICC_SET_EPS_SteerReturnRmdSts 2;
BA_ "GenSigSendType" SG_ 1335 ICC_SET_MFSShake 2;
BA_ "GenSigSendType" SG_ 1335 ICC_DMS_1_DistractionLevel 2;
BA_ "GenSigSendType" SG_ 1335 ICC_SET_EPS_AsociWithDrvModSts 2;
BA_ "GenSigSendType" SG_ 1335 ICC_OverLoadWarnShieldSet 2;
BA_ "GenSigSendType" SG_ 1335 ICC_BSWReq 2;
BA_ "GenSigSendType" SG_ 1335 ICC_horizontalReq 2;
BA_ "GenSigSendType" SG_ 1335 ICC_RolloverSetCmd 2;
BA_ "ASIL" SG_ 1335 ICC_RolloverSetCmd 1;
BA_ "GenSigSendType" SG_ 1335 ICC_TrekThroughReq_537h 2;
BA_ "GenSigSendType" SG_ 1335 ICC_InflateReq_537h 2;
BA_ "GenSigSendType" SG_ 1335 ICC_UndergroundModeReq_537h 2;
BA_ "GenSigSendType" SG_ 1335 ICC_SandABSSw_537h 2;
BA_ "GenSigSendType" SG_ 1335 ICC_SandABSCmd_537h 2;
BA_ "GenSigSendType" SG_ 1335 ICC_EPBAUTOCmd_537h 2;
BA_ "GenSigSendType" SG_ 1335 ICC_SpeParkSet_537h 2;
BA_ "GenSigSendType" SG_ 1337 ICC_SET_BT_ReduceWindSpeed 2;
BA_ "GenSigSendType" SG_ 1337 ICC_SET_IPM_FirstBlowing 2;
BA_ "GenSigSendType" SG_ 1337 ICC_SET_IPM_BlowerDelay 2;
BA_ "GenSigSendType" SG_ 1337 ICC_SET_CirculationInTunnels 2;
BA_ "GenSigSendType" SG_ 1337 ICC_UVCLuminanceReq 2;
BA_ "GenSigSendType" SG_ 1337 ICC_UVCControlReq 2;
BA_ "GenSigSendType" SG_ 1337 ICC_CrossCountryCoolingReq 2;
BA_ "GenSigSendType" SG_ 1337 ICC_KeepWarmReq 2;
BA_ "GenSigSendType" SG_ 1337 ICC_keepwarmSetTemperatureReq 2;
BA_ "GenSigSendType" SG_ 1337 ICC_ParkingAirConditioning 2;
BA_ "GenSigSendType" SG_ 1337 ICC_CoolantFill_Req 2;
BA_ "GenSigSendType" SG_ 1337 ICC_FraganceLightoffReq 2;
BA_ "GenSigSendType" SG_ 1337 ICC_FraganceMemoffReq 2;
BA_ "GenSigSendType" SG_ 1337 ICC_TimingLevel 2;
BA_ "GenSigSendType" SG_ 1337 ICC_CFSCycleLevel 2;
BA_ "GenSigSendType" SG_ 1337 ICC_AirPurgeReminderReq 2;
BA_ "GenSigSendType" SG_ 1337 ICC_TimedVentilationReq 2;
BA_ "GenSigSendType" SG_ 1337 ICC_BiochemicalFuncReq 2;
BA_ "GenSigSendType" SG_ 1337 ICC_ModeAdjustDisplaySts 2;
BA_ "GenSigStartValue" SG_ 1337 ICC_ModeAdjustDisplaySts 5;
BA_ "GenSigSendType" SG_ 1337 ICC_PetModeSetTemperature_R_C 2;
BA_ "GenSigStartValue" SG_ 1337 ICC_PetModeSetTemperature_R_C 31;
BA_ "GenSigInvalidValue" SG_ 1337 ICC_PetModeSetTemperature_R_C 31;
BA_ "GenSigSendType" SG_ 1337 ICC_PetmodeSetTemperature_L_C 2;
BA_ "GenSigStartValue" SG_ 1337 ICC_PetmodeSetTemperature_L_C 31;
BA_ "GenSigInvalidValue" SG_ 1337 ICC_PetmodeSetTemperature_L_C 31;
BA_ "GenSigSendType" SG_ 1337 ICC_PetModeSetCirculationSts 2;
BA_ "GenSigSendType" SG_ 1337 ICC_PetModeSetAutoKeySts 2;
BA_ "GenSigSendType" SG_ 1337 ICC_PetModeSetCLMOn 2;
BA_ "GenSigSendType" SG_ 1337 ICC_ISSFctCmd_539h 2;
BA_ "GenSigSendType" SG_ 1338 FMCU_ErrLvlDis 0;
BA_ "GenSigSendType" SG_ 1338 FMCU_SpdAct_EDR 0;
BA_ "GenSigStartValue" SG_ 1338 FMCU_SpdAct_EDR 32767;
BA_ "GenSigInvalidValue" SG_ 1338 FMCU_SpdAct_EDR 65535;
BA_ "GenSigSendType" SG_ 1341 BMS_44_PackPowerRealTime 0;
BA_ "GenSigStartValue" SG_ 1341 BMS_44_PackPowerRealTime 10240;
BA_ "GenSigInvalidValue" SG_ 1341 BMS_44_PackPowerRealTime 16383;
BA_ "GenSigSendType" SG_ 1345 DVR_1_DVRFailReasons 2;
BA_ "GenSigSendType" SG_ 1345 DVR_1_RecordSts 2;
BA_ "GenSigSendType" SG_ 1345 DVR_1_Sdcard_Sts 2;
BA_ "GenSigSendType" SG_ 1349 SBOX_MSD_Res 2;
BA_ "GenSigSendType" SG_ 1349 SBOX_Ecallphonenub_Res 2;
BA_ "GenSigSendType" SG_ 1351 SBOX_SetMsgTotal 1;
BA_ "GenSigSendType" SG_ 1351 SBOX_SetMSDTotal 1;
BA_ "GenSigSendType" SG_ 1351 SBOX_SetCallTimeThreshold 1;
BA_ "GenSigSendType" SG_ 1351 SBOX_SetTodayCallTimeThreshold 1;
BA_ "GenSigSendType" SG_ 1351 SBOX_SetCurretnCallTime 1;
BA_ "GenSigSendType" SG_ 1351 SBOX_SetCurretnMsgThreshold 1;
BA_ "GenSigSendType" SG_ 1351 SBOX_SetMsgTotalThreshold 1;
BA_ "GenSigSendType" SG_ 1351 SBOX_SetMsdThreshold 1;
BA_ "GenSigSendType" SG_ 1351 SBOX_SetCurrenMsdCnt 1;
BA_ "GenSigSendType" SG_ 1351 SBOX_SetCustomMsgThreshold 1;
BA_ "GenSigSendType" SG_ 1351 SBOX_SetCurrentCustomMsgCnt 1;
BA_ "GenSigSendType" SG_ 1353 SBOX_ICC_MACReq 1;
BA_ "GenSigSendType" SG_ 1353 SBOX_MAC_Req0 1;
BA_ "GenSigSendType" SG_ 1353 SBOX_MAC_Req1 1;
BA_ "GenSigSendType" SG_ 1353 SBOX_MAC_Req2 1;
BA_ "GenSigSendType" SG_ 1353 SBOX_MAC_Req3 1;
BA_ "GenSigSendType" SG_ 1353 SBOX_MAC_Req4 1;
BA_ "GenSigSendType" SG_ 1353 SBOX_MAC_Req5 1;
BA_ "GenSigSendType" SG_ 1354 ICC_SetMsgTotal 1;
BA_ "GenSigSendType" SG_ 1354 ICC_SetMSDTotal 1;
BA_ "GenSigSendType" SG_ 1354 ICC_SetCallTimeThreshold 1;
BA_ "GenSigSendType" SG_ 1354 ICC_SetTodayCallTimeThreshold 1;
BA_ "GenSigSendType" SG_ 1354 ICC_SetCurretnCallTime 1;
BA_ "GenSigSendType" SG_ 1354 ICC_SetCurretnMsgThreshold 1;
BA_ "GenSigSendType" SG_ 1354 ICC_SetMsgTotalThreshold 1;
BA_ "GenSigSendType" SG_ 1354 ICC_SetMsdThreshold 1;
BA_ "GenSigSendType" SG_ 1354 ICC_SetCurrenMsdCnt 1;
BA_ "GenSigSendType" SG_ 1354 ICC_SetCustomMsgThreshold 1;
BA_ "GenSigSendType" SG_ 1354 ICC_SetCurrentCustomMsgCnt 1;
BA_ "GenSigSendType" SG_ 1356 ICC_flag 1;
BA_ "GenSigSendType" SG_ 1356 ICC_ActiveTsp_Req 1;
BA_ "GenSigSendType" SG_ 1356 ICC_ActiveSim_Req 1;
BA_ "GenSigSendType" SG_ 1356 ICC_GetMac_req 1;
BA_ "GenSigSendType" SG_ 1356 ICC_GetIccid_Vin 1;
BA_ "GenSigSendType" SG_ 1356 ICC_Platform_Phonenub1 1;
BA_ "GenSigSendType" SG_ 1356 ICC_Platform_Phonenub2 1;
BA_ "GenSigSendType" SG_ 1356 ICC_Platform_Phonenub3 1;
BA_ "GenSigSendType" SG_ 1356 ICC_Platform_Phonenub4 1;
BA_ "GenSigSendType" SG_ 1356 ICC_Platform_Phonenub5 1;
BA_ "GenSigSendType" SG_ 1356 ICC_Platform_Phonenub6 1;
BA_ "GenSigSendType" SG_ 1356 ICC_Platform_Phonenub7 1;
BA_ "GenSigSendType" SG_ 1356 ICC_Platform_Phonenub8 1;
BA_ "GenSigSendType" SG_ 1356 ICC_Platform_Phonenub9 1;
BA_ "GenSigSendType" SG_ 1356 ICC_Platform_Phonenub10 1;
BA_ "GenSigSendType" SG_ 1356 ICC_Platform_Phonenub11 1;
BA_ "GenSigSendType" SG_ 1356 ICC_Platform_Phonenub12 1;
BA_ "GenSigSendType" SG_ 1356 ICC_Platform_Phonenub13 1;
BA_ "GenSigSendType" SG_ 1356 ICC_Platform_Phonenub14 1;
BA_ "GenSigSendType" SG_ 1356 ICC_Platform_Phonenub15 1;
BA_ "GenSigSendType" SG_ 1356 ICC_Platform_Phonenub16 1;
BA_ "GenSigSendType" SG_ 1356 ICC_Platform_Phonenub17 1;
BA_ "GenSigSendType" SG_ 1356 ICC_Platform_Phonenub18 1;
BA_ "GenSigSendType" SG_ 1356 ICC_Platform_Phonenub19 1;
BA_ "GenSigSendType" SG_ 1356 ICC_Platform_Phonenub20 1;
BA_ "GenSigSendType" SG_ 1356 ICC_Mac0 1;
BA_ "GenSigSendType" SG_ 1356 ICC_Mac1 1;
BA_ "GenSigSendType" SG_ 1356 ICC_Mac2 1;
BA_ "GenSigSendType" SG_ 1356 ICC_Mac3 1;
BA_ "GenSigSendType" SG_ 1356 ICC_Mac4 1;
BA_ "GenSigSendType" SG_ 1356 ICC_Mac5 1;
BA_ "GenSigSendType" SG_ 1356 ICC_GivePlatformNumber_Flag 1;
BA_ "GenSigSendType" SG_ 1356 ICC_Mac_Flag 1;
BA_ "GenSigSendType" SG_ 1358 SBOX_ActiveTsp_Res 1;
BA_ "GenSigSendType" SG_ 1358 SBOX_ActiveSim_Res 1;
BA_ "GenSigSendType" SG_ 1358 SBOX_GetPlatformNumberRes 1;
BA_ "GenSigSendType" SG_ 1358 SBOX_Mac_Res0 1;
BA_ "GenSigSendType" SG_ 1358 SBOX_Mac_Res1 1;
BA_ "GenSigSendType" SG_ 1358 SBOX_Mac_Res2 1;
BA_ "GenSigSendType" SG_ 1358 SBOX_Mac_Res3 1;
BA_ "GenSigSendType" SG_ 1358 SBOX_Mac_Res4 1;
BA_ "GenSigSendType" SG_ 1358 SBOX_Mac_Res5 1;
BA_ "GenSigSendType" SG_ 1358 SBOX_ICCId_Res0 1;
BA_ "GenSigSendType" SG_ 1358 SBOX_ICCId_Res1 1;
BA_ "GenSigSendType" SG_ 1358 SBOX_ICCId_Res2 1;
BA_ "GenSigSendType" SG_ 1358 SBOX_ICCId_Res3 1;
BA_ "GenSigSendType" SG_ 1358 SBOX_ICCId_Res4 1;
BA_ "GenSigSendType" SG_ 1358 SBOX_ICCId_Res5 1;
BA_ "GenSigSendType" SG_ 1358 SBOX_ICCId_Res6 1;
BA_ "GenSigSendType" SG_ 1358 SBOX_ICCId_Res7 1;
BA_ "GenSigSendType" SG_ 1358 SBOX_ICCId_Res8 1;
BA_ "GenSigSendType" SG_ 1358 SBOX_ICCId_Res9 1;
BA_ "GenSigSendType" SG_ 1358 SBOX_ICCId_Res10 1;
BA_ "GenSigSendType" SG_ 1358 SBOX_ICCId_Res11 1;
BA_ "GenSigSendType" SG_ 1358 SBOX_ICCId_Res12 1;
BA_ "GenSigSendType" SG_ 1358 SBOX_ICCId_Res13 1;
BA_ "GenSigSendType" SG_ 1358 SBOX_ICCId_Res14 1;
BA_ "GenSigSendType" SG_ 1358 SBOX_ICCId_Res15 1;
BA_ "GenSigSendType" SG_ 1358 SBOX_ICCId_Res16 1;
BA_ "GenSigSendType" SG_ 1358 SBOX_ICCId_Res17 1;
BA_ "GenSigSendType" SG_ 1358 SBOX_ICCId_Res18 1;
BA_ "GenSigSendType" SG_ 1358 SBOX_ICCId_Res19 1;
BA_ "GenSigSendType" SG_ 1358 SBOX_Vin0 1;
BA_ "GenSigSendType" SG_ 1358 SBOX_Vin1 1;
BA_ "GenSigSendType" SG_ 1358 SBOX_Vin2 1;
BA_ "GenSigSendType" SG_ 1358 SBOX_Vin3 1;
BA_ "GenSigSendType" SG_ 1358 SBOX_Vin4 1;
BA_ "GenSigSendType" SG_ 1358 SBOX_Vin5 1;
BA_ "GenSigSendType" SG_ 1358 SBOX_Vin6 1;
BA_ "GenSigSendType" SG_ 1358 SBOX_Vin7 1;
BA_ "GenSigSendType" SG_ 1358 SBOX_Vin8 1;
BA_ "GenSigSendType" SG_ 1358 SBOX_Vin9 1;
BA_ "GenSigSendType" SG_ 1358 SBOX_Vin10 1;
BA_ "GenSigSendType" SG_ 1358 SBOX_Vin11 1;
BA_ "GenSigSendType" SG_ 1358 SBOX_Vin12 1;
BA_ "GenSigSendType" SG_ 1358 SBOX_Vin13 1;
BA_ "GenSigSendType" SG_ 1358 SBOX_Vin14 1;
BA_ "GenSigSendType" SG_ 1358 SBOX_Vin15 1;
BA_ "GenSigSendType" SG_ 1358 SBOX_Vin16 1;
BA_ "GenSigSendType" SG_ 1360 ICC_LISD_DisplaySwitch 2;
BA_ "GenSigSendType" SG_ 1360 ICC_LISD_ParkingShowCMD 2;
BA_ "GenSigSendType" SG_ 1360 ICC_RISD_DisplaySwitch 2;
BA_ "GenSigSendType" SG_ 1360 ICC_RISD_ParkingShowCMD 2;
BA_ "GenSigSendType" SG_ 1360 ICC_LogoParkingReq 2;
BA_ "GenSigSendType" SG_ 1360 ICC_LogoChargingReq 2;
BA_ "GenSigSendType" SG_ 1360 ICC_DRLSw 2;
BA_ "GenSigSendType" SG_ 1360 ICC_LISD_ParkingShowMod 2;
BA_ "GenSigSendType" SG_ 1360 ICC_RISD_ParkingShowMod 2;
BA_ "GenSigSendType" SG_ 1360 ICC_LogoColorReq 2;
BA_ "GenSigSendType" SG_ 1360 ICC_MusicLampShowSW 2;
BA_ "GenSigSendType" SG_ 1360 ICC_PenetrationLampSetF 2;
BA_ "GenSigSendType" SG_ 1360 ICC_XDriveMode 0;
BA_ "GenSigSendType" SG_ 1360 ICC_DowWaringSw 2;
BA_ "GenSigSendType" SG_ 1360 ICC_CarSearhSetSwitchSts 2;
BA_ "GenSigSendType" SG_ 1360 ICC_TDL_NightBright_SW_550h 2;
BA_ "GenSigSendType" SG_ 1361 EPC_LeftPedalSystem_Sts 0;
BA_ "GenSigInvalidValue" SG_ 1361 EPC_LeftPedalSystem_Sts 15;
BA_ "GenSigSendType" SG_ 1361 EPC_RightPedalSystem_Sts 0;
BA_ "GenSigInvalidValue" SG_ 1361 EPC_RightPedalSystem_Sts 15;
BA_ "GenSigSendType" SG_ 1361 EPC_LeftPedalTimeTravel 0;
BA_ "GenSigSendType" SG_ 1361 EPC_RightPedalTimeTravel 0;
BA_ "GenSigSendType" SG_ 1361 EPC_RightPedalRealTime_Sts 0;
BA_ "GenSigSendType" SG_ 1361 EPC_LeftPedalBreakIce_Sts 0;
BA_ "GenSigSendType" SG_ 1361 EPC_LeftPedalRealTime_Sts 0;
BA_ "GenSigSendType" SG_ 1361 EPC_RightPedalCmdStatus 0;
BA_ "GenSigStartValue" SG_ 1361 EPC_RightPedalCmdStatus 3;
BA_ "GenSigSendType" SG_ 1361 EPC_LeftPedalCmdStatus 0;
BA_ "GenSigStartValue" SG_ 1361 EPC_LeftPedalCmdStatus 3;
BA_ "GenSigSendType" SG_ 1361 EPC_Enable_CmdStatus 0;
BA_ "GenSigInvalidValue" SG_ 1361 EPC_Enable_CmdStatus 3;
BA_ "GenSigSendType" SG_ 1361 EPC_RightPedalBreakIce_Sts 0;
BA_ "GenSigSendType" SG_ 1361 EPC_RightPedal3D_Sts 0;
BA_ "GenSigSendType" SG_ 1361 EPC_LeftPedal3D_Sts 0;
BA_ "GenSigSendType" SG_ 1362 ICC_LISD_FrameCounter 2;
BA_ "GenSigSendType" SG_ 1362 ICC_LISD_RollingCounter 2;
BA_ "GenSigSendType" SG_ 1362 ICC_LISD_Pixel1_OnOff 2;
BA_ "GenSigSendType" SG_ 1362 ICC_LISD_Pixel2_OnOff 2;
BA_ "GenSigSendType" SG_ 1362 ICC_LISD_Pixel3_OnOff 2;
BA_ "GenSigSendType" SG_ 1362 ICC_LISD_Pixel4_OnOff 2;
BA_ "GenSigSendType" SG_ 1362 ICC_LISD_Pixel5_OnOff 2;
BA_ "GenSigSendType" SG_ 1362 ICC_LISD_Pixel6_OnOff 2;
BA_ "GenSigSendType" SG_ 1362 ICC_LISD_Pixel7_OnOff 2;
BA_ "GenSigSendType" SG_ 1362 ICC_LISD_Pixel8_OnOff 2;
BA_ "GenSigSendType" SG_ 1362 ICC_LISD_Pixel9_OnOff 2;
BA_ "GenSigSendType" SG_ 1362 ICC_LISD_Pixel10_OnOff 2;
BA_ "GenSigSendType" SG_ 1362 ICC_LISD_Pixel11_OnOff 2;
BA_ "GenSigSendType" SG_ 1362 ICC_LISD_Pixel12_OnOff 2;
BA_ "GenSigSendType" SG_ 1362 ICC_LISD_Pixel13_OnOff 2;
BA_ "GenSigSendType" SG_ 1362 ICC_LISD_Pixel14_OnOff 2;
BA_ "GenSigSendType" SG_ 1362 ICC_LISD_Pixel15_OnOff 2;
BA_ "GenSigSendType" SG_ 1362 ICC_LISD_Pixel16_OnOff 2;
BA_ "GenSigSendType" SG_ 1362 ICC_LISD_Pixel17_OnOff 2;
BA_ "GenSigSendType" SG_ 1362 ICC_LISD_Pixel18_OnOff 2;
BA_ "GenSigSendType" SG_ 1362 ICC_LISD_Pixel19_OnOff 2;
BA_ "GenSigSendType" SG_ 1362 ICC_LISD_Pixel20_OnOff 2;
BA_ "GenSigSendType" SG_ 1362 ICC_LISD_Pixel21_OnOff 2;
BA_ "GenSigSendType" SG_ 1362 ICC_LISD_Pixel22_OnOff 2;
BA_ "GenSigSendType" SG_ 1362 ICC_LISD_Pixel23_OnOff 2;
BA_ "GenSigSendType" SG_ 1362 ICC_LISD_Pixel24_OnOff 2;
BA_ "GenSigSendType" SG_ 1362 ICC_LISD_Pixel25_OnOff 2;
BA_ "GenSigSendType" SG_ 1362 ICC_LISD_Pixel26_OnOff 2;
BA_ "GenSigSendType" SG_ 1362 ICC_LISD_Pixel27_OnOff 2;
BA_ "GenSigSendType" SG_ 1362 ICC_LISD_Pixel28_OnOff 2;
BA_ "GenSigSendType" SG_ 1362 ICC_LISD_Pixel29_OnOff 2;
BA_ "GenSigSendType" SG_ 1362 ICC_LISD_Pixel30_OnOff 2;
BA_ "GenSigSendType" SG_ 1362 ICC_LISD_Pixel31_OnOff 2;
BA_ "GenSigSendType" SG_ 1362 ICC_LISD_Pixel32_OnOff 2;
BA_ "GenSigSendType" SG_ 1362 ICC_LISD_Pixel33_OnOff 2;
BA_ "GenSigSendType" SG_ 1362 ICC_LISD_Pixel34_OnOff 2;
BA_ "GenSigSendType" SG_ 1362 ICC_LISD_Pixel35_OnOff 2;
BA_ "GenSigSendType" SG_ 1362 ICC_LISD_Pixel36_OnOff 2;
BA_ "GenSigSendType" SG_ 1362 ICC_LISD_Pixel37_OnOff 2;
BA_ "GenSigSendType" SG_ 1362 ICC_LISD_Pixel38_OnOff 2;
BA_ "GenSigSendType" SG_ 1362 ICC_LISD_Pixel39_OnOff 2;
BA_ "GenSigSendType" SG_ 1362 ICC_LISD_Pixel40_OnOff 2;
BA_ "GenSigSendType" SG_ 1362 ICC_LISD_Pixel41_OnOff 2;
BA_ "GenSigSendType" SG_ 1362 ICC_LISD_Pixel42_OnOff 2;
BA_ "GenSigSendType" SG_ 1362 ICC_LISD_Pixel43_OnOff 2;
BA_ "GenSigSendType" SG_ 1362 ICC_LISD_Pixel44_OnOff 2;
BA_ "GenSigSendType" SG_ 1362 ICC_LISD_Pixel45_OnOff 2;
BA_ "GenSigSendType" SG_ 1362 ICC_LISD_Pixel46_OnOff 2;
BA_ "GenSigSendType" SG_ 1362 ICC_LISD_Pixel47_OnOff 2;
BA_ "GenSigSendType" SG_ 1362 ICC_LISD_Pixel48_OnOff 2;
BA_ "GenSigSendType" SG_ 1362 ICC_LISD_Pixel49_OnOff 2;
BA_ "GenSigSendType" SG_ 1362 ICC_LISD_Pixel50_OnOff 2;
BA_ "GenSigSendType" SG_ 1362 ICC_LISD_Pixel51_OnOff 2;
BA_ "GenSigSendType" SG_ 1362 ICC_LISD_Pixel52_OnOff 2;
BA_ "GenSigSendType" SG_ 1362 ICC_LISD_Pixel53_OnOff 2;
BA_ "GenSigSendType" SG_ 1362 ICC_LISD_Pixel54_OnOff 2;
BA_ "GenSigSendType" SG_ 1362 ICC_LISD_Pixel55_OnOff 2;
BA_ "GenSigSendType" SG_ 1362 ICC_LISD_Pixel56_OnOff 2;
BA_ "GenSigSendType" SG_ 1362 ICC_LISD_Pixel57_OnOff 2;
BA_ "GenSigSendType" SG_ 1362 ICC_LISD_Pixel58_OnOff 2;
BA_ "GenSigSendType" SG_ 1362 ICC_LISD_Pixel59_OnOff 2;
BA_ "GenSigSendType" SG_ 1362 ICC_LISD_Pixel60_OnOff 2;
BA_ "GenSigSendType" SG_ 1362 ICC_LISD_Pixel61_OnOff 2;
BA_ "GenSigSendType" SG_ 1362 ICC_LISD_Pixel62_OnOff 2;
BA_ "GenSigSendType" SG_ 1362 ICC_LISD_Pixel63_OnOff 2;
BA_ "GenSigSendType" SG_ 1362 ICC_LISD_Pixel64_OnOff 2;
BA_ "GenSigSendType" SG_ 1362 ICC_LISD_Pixel65_OnOff 2;
BA_ "GenSigSendType" SG_ 1362 ICC_LISD_Pixel66_OnOff 2;
BA_ "GenSigSendType" SG_ 1362 ICC_LISD_Pixel67_OnOff 2;
BA_ "GenSigSendType" SG_ 1362 ICC_LISD_Pixel68_OnOff 2;
BA_ "GenSigSendType" SG_ 1362 ICC_LISD_Pixel69_OnOff 2;
BA_ "GenSigSendType" SG_ 1362 ICC_LISD_Pixel70_OnOff 2;
BA_ "GenSigSendType" SG_ 1362 ICC_LISD_Pixel71_OnOff 2;
BA_ "GenSigSendType" SG_ 1362 ICC_LISD_Pixel72_OnOff 2;
BA_ "GenSigSendType" SG_ 1362 ICC_LISD_Pixel73_OnOff 2;
BA_ "GenSigSendType" SG_ 1362 ICC_LISD_Pixel74_OnOff 2;
BA_ "GenSigSendType" SG_ 1362 ICC_LISD_Pixel75_OnOff 2;
BA_ "GenSigSendType" SG_ 1362 ICC_LISD_Pixel76_OnOff 2;
BA_ "GenSigSendType" SG_ 1362 ICC_LISD_Pixel77_OnOff 2;
BA_ "GenSigSendType" SG_ 1362 ICC_LISD_Pixel78_OnOff 2;
BA_ "GenSigSendType" SG_ 1362 ICC_LISD_Pixel79_OnOff 2;
BA_ "GenSigSendType" SG_ 1362 ICC_LISD_Pixel80_OnOff 2;
BA_ "GenSigSendType" SG_ 1362 ICC_LISD_Pixel81_OnOff 2;
BA_ "GenSigSendType" SG_ 1362 ICC_LISD_Pixel82_OnOff 2;
BA_ "GenSigSendType" SG_ 1362 ICC_LISD_Pixel83_OnOff 2;
BA_ "GenSigSendType" SG_ 1362 ICC_LISD_Pixel84_OnOff 2;
BA_ "GenSigSendType" SG_ 1362 ICC_LISD_Pixel85_OnOff 2;
BA_ "GenSigSendType" SG_ 1362 ICC_LISD_Pixel86_OnOff 2;
BA_ "GenSigSendType" SG_ 1362 ICC_LISD_Pixel87_OnOff 2;
BA_ "GenSigSendType" SG_ 1362 ICC_LISD_Pixel88_OnOff 2;
BA_ "GenSigSendType" SG_ 1362 ICC_LISD_Pixel89_OnOff 2;
BA_ "GenSigSendType" SG_ 1362 ICC_LISD_Pixel90_OnOff 2;
BA_ "GenSigSendType" SG_ 1362 ICC_LISD_Pixel91_OnOff 2;
BA_ "GenSigSendType" SG_ 1362 ICC_LISD_Pixel92_OnOff 2;
BA_ "GenSigSendType" SG_ 1362 ICC_LISD_Pixel93_OnOff 2;
BA_ "GenSigSendType" SG_ 1362 ICC_LISD_Pixel94_OnOff 2;
BA_ "GenSigSendType" SG_ 1362 ICC_LISD_Pixel95_OnOff 2;
BA_ "GenSigSendType" SG_ 1362 ICC_LISD_Pixel96_OnOff 2;
BA_ "GenSigSendType" SG_ 1362 ICC_LISD_Pixel97_OnOff 2;
BA_ "GenSigSendType" SG_ 1362 ICC_LISD_Pixel98_OnOff 2;
BA_ "GenSigSendType" SG_ 1362 ICC_LISD_Pixel99_OnOff 2;
BA_ "GenSigSendType" SG_ 1362 ICC_LISD_Pixel100_OnOff 2;
BA_ "GenSigSendType" SG_ 1362 ICC_LISD_Pixel101_OnOff 2;
BA_ "GenSigSendType" SG_ 1362 ICC_LISD_Pixel102_OnOff 2;
BA_ "GenSigSendType" SG_ 1362 ICC_LISD_Pixel103_OnOff 2;
BA_ "GenSigSendType" SG_ 1362 ICC_LISD_Pixel104_OnOff 2;
BA_ "GenSigSendType" SG_ 1362 ICC_LISD_Pixel105_OnOff 2;
BA_ "GenSigSendType" SG_ 1362 ICC_LISD_Pixel106_OnOff 2;
BA_ "GenSigSendType" SG_ 1362 ICC_LISD_Pixel107_OnOff 2;
BA_ "GenSigSendType" SG_ 1362 ICC_LISD_Pixel108_OnOff 2;
BA_ "GenSigSendType" SG_ 1362 ICC_LISD_Pixel109_OnOff 2;
BA_ "GenSigSendType" SG_ 1362 ICC_LISD_Pixel110_OnOff 2;
BA_ "GenSigSendType" SG_ 1362 ICC_LISD_Pixel111_OnOff 2;
BA_ "GenSigSendType" SG_ 1362 ICC_LISD_Pixel112_OnOff 2;
BA_ "GenSigSendType" SG_ 1362 ICC_LISD_Pixel113_OnOff 2;
BA_ "GenSigSendType" SG_ 1362 ICC_LISD_Pixel114_OnOff 2;
BA_ "GenSigSendType" SG_ 1362 ICC_LISD_Pixel115_OnOff 2;
BA_ "GenSigSendType" SG_ 1362 ICC_LISD_Pixel116_OnOff 2;
BA_ "GenSigSendType" SG_ 1362 ICC_LISD_Pixel117_OnOff 2;
BA_ "GenSigSendType" SG_ 1362 ICC_LISD_Pixel118_OnOff 2;
BA_ "GenSigSendType" SG_ 1362 ICC_LISD_Pixel119_OnOff 2;
BA_ "GenSigSendType" SG_ 1362 ICC_LISD_Pixel120_OnOff 2;
BA_ "GenSigSendType" SG_ 1362 ICC_LISD_Pixel121_OnOff 2;
BA_ "GenSigSendType" SG_ 1362 ICC_LISD_Pixel122_OnOff 2;
BA_ "GenSigSendType" SG_ 1362 ICC_LISD_Pixel123_OnOff 2;
BA_ "GenSigSendType" SG_ 1362 ICC_LISD_Pixel124_OnOff 2;
BA_ "GenSigSendType" SG_ 1362 ICC_LISD_Pixel125_OnOff 2;
BA_ "GenSigSendType" SG_ 1362 ICC_LISD_Pixel126_OnOff 2;
BA_ "GenSigSendType" SG_ 1362 ICC_LISD_Pixel127_OnOff 2;
BA_ "GenSigSendType" SG_ 1362 ICC_LISD_Pixel128_OnOff 2;
BA_ "GenSigSendType" SG_ 1362 ICC_LISD_Pixel129_OnOff 2;
BA_ "GenSigSendType" SG_ 1362 ICC_LISD_Pixel130_OnOff 2;
BA_ "GenSigSendType" SG_ 1362 ICC_LISD_Pixel131_OnOff 2;
BA_ "GenSigSendType" SG_ 1362 ICC_LISD_Pixel132_OnOff 2;
BA_ "GenSigSendType" SG_ 1362 ICC_LISD_Pixel133_OnOff 2;
BA_ "GenSigSendType" SG_ 1362 ICC_LISD_Pixel134_OnOff 2;
BA_ "GenSigSendType" SG_ 1362 ICC_LISD_Pixel135_OnOff 2;
BA_ "GenSigSendType" SG_ 1362 ICC_LISD_Pixel136_OnOff 2;
BA_ "GenSigSendType" SG_ 1362 ICC_LISD_Pixel137_OnOff 2;
BA_ "GenSigSendType" SG_ 1362 ICC_LISD_Pixel138_OnOff 2;
BA_ "GenSigSendType" SG_ 1362 ICC_LISD_Pixel139_OnOff 2;
BA_ "GenSigSendType" SG_ 1362 ICC_LISD_Pixel140_OnOff 2;
BA_ "GenSigSendType" SG_ 1362 ICC_LISD_Pixel141_OnOff 2;
BA_ "GenSigSendType" SG_ 1362 ICC_LISD_Pixel142_OnOff 2;
BA_ "GenSigSendType" SG_ 1362 ICC_LISD_Pixel143_OnOff 2;
BA_ "GenSigSendType" SG_ 1362 ICC_LISD_Pixel144_OnOff 2;
BA_ "GenSigSendType" SG_ 1362 ICC_LISD_Pixel145_OnOff 2;
BA_ "GenSigSendType" SG_ 1362 ICC_LISD_Pixel146_OnOff 2;
BA_ "GenSigSendType" SG_ 1362 ICC_LISD_Pixel147_OnOff 2;
BA_ "GenSigSendType" SG_ 1362 ICC_LISD_Pixel148_OnOff 2;
BA_ "GenSigSendType" SG_ 1362 ICC_LISD_Pixel149_OnOff 2;
BA_ "GenSigSendType" SG_ 1362 ICC_LISD_Pixel150_OnOff 2;
BA_ "GenSigSendType" SG_ 1362 ICC_LISD_Pixel151_OnOff 2;
BA_ "GenSigSendType" SG_ 1362 ICC_LISD_Pixel152_OnOff 2;
BA_ "GenSigSendType" SG_ 1362 ICC_LISD_Pixel153_OnOff 2;
BA_ "GenSigSendType" SG_ 1362 ICC_LISD_Pixel154_OnOff 2;
BA_ "GenSigSendType" SG_ 1362 ICC_LISD_Pixel155_OnOff 2;
BA_ "GenSigSendType" SG_ 1362 ICC_LISD_Pixel156_OnOff 2;
BA_ "GenSigSendType" SG_ 1362 ICC_LISD_Pixel157_OnOff 2;
BA_ "GenSigSendType" SG_ 1362 ICC_LISD_Pixel158_OnOff 2;
BA_ "GenSigSendType" SG_ 1362 ICC_LISD_Pixel159_OnOff 2;
BA_ "GenSigSendType" SG_ 1362 ICC_LISD_Pixel160_OnOff 2;
BA_ "GenSigSendType" SG_ 1362 ICC_LISD_Pixel161_OnOff 2;
BA_ "GenSigSendType" SG_ 1362 ICC_LISD_Pixel162_OnOff 2;
BA_ "GenSigSendType" SG_ 1362 ICC_LISD_Pixel163_OnOff 2;
BA_ "GenSigSendType" SG_ 1362 ICC_LISD_Pixel164_OnOff 2;
BA_ "GenSigSendType" SG_ 1362 ICC_LISD_Pixel165_OnOff 2;
BA_ "GenSigSendType" SG_ 1362 ICC_LISD_Pixel166_OnOff 2;
BA_ "GenSigSendType" SG_ 1362 ICC_LISD_Pixel167_OnOff 2;
BA_ "GenSigSendType" SG_ 1362 ICC_LISD_Pixel168_OnOff 2;
BA_ "GenSigSendType" SG_ 1362 ICC_LISD_Pixel169_OnOff 2;
BA_ "GenSigSendType" SG_ 1362 ICC_LISD_Pixel170_OnOff 2;
BA_ "GenSigSendType" SG_ 1362 ICC_LISD_Pixel171_OnOff 2;
BA_ "GenSigSendType" SG_ 1362 ICC_LISD_Pixel172_OnOff 2;
BA_ "GenSigSendType" SG_ 1362 ICC_LISD_Pixel173_OnOff 2;
BA_ "GenSigSendType" SG_ 1362 ICC_LISD_Pixel174_OnOff 2;
BA_ "GenSigSendType" SG_ 1362 ICC_LISD_Pixel175_OnOff 2;
BA_ "GenSigSendType" SG_ 1362 ICC_LISD_Pixel176_OnOff 2;
BA_ "GenSigSendType" SG_ 1362 ICC_LISD_Pixel177_OnOff 2;
BA_ "GenSigSendType" SG_ 1362 ICC_LISD_Pixel178_OnOff 2;
BA_ "GenSigSendType" SG_ 1362 ICC_LISD_Pixel179_OnOff 2;
BA_ "GenSigSendType" SG_ 1362 ICC_LISD_Pixel180_OnOff 2;
BA_ "GenSigSendType" SG_ 1362 ICC_LISD_Pixel181_OnOff 2;
BA_ "GenSigSendType" SG_ 1362 ICC_LISD_Pixel182_OnOff 2;
BA_ "GenSigSendType" SG_ 1362 ICC_LISD_Pixel183_OnOff 2;
BA_ "GenSigSendType" SG_ 1362 ICC_LISD_Pixel184_OnOff 2;
BA_ "GenSigSendType" SG_ 1362 ICC_LISD_Pixel185_OnOff 2;
BA_ "GenSigSendType" SG_ 1362 ICC_LISD_Pixel186_OnOff 2;
BA_ "GenSigSendType" SG_ 1362 ICC_LISD_Pixel187_OnOff 2;
BA_ "GenSigSendType" SG_ 1362 ICC_LISD_Pixel188_OnOff 2;
BA_ "GenSigSendType" SG_ 1362 ICC_LISD_Pixel189_OnOff 2;
BA_ "GenSigSendType" SG_ 1362 ICC_LISD_Pixel190_OnOff 2;
BA_ "GenSigSendType" SG_ 1362 ICC_LISD_Pixel191_OnOff 2;
BA_ "GenSigSendType" SG_ 1362 ICC_LISD_Pixel192_OnOff 2;
BA_ "GenSigSendType" SG_ 1362 ICC_LISD_Pixel193_OnOff 2;
BA_ "GenSigSendType" SG_ 1362 ICC_LISD_Pixel194_OnOff 2;
BA_ "GenSigSendType" SG_ 1362 ICC_LISD_Pixel195_OnOff 2;
BA_ "GenSigSendType" SG_ 1362 ICC_LISD_Pixel196_OnOff 2;
BA_ "GenSigSendType" SG_ 1362 ICC_LISD_Pixel197_OnOff 2;
BA_ "GenSigSendType" SG_ 1362 ICC_LISD_Pixel198_OnOff 2;
BA_ "GenSigSendType" SG_ 1362 ICC_LISD_Pixel199_OnOff 2;
BA_ "GenSigSendType" SG_ 1362 ICC_LISD_Pixel200_OnOff 2;
BA_ "GenSigSendType" SG_ 1362 ICC_LISD_Pixel201_OnOff 2;
BA_ "GenSigSendType" SG_ 1362 ICC_LISD_Pixel202_OnOff 2;
BA_ "GenSigSendType" SG_ 1362 ICC_LISD_Pixel203_OnOff 2;
BA_ "GenSigSendType" SG_ 1362 ICC_LISD_Pixel204_OnOff 2;
BA_ "GenSigSendType" SG_ 1362 ICC_LISD_Pixel205_OnOff 2;
BA_ "GenSigSendType" SG_ 1362 ICC_LISD_Pixel206_OnOff 2;
BA_ "GenSigSendType" SG_ 1362 ICC_LISD_Pixel207_OnOff 2;
BA_ "GenSigSendType" SG_ 1362 ICC_LISD_Pixel208_OnOff 2;
BA_ "GenSigSendType" SG_ 1362 ICC_LISD_Pixel209_OnOff 2;
BA_ "GenSigSendType" SG_ 1362 ICC_LISD_Pixel210_OnOff 2;
BA_ "GenSigSendType" SG_ 1362 ICC_LISD_Pixel211_OnOff 2;
BA_ "GenSigSendType" SG_ 1362 ICC_LISD_Pixel212_OnOff 2;
BA_ "GenSigSendType" SG_ 1362 ICC_LISD_Pixel213_OnOff 2;
BA_ "GenSigSendType" SG_ 1362 ICC_LISD_Pixel214_OnOff 2;
BA_ "GenSigSendType" SG_ 1362 ICC_LISD_Pixel215_OnOff 2;
BA_ "GenSigSendType" SG_ 1362 ICC_LISD_Pixel216_OnOff 2;
BA_ "GenSigSendType" SG_ 1362 ICC_LISD_Pixel217_OnOff 2;
BA_ "GenSigSendType" SG_ 1362 ICC_LISD_Pixel218_OnOff 2;
BA_ "GenSigSendType" SG_ 1362 ICC_LISD_Pixel219_OnOff 2;
BA_ "GenSigSendType" SG_ 1362 ICC_LISD_Pixel220_OnOff 2;
BA_ "GenSigSendType" SG_ 1362 ICC_LISD_Pixel221_OnOff 2;
BA_ "GenSigSendType" SG_ 1362 ICC_LISD_Pixel222_OnOff 2;
BA_ "GenSigSendType" SG_ 1362 ICC_LISD_Pixel223_OnOff 2;
BA_ "GenSigSendType" SG_ 1362 ICC_LISD_Pixel224_OnOff 2;
BA_ "GenSigSendType" SG_ 1362 ICC_LISD_Pixel225_OnOff 2;
BA_ "GenSigSendType" SG_ 1362 ICC_LISD_Pixel226_OnOff 2;
BA_ "GenSigSendType" SG_ 1362 ICC_LISD_Pixel227_OnOff 2;
BA_ "GenSigSendType" SG_ 1362 ICC_LISD_Pixel228_OnOff 2;
BA_ "GenSigSendType" SG_ 1362 ICC_LISD_Pixel229_OnOff 2;
BA_ "GenSigSendType" SG_ 1362 ICC_LISD_Pixel230_OnOff 2;
BA_ "GenSigSendType" SG_ 1362 ICC_LISD_Pixel231_OnOff 2;
BA_ "GenSigSendType" SG_ 1362 ICC_LISD_Pixel232_OnOff 2;
BA_ "GenSigSendType" SG_ 1362 ICC_LISD_Pixel233_OnOff 2;
BA_ "GenSigSendType" SG_ 1362 ICC_LISD_Pixel234_OnOff 2;
BA_ "GenSigSendType" SG_ 1362 ICC_LISD_Pixel235_OnOff 2;
BA_ "GenSigSendType" SG_ 1362 ICC_LISD_Pixel236_OnOff 2;
BA_ "GenSigSendType" SG_ 1362 ICC_LISD_Pixel237_OnOff 2;
BA_ "GenSigSendType" SG_ 1362 ICC_LISD_Pixel238_OnOff 2;
BA_ "GenSigSendType" SG_ 1362 ICC_LISD_Pixel239_OnOff 2;
BA_ "GenSigSendType" SG_ 1362 ICC_LISD_Pixel240_OnOff 2;
BA_ "GenSigSendType" SG_ 1362 ICC_LISD_Pixel241_OnOff 2;
BA_ "GenSigSendType" SG_ 1362 ICC_LISD_Pixel242_OnOff 2;
BA_ "GenSigSendType" SG_ 1362 ICC_LISD_Pixel243_OnOff 2;
BA_ "GenSigSendType" SG_ 1362 ICC_LISD_Pixel244_OnOff 2;
BA_ "GenSigSendType" SG_ 1362 ICC_LISD_Pixel245_OnOff 2;
BA_ "GenSigSendType" SG_ 1362 ICC_LISD_Pixel246_OnOff 2;
BA_ "GenSigSendType" SG_ 1362 ICC_LISD_Pixel247_OnOff 2;
BA_ "GenSigSendType" SG_ 1362 ICC_LISD_Pixel248_OnOff 2;
BA_ "GenSigSendType" SG_ 1362 ICC_LISD_Pixel249_OnOff 2;
BA_ "GenSigSendType" SG_ 1362 ICC_LISD_Pixel250_OnOff 2;
BA_ "GenSigSendType" SG_ 1362 ICC_LISD_Pixel251_OnOff 2;
BA_ "GenSigSendType" SG_ 1362 ICC_LISD_Pixel252_OnOff 2;
BA_ "GenSigSendType" SG_ 1362 ICC_LISD_Pixel253_OnOff 2;
BA_ "GenSigSendType" SG_ 1362 ICC_LISD_Pixel254_OnOff 2;
BA_ "GenSigSendType" SG_ 1362 ICC_LISD_Pixel255_OnOff 2;
BA_ "GenSigSendType" SG_ 1362 ICC_LISD_Pixel256_OnOff 2;
BA_ "GenSigSendType" SG_ 1362 ICC_LISD_Pixel257_OnOff 2;
BA_ "GenSigSendType" SG_ 1362 ICC_LISD_Pixel258_OnOff 2;
BA_ "GenSigSendType" SG_ 1362 ICC_LISD_Pixel259_OnOff 2;
BA_ "GenSigSendType" SG_ 1362 ICC_LISD_Pixel260_OnOff 2;
BA_ "GenSigSendType" SG_ 1362 ICC_LISD_Pixel261_OnOff 2;
BA_ "GenSigSendType" SG_ 1362 ICC_LISD_Pixel262_OnOff 2;
BA_ "GenSigSendType" SG_ 1362 ICC_LISD_Pixel263_OnOff 2;
BA_ "GenSigSendType" SG_ 1362 ICC_LISD_Pixel264_OnOff 2;
BA_ "GenSigSendType" SG_ 1362 ICC_LISD_Pixel265_OnOff 2;
BA_ "GenSigSendType" SG_ 1362 ICC_LISD_Pixel266_OnOff 2;
BA_ "GenSigSendType" SG_ 1362 ICC_LISD_Pixel267_OnOff 2;
BA_ "GenSigSendType" SG_ 1362 ICC_LISD_Pixel268_OnOff 2;
BA_ "GenSigSendType" SG_ 1362 ICC_LISD_Pixel269_OnOff 2;
BA_ "GenSigSendType" SG_ 1362 ICC_LISD_Pixel270_OnOff 2;
BA_ "GenSigSendType" SG_ 1362 ICC_LISD_Pixel271_OnOff 2;
BA_ "GenSigSendType" SG_ 1362 ICC_LISD_Pixel272_OnOff 2;
BA_ "GenSigSendType" SG_ 1362 ICC_LISD_Pixel273_OnOff 2;
BA_ "GenSigSendType" SG_ 1362 ICC_LISD_Pixel274_OnOff 2;
BA_ "GenSigSendType" SG_ 1362 ICC_LISD_Pixel275_OnOff 2;
BA_ "GenSigSendType" SG_ 1362 ICC_LISD_Pixel276_OnOff 2;
BA_ "GenSigSendType" SG_ 1362 ICC_LISD_Pixel277_OnOff 2;
BA_ "GenSigSendType" SG_ 1362 ICC_LISD_Pixel278_OnOff 2;
BA_ "GenSigSendType" SG_ 1362 ICC_LISD_Pixel279_OnOff 2;
BA_ "GenSigSendType" SG_ 1362 ICC_LISD_Pixel280_OnOff 2;
BA_ "GenSigSendType" SG_ 1362 ICC_LISD_Pixel281_OnOff 2;
BA_ "GenSigSendType" SG_ 1362 ICC_LISD_Pixel282_OnOff 2;
BA_ "GenSigSendType" SG_ 1362 ICC_LISD_Pixel283_OnOff 2;
BA_ "GenSigSendType" SG_ 1362 ICC_LISD_Pixel284_OnOff 2;
BA_ "GenSigSendType" SG_ 1362 ICC_LISD_Pixel285_OnOff 2;
BA_ "GenSigSendType" SG_ 1362 ICC_LISD_Pixel286_OnOff 2;
BA_ "GenSigSendType" SG_ 1362 ICC_LISD_Pixel287_OnOff 2;
BA_ "GenSigSendType" SG_ 1362 ICC_LISD_Pixel288_OnOff 2;
BA_ "GenSigSendType" SG_ 1362 ICC_LISD_Pixel289_OnOff 2;
BA_ "GenSigSendType" SG_ 1362 ICC_LISD_Pixel290_OnOff 2;
BA_ "GenSigSendType" SG_ 1362 ICC_LISD_Pixel291_OnOff 2;
BA_ "GenSigSendType" SG_ 1362 ICC_LISD_Pixel292_OnOff 2;
BA_ "GenSigSendType" SG_ 1362 ICC_LISD_Pixel293_OnOff 2;
BA_ "GenSigSendType" SG_ 1362 ICC_LISD_Pixel294_OnOff 2;
BA_ "GenSigSendType" SG_ 1362 ICC_LISD_Pixel295_OnOff 2;
BA_ "GenSigSendType" SG_ 1362 ICC_LISD_Pixel296_OnOff 2;
BA_ "GenSigSendType" SG_ 1362 ICC_LISD_Pixel297_OnOff 2;
BA_ "GenSigSendType" SG_ 1362 ICC_LISD_Pixel298_OnOff 2;
BA_ "GenSigSendType" SG_ 1362 ICC_LISD_Pixel299_OnOff 2;
BA_ "GenSigSendType" SG_ 1362 ICC_LISD_Pixel300_OnOff 2;
BA_ "GenSigSendType" SG_ 1362 ICC_LISD_Pixel301_OnOff 2;
BA_ "GenSigSendType" SG_ 1362 ICC_LISD_Pixel302_OnOff 2;
BA_ "GenSigSendType" SG_ 1362 ICC_LISD_Pixel303_OnOff 2;
BA_ "GenSigSendType" SG_ 1362 ICC_LISD_Pixel304_OnOff 2;
BA_ "GenSigSendType" SG_ 1362 ICC_LISD_Pixel305_OnOff 2;
BA_ "GenSigSendType" SG_ 1362 ICC_LISD_Pixel306_OnOff 2;
BA_ "GenSigSendType" SG_ 1362 ICC_LISD_Pixel307_OnOff 2;
BA_ "GenSigSendType" SG_ 1362 ICC_LISD_Pixel308_OnOff 2;
BA_ "GenSigSendType" SG_ 1362 ICC_LISD_Pixel309_OnOff 2;
BA_ "GenSigSendType" SG_ 1362 ICC_LISD_Pixel310_OnOff 2;
BA_ "GenSigSendType" SG_ 1362 ICC_LISD_Pixel311_OnOff 2;
BA_ "GenSigSendType" SG_ 1362 ICC_LISD_Pixel312_OnOff 2;
BA_ "GenSigSendType" SG_ 1362 ICC_LISD_Pixel313_OnOff 2;
BA_ "GenSigSendType" SG_ 1362 ICC_LISD_Pixel314_OnOff 2;
BA_ "GenSigSendType" SG_ 1362 ICC_LISD_Pixel315_OnOff 2;
BA_ "GenSigSendType" SG_ 1362 ICC_LISD_Pixel316_OnOff 2;
BA_ "GenSigSendType" SG_ 1362 ICC_LISD_Pixel317_OnOff 2;
BA_ "GenSigSendType" SG_ 1362 ICC_LISD_Pixel318_OnOff 2;
BA_ "GenSigSendType" SG_ 1362 ICC_LISD_Pixel319_OnOff 2;
BA_ "GenSigSendType" SG_ 1362 ICC_LISD_Pixel320_OnOff 2;
BA_ "GenSigSendType" SG_ 1362 ICC_LISD_Pixel321_OnOff 2;
BA_ "GenSigSendType" SG_ 1362 ICC_LISD_Pixel322_OnOff 2;
BA_ "GenSigSendType" SG_ 1362 ICC_LISD_Pixel323_OnOff 2;
BA_ "GenSigSendType" SG_ 1362 ICC_LISD_Pixel324_OnOff 2;
BA_ "GenSigSendType" SG_ 1362 ICC_LISD_Pixel325_OnOff 2;
BA_ "GenSigSendType" SG_ 1362 ICC_LISD_Pixel326_OnOff 2;
BA_ "GenSigSendType" SG_ 1362 ICC_LISD_Pixel327_OnOff 2;
BA_ "GenSigSendType" SG_ 1362 ICC_LISD_Pixel328_OnOff 2;
BA_ "GenSigSendType" SG_ 1362 ICC_LISD_Pixel329_OnOff 2;
BA_ "GenSigSendType" SG_ 1362 ICC_LISD_Pixel330_OnOff 2;
BA_ "GenSigSendType" SG_ 1362 ICC_LISD_Pixel331_OnOff 2;
BA_ "GenSigSendType" SG_ 1362 ICC_LISD_Pixel332_OnOff 2;
BA_ "GenSigSendType" SG_ 1362 ICC_LISD_Pixel333_OnOff 2;
BA_ "GenSigSendType" SG_ 1362 ICC_LISD_Pixel334_OnOff 2;
BA_ "GenSigSendType" SG_ 1362 ICC_LISD_Pixel335_OnOff 2;
BA_ "GenSigSendType" SG_ 1362 ICC_LISD_Pixel336_OnOff 2;
BA_ "GenSigSendType" SG_ 1362 ICC_LISD_Pixel337_OnOff 2;
BA_ "GenSigSendType" SG_ 1362 ICC_LISD_Pixel338_OnOff 2;
BA_ "GenSigSendType" SG_ 1362 ICC_LISD_Pixel339_OnOff 2;
BA_ "GenSigSendType" SG_ 1362 ICC_LISD_Pixel340_OnOff 2;
BA_ "GenSigSendType" SG_ 1362 ICC_LISD_Pixel341_OnOff 2;
BA_ "GenSigSendType" SG_ 1362 ICC_LISD_Pixel342_OnOff 2;
BA_ "GenSigSendType" SG_ 1362 ICC_LISD_Pixel343_OnOff 2;
BA_ "GenSigSendType" SG_ 1362 ICC_LISD_Pixel344_OnOff 2;
BA_ "GenSigSendType" SG_ 1362 ICC_LISD_Pixel345_OnOff 2;
BA_ "GenSigSendType" SG_ 1362 ICC_LISD_Pixel346_OnOff 2;
BA_ "GenSigSendType" SG_ 1362 ICC_LISD_Pixel347_OnOff 2;
BA_ "GenSigSendType" SG_ 1362 ICC_LISD_Pixel348_OnOff 2;
BA_ "GenSigSendType" SG_ 1362 ICC_LISD_Pixel349_OnOff 2;
BA_ "GenSigSendType" SG_ 1362 ICC_LISD_Pixel350_OnOff 2;
BA_ "GenSigSendType" SG_ 1362 ICC_LISD_Pixel351_OnOff 2;
BA_ "GenSigSendType" SG_ 1362 ICC_LISD_Pixel352_OnOff 2;
BA_ "GenSigSendType" SG_ 1362 ICC_LISD_Pixel353_OnOff 2;
BA_ "GenSigSendType" SG_ 1362 ICC_LISD_Pixel354_OnOff 2;
BA_ "GenSigSendType" SG_ 1362 ICC_LISD_Pixel355_OnOff 2;
BA_ "GenSigSendType" SG_ 1362 ICC_LISD_Pixel356_OnOff 2;
BA_ "GenSigSendType" SG_ 1362 ICC_LISD_Pixel357_OnOff 2;
BA_ "GenSigSendType" SG_ 1362 ICC_LISD_Pixel358_OnOff 2;
BA_ "GenSigSendType" SG_ 1362 ICC_LISD_Pixel359_OnOff 2;
BA_ "GenSigSendType" SG_ 1362 ICC_LISD_Pixel360_OnOff 2;
BA_ "GenSigSendType" SG_ 1362 ICC_LISD_Pixel361_OnOff 2;
BA_ "GenSigSendType" SG_ 1362 ICC_LISD_Pixel362_OnOff 2;
BA_ "GenSigSendType" SG_ 1362 ICC_LISD_Pixel363_OnOff 2;
BA_ "GenSigSendType" SG_ 1362 ICC_LISD_Pixel364_OnOff 2;
BA_ "GenSigSendType" SG_ 1362 ICC_LISD_Pixel365_OnOff 2;
BA_ "GenSigSendType" SG_ 1362 ICC_LISD_Pixel366_OnOff 2;
BA_ "GenSigSendType" SG_ 1362 ICC_LISD_Pixel367_OnOff 2;
BA_ "GenSigSendType" SG_ 1362 ICC_LISD_Pixel368_OnOff 2;
BA_ "GenSigSendType" SG_ 1362 ICC_LISD_Pixel369_OnOff 2;
BA_ "GenSigSendType" SG_ 1362 ICC_LISD_Pixel370_OnOff 2;
BA_ "GenSigSendType" SG_ 1362 ICC_LISD_Pixel371_OnOff 2;
BA_ "GenSigSendType" SG_ 1362 ICC_LISD_Pixel372_OnOff 2;
BA_ "GenSigSendType" SG_ 1362 ICC_LISD_Pixel373_OnOff 2;
BA_ "GenSigSendType" SG_ 1362 ICC_LISD_Pixel374_OnOff 2;
BA_ "GenSigSendType" SG_ 1362 ICC_LISD_Pixel375_OnOff 2;
BA_ "GenSigSendType" SG_ 1362 ICC_LISD_Pixel376_OnOff 2;
BA_ "GenSigSendType" SG_ 1362 ICC_LISD_Pixel377_OnOff 2;
BA_ "GenSigSendType" SG_ 1362 ICC_LISD_Pixel378_OnOff 2;
BA_ "GenSigSendType" SG_ 1362 ICC_LISD_Pixel379_OnOff 2;
BA_ "GenSigSendType" SG_ 1362 ICC_LISD_Pixel380_OnOff 2;
BA_ "GenSigSendType" SG_ 1362 ICC_LISD_Pixel381_OnOff 2;
BA_ "GenSigSendType" SG_ 1362 ICC_LISD_Pixel382_OnOff 2;
BA_ "GenSigSendType" SG_ 1362 ICC_LISD_Pixel383_OnOff 2;
BA_ "GenSigSendType" SG_ 1362 ICC_LISD_Pixel384_OnOff 2;
BA_ "GenSigSendType" SG_ 1362 ICC_LISD_Pixel385_OnOff 2;
BA_ "GenSigSendType" SG_ 1362 ICC_LISD_Pixel386_OnOff 2;
BA_ "GenSigSendType" SG_ 1362 ICC_LISD_Pixel387_OnOff 2;
BA_ "GenSigSendType" SG_ 1362 ICC_LISD_Pixel388_OnOff 2;
BA_ "GenSigSendType" SG_ 1362 ICC_LISD_Pixel389_OnOff 2;
BA_ "GenSigSendType" SG_ 1362 ICC_LISD_Pixel390_OnOff 2;
BA_ "GenSigSendType" SG_ 1362 ICC_LISD_Pixel391_OnOff 2;
BA_ "GenSigSendType" SG_ 1362 ICC_LISD_Pixel392_OnOff 2;
BA_ "GenSigSendType" SG_ 1362 ICC_LISD_Pixel393_OnOff 2;
BA_ "GenSigSendType" SG_ 1362 ICC_LISD_Pixel394_OnOff 2;
BA_ "GenSigSendType" SG_ 1362 ICC_LISD_Pixel395_OnOff 2;
BA_ "GenSigSendType" SG_ 1362 ICC_LISD_Pixel396_OnOff 2;
BA_ "GenSigSendType" SG_ 1362 ICC_LISD_Pixel397_OnOff 2;
BA_ "GenSigSendType" SG_ 1362 ICC_LISD_Pixel398_OnOff 2;
BA_ "GenSigSendType" SG_ 1362 ICC_LISD_Pixel399_OnOff 2;
BA_ "GenSigSendType" SG_ 1362 ICC_LISD_Pixel400_OnOff 2;
BA_ "GenSigSendType" SG_ 1362 ICC_LISD_Pixel401_OnOff 2;
BA_ "GenSigSendType" SG_ 1362 ICC_LISD_Pixel402_OnOff 2;
BA_ "GenSigSendType" SG_ 1362 ICC_LISD_Pixel403_OnOff 2;
BA_ "GenSigSendType" SG_ 1362 ICC_LISD_Pixel404_OnOff 2;
BA_ "GenSigSendType" SG_ 1362 ICC_LISD_Pixel405_OnOff 2;
BA_ "GenSigSendType" SG_ 1362 ICC_LISD_Pixel406_OnOff 2;
BA_ "GenSigSendType" SG_ 1362 ICC_LISD_Pixel407_OnOff 2;
BA_ "GenSigSendType" SG_ 1362 ICC_LISD_Pixel408_OnOff 2;
BA_ "GenSigSendType" SG_ 1362 ICC_LISD_Pixel409_OnOff 2;
BA_ "GenSigSendType" SG_ 1362 ICC_LISD_Pixel410_OnOff 2;
BA_ "GenSigSendType" SG_ 1362 ICC_LISD_Pixel411_OnOff 2;
BA_ "GenSigSendType" SG_ 1362 ICC_LISD_Pixel412_OnOff 2;
BA_ "GenSigSendType" SG_ 1362 ICC_LISD_Pixel413_OnOff 2;
BA_ "GenSigSendType" SG_ 1362 ICC_LISD_Pixel414_OnOff 2;
BA_ "GenSigSendType" SG_ 1362 ICC_LISD_Pixel415_OnOff 2;
BA_ "GenSigSendType" SG_ 1362 ICC_LISD_Pixel416_OnOff 2;
BA_ "GenSigSendType" SG_ 1362 ICC_LISD_Pixel417_OnOff 2;
BA_ "GenSigSendType" SG_ 1362 ICC_LISD_Pixel418_OnOff 2;
BA_ "GenSigSendType" SG_ 1362 ICC_LISD_Pixel419_OnOff 2;
BA_ "GenSigSendType" SG_ 1362 ICC_LISD_Pixel420_OnOff 2;
BA_ "GenSigSendType" SG_ 1362 ICC_LISD_Pixel421_OnOff 2;
BA_ "GenSigSendType" SG_ 1362 ICC_LISD_Pixel422_OnOff 2;
BA_ "GenSigSendType" SG_ 1362 ICC_LISD_Pixel423_OnOff 2;
BA_ "GenSigSendType" SG_ 1362 ICC_LISD_Pixel424_OnOff 2;
BA_ "GenSigSendType" SG_ 1362 ICC_LISD_Pixel425_OnOff 2;
BA_ "GenSigSendType" SG_ 1362 ICC_LISD_Pixel426_OnOff 2;
BA_ "GenSigSendType" SG_ 1362 ICC_LISD_Pixel427_OnOff 2;
BA_ "GenSigSendType" SG_ 1362 ICC_LISD_Pixel428_OnOff 2;
BA_ "GenSigSendType" SG_ 1362 ICC_LISD_Pixel429_OnOff 2;
BA_ "GenSigSendType" SG_ 1362 ICC_LISD_Pixel430_OnOff 2;
BA_ "GenSigSendType" SG_ 1362 ICC_LISD_Pixel431_OnOff 2;
BA_ "GenSigSendType" SG_ 1362 ICC_LISD_Pixel432_OnOff 2;
BA_ "GenSigSendType" SG_ 1362 ICC_LISD_Pixel433_OnOff 2;
BA_ "GenSigSendType" SG_ 1362 ICC_LISD_Pixel434_OnOff 2;
BA_ "GenSigSendType" SG_ 1362 ICC_LISD_Pixel435_OnOff 2;
BA_ "GenSigSendType" SG_ 1362 ICC_LISD_Pixel436_OnOff 2;
BA_ "GenSigSendType" SG_ 1362 ICC_LISD_Pixel437_OnOff 2;
BA_ "GenSigSendType" SG_ 1362 ICC_LISD_Pixel438_OnOff 2;
BA_ "GenSigSendType" SG_ 1362 ICC_LISD_Pixel439_OnOff 2;
BA_ "GenSigSendType" SG_ 1362 ICC_LISD_Pixel440_OnOff 2;
BA_ "GenSigSendType" SG_ 1362 ICC_LISD_Pixel441_OnOff 2;
BA_ "GenSigSendType" SG_ 1362 ICC_LISD_Pixel442_OnOff 2;
BA_ "GenSigSendType" SG_ 1362 ICC_LISD_Pixel443_OnOff 2;
BA_ "GenSigSendType" SG_ 1362 ICC_LISD_Pixel444_OnOff 2;
BA_ "GenSigSendType" SG_ 1362 ICC_LISD_Pixel445_OnOff 2;
BA_ "GenSigSendType" SG_ 1362 ICC_LISD_Pixel446_OnOff 2;
BA_ "GenSigSendType" SG_ 1362 ICC_LISD_Pixel447_OnOff 2;
BA_ "GenSigSendType" SG_ 1362 ICC_LISD_Pixel448_OnOff 2;
BA_ "GenSigSendType" SG_ 1362 ICC_LISD_Pixel449_OnOff 2;
BA_ "GenSigSendType" SG_ 1362 ICC_LISD_Pixel450_OnOff 2;
BA_ "GenSigSendType" SG_ 1362 ICC_LISD_Pixel451_OnOff 2;
BA_ "GenSigSendType" SG_ 1362 ICC_LISD_Pixel452_OnOff 2;
BA_ "GenSigSendType" SG_ 1362 ICC_LISD_Pixel453_OnOff 2;
BA_ "GenSigSendType" SG_ 1362 ICC_LISD_Pixel454_OnOff 2;
BA_ "GenSigSendType" SG_ 1362 ICC_LISD_Pixel455_OnOff 2;
BA_ "GenSigSendType" SG_ 1362 ICC_LISD_Pixel456_OnOff 2;
BA_ "GenSigSendType" SG_ 1362 ICC_LISD_Pixel457_OnOff 2;
BA_ "GenSigSendType" SG_ 1362 ICC_LISD_Pixel458_OnOff 2;
BA_ "GenSigSendType" SG_ 1362 ICC_LISD_Pixel459_OnOff 2;
BA_ "GenSigSendType" SG_ 1362 ICC_LISD_Pixel460_OnOff 2;
BA_ "GenSigSendType" SG_ 1362 ICC_LISD_Pixel461_OnOff 2;
BA_ "GenSigSendType" SG_ 1362 ICC_LISD_Pixel462_OnOff 2;
BA_ "GenSigSendType" SG_ 1362 ICC_LISD_Pixel463_OnOff 2;
BA_ "GenSigSendType" SG_ 1362 ICC_LISD_Pixel464_OnOff 2;
BA_ "GenSigSendType" SG_ 1362 ICC_LISD_Pixel465_OnOff 2;
BA_ "GenSigSendType" SG_ 1362 ICC_LISD_Pixel466_OnOff 2;
BA_ "GenSigSendType" SG_ 1362 ICC_LISD_Pixel467_OnOff 2;
BA_ "GenSigSendType" SG_ 1362 ICC_LISD_Pixel468_OnOff 2;
BA_ "GenSigSendType" SG_ 1362 ICC_LISD_Pixel469_OnOff 2;
BA_ "GenSigSendType" SG_ 1362 ICC_LISD_Pixel470_OnOff 2;
BA_ "GenSigSendType" SG_ 1362 ICC_LISD_Pixel471_OnOff 2;
BA_ "GenSigSendType" SG_ 1362 ICC_LISD_Pixel472_OnOff 2;
BA_ "GenSigSendType" SG_ 1362 ICC_LISD_Pixel473_OnOff 2;
BA_ "GenSigSendType" SG_ 1362 ICC_LISD_Pixel474_OnOff 2;
BA_ "GenSigSendType" SG_ 1362 ICC_LISD_Pixel475_OnOff 2;
BA_ "GenSigSendType" SG_ 1362 ICC_LISD_Pixel476_OnOff 2;
BA_ "GenSigSendType" SG_ 1362 ICC_LISD_Pixel477_OnOff 2;
BA_ "GenSigSendType" SG_ 1362 ICC_LISD_Pixel478_OnOff 2;
BA_ "GenSigSendType" SG_ 1362 ICC_LISD_Pixel479_OnOff 2;
BA_ "GenSigSendType" SG_ 1362 ICC_LISD_Pixel480_OnOff 2;
BA_ "GenSigSendType" SG_ 1362 ICC_LISD_Pixel481_OnOff 2;
BA_ "GenSigSendType" SG_ 1362 ICC_LISD_Pixel482_OnOff 2;
BA_ "GenSigSendType" SG_ 1362 ICC_LISD_Pixel483_OnOff 2;
BA_ "GenSigSendType" SG_ 1362 ICC_LISD_Pixel484_OnOff 2;
BA_ "GenSigSendType" SG_ 1362 ICC_LISD_Pixel485_OnOff 2;
BA_ "GenSigSendType" SG_ 1362 ICC_LISD_Pixel486_OnOff 2;
BA_ "GenSigSendType" SG_ 1362 ICC_LISD_Pixel487_OnOff 2;
BA_ "GenSigSendType" SG_ 1362 ICC_LISD_Pixel488_OnOff 2;
BA_ "GenSigSendType" SG_ 1362 ICC_LISD_Pixel489_OnOff 2;
BA_ "GenSigSendType" SG_ 1362 ICC_LISD_Pixel490_OnOff 2;
BA_ "GenSigSendType" SG_ 1362 ICC_LISD_Pixel491_OnOff 2;
BA_ "GenSigSendType" SG_ 1362 ICC_LISD_Pixel492_OnOff 2;
BA_ "GenSigSendType" SG_ 1362 ICC_LISD_Pixel493_OnOff 2;
BA_ "GenSigSendType" SG_ 1362 ICC_LISD_Pixel494_OnOff 2;
BA_ "GenSigSendType" SG_ 1362 ICC_LISD_Pixel495_OnOff 2;
BA_ "GenSigSendType" SG_ 1362 ICC_LISD_Pixel496_OnOff 2;
BA_ "GenSigSendType" SG_ 1362 ICC_LISD_Pixel497_OnOff 2;
BA_ "GenSigSendType" SG_ 1362 ICC_LISD_Pixel498_OnOff 2;
BA_ "GenSigSendType" SG_ 1362 ICC_LISD_Pixel499_OnOff 2;
BA_ "GenSigSendType" SG_ 1362 ICC_LISD_Pixel500_OnOff 2;
BA_ "GenSigSendType" SG_ 1362 ICC_LISD_Pixel501_OnOff 2;
BA_ "GenSigSendType" SG_ 1362 ICC_LISD_Pixel502_OnOff 2;
BA_ "GenSigSendType" SG_ 1362 ICC_LISD_Pixel503_OnOff 2;
BA_ "GenSigSendType" SG_ 1362 ICC_LISD_Pixel504_OnOff 2;
VAL_ 1333 ICC_SRFCmd 0 "Not Active" 1 "Open" 2 "Close" 3 "Tilt" 4 "Reserved" 5 "Reserved" 6 "Reserved" 7 "Reserved" ;
VAL_ 1333 ICC_SRFPercentCmd 0 "Not Active" 1 "0" 2 "10%" 3 "20%" 4 "30%" 5 "40%" 6 "50%" 7 "60%" 8 "70%" 9 "80%" 10 "90%" 11 "100%" ;
VAL_ 1333 ICC_SunshadeCmd 0 "Not Acitive" 1 "Open" 2 "Close" 3 "Half_Open" 4 "Reserved" 5 "Reserved" 6 "Reserved" 7 "Reserved" ;
VAL_ 1333 ICC_SunshadePercentCmd 0 "No Acitive" 1 "0%" 2 "10%" 3 "20%" 4 "30%" 5 "40%" 6 "50%" 7 "60%" 8 "70%" 9 "80%" 10 "90%" 11 "100%" ;
VAL_ 1333 ICC_CSunshadeReq 0 "Not Active" 1 "Open" 2 "Close" 3 "HalfOpen" ;
VAL_ 1333 ICC_CSunshadePercentReq 0 "Not Active" 1 "0%" 2 "10%" 3 "20%" 4 "30%" 5 "40%" 6 "50%" 7 "60%" 8 "70%" 9 "80%" 10 "90%" 11 "100%" ;
VAL_ 1333 CSunshadeLearnedReq_535h 0 "Not Active" 1 "StartLearn" 2 "StopLearn" 3 "reserved" ;
VAL_ 1333 CSunshadePercentReq_535h 0 "No request" 1 "Sunshade 0%" 2 "Sunshade 1%" 3 "Sunshade 2%" 4 "Sunshade 3%" 5 "Sunshade 4%" 6 "Sunshade 5%" 7 "Sunshade 6%" 8 "Sunshade 7%" 9 "Sunshade 8%" 10 "Sunshade 9%" 11 "Sunshade 10%" 12 "Sunshade 11%" 13 "Sunshade 12%" 14 "Sunshade 13%" 15 "Sunshade 14%" 16 "Sunshade 15%" 17 "Sunshade 16%" 18 "Sunshade 17%" 19 "Sunshade 18%" 20 "Sunshade 19%" 21 "Sunshade 20%" 22 "Sunshade 21%" 23 "Sunshade 22%" 24 "Sunshade 23%" 25 "Sunshade 24%" 26 "Sunshade 25%" 27 "Sunshade 26%" 28 "Sunshade 27%" 29 "Sunshade 28%" 30 "Sunshade 29%" 31 "Sunshade 30%" 32 "Sunshade 31%" 33 "Sunshade 32%" 34 "Sunshade 33%" 35 "Sunshade 34%" 36 "Sunshade 35%" 37 "Sunshade 36%" 38 "Sunshade 37%" 39 "Sunshade 38%" 40 "Sunshade 39%" 41 "Sunshade 40%" 42 "Sunshade 41%" 43 "Sunshade 42%" 44 "Sunshade 43%" 45 "Sunshade 44%" 46 "Sunshade 45%" 47 "Sunshade 46%" 48 "Sunshade 47%" 49 "Sunshade 48%" 50 "Sunshade 49%" 51 "Sunshade 50%" 52 "Sunshade 51%" 53 "Sunshade 52%" 54 "Sunshade 53%" 55 "Sunshade 54%" 56 "Sunshade 55%" 57 "Sunshade 56%" 58 "Sunshade 57%" 59 "Sunshade 58%" 60 "Sunshade 59%" 61 "Sunshade 60%" 62 "Sunshade 61%" 63 "Sunshade 62%" 64 "Sunshade 63%" 65 "Sunshade 64%" 66 "Sunshade 65%" 67 "Sunshade 66%" 68 "Sunshade 67%" 69 "Sunshade 68%" 70 "Sunshade 69%" 71 "Sunshade 70%" 72 "Sunshade 71%" 73 "Sunshade 72%" 74 "Sunshade 73%" 75 "Sunshade 74%" 76 "Sunshade 75%" 77 "Sunshade 76%" 78 "Sunshade 77%" 79 "Sunshade 78%" 80 "Sunshade 79%" 81 "Sunshade 80%" 82 "Sunshade 81%" 83 "Sunshade 82%" 84 "Sunshade 83%" 85 "Sunshade 84%" 86 "Sunshade 85%" 87 "Sunshade 86%" 88 "Sunshade 87%" 89 "Sunshade 88%" 90 "Sunshade 89%" 91 "Sunshade 90%" 92 "Sunshade 91%" 93 "Sunshade 92%" 94 "Sunshade 93%" 95 "Sunshade 94%" 96 "Sunshade 95%" 97 "Sunshade 96%" 98 "Sunshade 97%" 99 "Sunshade 98%" 100 "Sunshade 99%" 101 "Sunshade 100%" 102 "Stop" 103 "initialize" 104 "Reserved" 105 "Reserved" 106 "Reserved" 107 "Reserved" 108 "Reserved" 109 "Reserved" 110 "Reserved" 111 "Reserved" 112 "Reserved" 113 "Reserved" 114 "Reserved" 115 "Reserved" 116 "Reserved" 117 "Reserved" 118 "Reserved" 119 "Reserved" 120 "Reserved" 121 "Reserved" 122 "Reserved" 123 "Reserved" 124 "Reserved" 125 "Reserved" 126 "Reserved" 127 "Reserved" 128 "Reserved" 129 "Reserved" 130 "Reserved" 131 "Reserved" 132 "Reserved" 133 "Reserved" 134 "Reserved" 135 "Reserved" 136 "Reserved" 137 "Reserved" 138 "Reserved" 139 "Reserved" 140 "Reserved" 141 "Reserved" 142 "Reserved" 143 "Reserved" 144 "Reserved" 145 "Reserved" 146 "Reserved" 147 "Reserved" 148 "Reserved" 149 "Reserved" 150 "Reserved" 151 "Reserved" 152 "Reserved" 153 "Reserved" 154 "Reserved" 155 "Reserved" 156 "Reserved" 157 "Reserved" 158 "Reserved" 159 "Reserved" 160 "Reserved" 161 "Reserved" 162 "Reserved" 163 "Reserved" 164 "Reserved" 165 "Reserved" 166 "Reserved" 167 "Reserved" 168 "Reserved" 169 "Reserved" 170 "Reserved" 171 "Reserved" 172 "Reserved" 173 "Reserved" 174 "Reserved" 175 "Reserved" 176 "Reserved" 177 "Reserved" 178 "Reserved" 179 "Reserved" 180 "Reserved" 181 "Reserved" 182 "Reserved" 183 "Reserved" 184 "Reserved" 185 "Reserved" 186 "Reserved" 187 "Reserved" 188 "Reserved" 189 "Reserved" 190 "Reserved" 191 "Reserved" 192 "Reserved" 193 "Reserved" 194 "Reserved" 195 "Reserved" 196 "Reserved" 197 "Reserved" 198 "Reserved" 199 "Reserved" 200 "Reserved" 201 "Reserved" 202 "Reserved" 203 "Reserved" 204 "Reserved" 205 "Reserved" 206 "Reserved" 207 "Reserved" 208 "Reserved" 209 "Reserved" 210 "Reserved" 211 "Reserved" 212 "Reserved" 213 "Reserved" 214 "Reserved" 215 "Reserved" 216 "Reserved" 217 "Reserved" 218 "Reserved" 219 "Reserved" 220 "Reserved" 221 "Reserved" 222 "Reserved" 223 "Reserved" 224 "Reserved" 225 "Reserved" 226 "Reserved" 227 "Reserved" 228 "Reserved" 229 "Reserved" 230 "Reserved" 231 "Reserved" 232 "Reserved" 233 "Reserved" 234 "Reserved" 235 "Reserved" 236 "Reserved" 237 "Reserved" 238 "Reserved" 239 "Reserved" 240 "Reserved" 241 "Reserved" 242 "Reserved" 243 "Reserved" 244 "Reserved" 245 "Reserved" 246 "Reserved" 247 "Reserved" 248 "Reserved" 249 "Reserved" 250 "Reserved" 251 "Reserved" 252 "Reserved" 253 "Reserved" 254 "Reserved" 255 "Reserved" ;
VAL_ 1335 ICC_SET_EPS_SteerReturnRmdSts 0 "Not Active" 1 "ON" 2 "OFF" 3 "reserved" ;
VAL_ 1335 ICC_SET_MFSShake 0 "Not Active" 1 "ON" 2 "OFF" 3 "reserved" ;
VAL_ 1335 ICC_DMS_1_DistractionLevel 0 "Not Active" 1 "DISTRACTION_LEVEL_LIGHT" 2 "DISTRACTION_LEVEL_MEDIUM" 3 "DISTRACTION_LEVEL_HEAVY" ;
VAL_ 1335 ICC_SET_EPS_AsociWithDrvModSts 0 "Not_Active" 1 "ON" 2 "OFF" 3 "reserved" ;
VAL_ 1335 ICC_OverLoadWarnShieldSet 0 "Not Active" 1 "ON" 2 "OFF" 3 "reserved" ;
VAL_ 1335 ICC_BSWReq 0 "Not Active" 1 "ON" 2 "OFF" 3 "reserved" ;
VAL_ 1335 ICC_horizontalReq 0 "Not Active" 1 "ON" 2 "OFF" 3 "Not Used" ;
VAL_ 1335 ICC_RolloverSetCmd 0 "Not Active" 1 "Rollover Deploy OFF" 2 "Rollover Deploy ON" 3 "reserved" ;
VAL_ 1335 ICC_TrekThroughReq_537h 0 "Not Active" 1 "ON" 2 "OFF" 3 "Reserved" ;
VAL_ 1335 ICC_InflateReq_537h 0 "Not Active" 1 "ON" 2 "OFF" 3 "Reserved" ;
VAL_ 1335 ICC_UndergroundModeReq_537h 0 "Not Active" 1 "ON" 2 "OFF" 3 "Reserved" ;
VAL_ 1335 ICC_SandABSSw_537h 0 "Not_Active" 1 "ON" 2 "OFF" 3 "Reserved" ;
VAL_ 1335 ICC_SandABSCmd_537h 0 "Not_Active" 1 "ON" 2 "OFF" 3 "Reserved" ;
VAL_ 1335 ICC_EPBAUTOCmd_537h 0 "Not_Active" 1 "Switch_On" 2 "Switch_Off" 3 "Not_Used" ;
VAL_ 1335 ICC_SpeParkSet_537h 0 "Not_Active" 1 "ON" 2 "OFF" 3 "Not_Used" ;
VAL_ 1337 ICC_SET_BT_ReduceWindSpeed 0 "Not_Active" 1 "ON" 2 "OFF" 3 "Reserved" ;
VAL_ 1337 ICC_SET_IPM_FirstBlowing 0 "Not Active" 1 "ON" 2 "OFF" 3 "Reserved" ;
VAL_ 1337 ICC_SET_IPM_BlowerDelay 0 "Not Active" 1 "ON" 2 "OFF" 3 "Reserved" ;
VAL_ 1337 ICC_SET_CirculationInTunnels 0 "Not Active" 1 "ON" 2 "OFF" 3 "Reserved" ;
VAL_ 1337 ICC_UVCLuminanceReq 0 "Not Active" 1 "high" 2 "lower" 3 "reserved" ;
VAL_ 1337 ICC_UVCControlReq 0 "Not Active" 1 "ON" 2 "OFF" 3 "AUTO" ;
VAL_ 1337 ICC_CrossCountryCoolingReq 0 "Not Active" 1 "ON" 2 "OFF" 3 "Reserved" ;
VAL_ 1337 ICC_KeepWarmReq 0 "Not Active" 1 "Open_AC" 2 "Open_NotAC" 3 "Closed" ;
VAL_ 1337 ICC_keepwarmSetTemperatureReq 0 "Not Active" 1 "Temperature 20°C" 2 "Temperature 25°C" 3 "Temperature 30°C" 4 "Temperature 35°C" 5 "Temperature 40°C" 6 "Temperature 45°C" 7 "Temperature 50°C" 8 "Temperature 55°C" 9 "Temperature 60°C" ;
VAL_ 1337 ICC_ParkingAirConditioning 0 "Not Active" 1 "Disable" 2 "AUTO" 3 "ventilate" ;
VAL_ 1337 ICC_CoolantFill_Req 0 "Not Active" 1 "ON" 2 "OFF" 3 "Reserved" ;
VAL_ 1337 ICC_FraganceLightoffReq 0 "No Active" 1 "FraganceLight_on" 2 "FraganceLight_off" 3 "Reserved" ;
VAL_ 1337 ICC_FraganceMemoffReq 0 "Not_Active" 1 "FraganceMem_on" 2 "FraganceMem_off" 3 "Reserved" ;
VAL_ 1337 ICC_TimingLevel 0 "Not_Active" 1 "CFSTiming level1" 2 "CFSTiming level2" 3 "CFSTiming level3" 4 "CFSTiming level4" 5 "reserved" 6 "reserved" 7 "reserved" ;
VAL_ 1337 ICC_CFSCycleLevel 0 "Not_Active" 1 "CFSCycle level1" 2 "CFSCycle level2" 3 "CFSCycle level3" 4 "CFSCycle level4" 5 "reserved" 6 "reserved" 7 "reserved" ;
VAL_ 1337 ICC_AirPurgeReminderReq 0 "Not_Active" 1 "ON" 2 "OFF" 3 "Not_Used" ;
VAL_ 1337 ICC_TimedVentilationReq 0 "Not Active" 1 "ON" 2 "OFF" 3 "Reserved" ;
VAL_ 1337 ICC_BiochemicalFuncReq 0 "Not Active" 1 "ON" 2 "OFF" 3 "Reserved" ;
VAL_ 1337 ICC_ModeAdjustDisplaySts 0 "BlowFace" 1 "BlowFaceAndBlowFoot" 2 "BlowFoot" 3 "BlowFootAndBlowWindow" 4 "BlowWindow" 5 "Not Active" 6 "BlowFaceAndBlowWindow" 7 "BlowFaceAndBlowFootAndBlowWindow" 8 "Auto" 9 "reserved" 10 "reserved" 11 "reserved" 12 "reserved" 13 "reserved" 14 "reserved" 15 "reserved" ;
VAL_ 1337 ICC_PetModeSetTemperature_R_C 31 "Not active" ;
VAL_ 1337 ICC_PetmodeSetTemperature_L_C 31 "Not active" ;
VAL_ 1337 ICC_PetModeSetCirculationSts 0 "Not Active" 1 "Recirculation mode" 2 "Air circulation mode" 3 "Two-Layer Flow Mode" ;
VAL_ 1337 ICC_PetModeSetAutoKeySts 0 "Not Active" 1 "On" 2 "Off" 3 "Not Used" ;
VAL_ 1337 ICC_PetModeSetCLMOn 0 "Not Active" 1 "On" 2 "Off" 3 "Not Used" ;
VAL_ 1337 ICC_ISSFctCmd_539h 0 "Not Active" 1 "ON" 2 "OFF" 3 "Not Used" ;
VAL_ 1338 FMCU_ErrLvlDis 0 "No Error" 1 "Err_level1" 2 "Err_level2" 3 "Err_level3" 4 "Err_level4" 5 "Err_level5" 6 "Err_level6" ;
VAL_ 1338 FMCU_SpdAct_EDR 65535 "Invalid" ;
VAL_ 1345 DVR_1_DVRFailReasons 0 "NoFailure" 1 "DVR360StorageFailure" 2 "DVRFCMStorageFailure" 3 "DVRAllFailure" 4 "Reserved" 5 "Reserved" 6 "Reserved" 7 "Reserved" ;
VAL_ 1345 DVR_1_RecordSts 0 "Initinal" 1 "Recording" 2 "RecordStop" 3 "Reserved" ;
VAL_ 1345 DVR_1_Sdcard_Sts 0 "Normal" 1 "Not inserted" 2 "Filesystem unsupported" 3 "Capacity unsupported" 4 "Abnormal" 5 "Full" 6 "Reserved" 7 "Reserved" ;
VAL_ 1349 SBOX_MSD_Res 0 "Reserved" 1 "send successfully" 2 "no signal" 3 "uncast net" 4 "short messages not enough" ;
VAL_ 1349 SBOX_Ecallphonenub_Res 0 "Reserved" 1 "dialing" 2 "ringing" 3 "on the line" 4 "hang up" 5 "no signal" 6 "uncast net" ;
VAL_ 1353 SBOX_ICC_MACReq 0 "invalid" 1 "request connect" ;
VAL_ 1356 ICC_flag 0 "invalid" 1 "sim" 2 "tsp register" ;
VAL_ 1356 ICC_ActiveTsp_Req 0 "invalid" 1 "Do not initiate TSP registration" 2 "initiate TSP registration" ;
VAL_ 1356 ICC_ActiveSim_Req 0 "invalid" 1 "sim not activate" 2 "sim activate" ;
VAL_ 1356 ICC_GetMac_req 0 "invalid" 1 "search" ;
VAL_ 1356 ICC_GetIccid_Vin 0 "invalid" 1 "search" ;
VAL_ 1356 ICC_GivePlatformNumber_Flag 0 "platform_number invalid" 1 "platform_number valid" ;
VAL_ 1356 ICC_Mac_Flag 0 "IccMacInvalid" 1 "IccMacValid" ;
VAL_ 1360 ICC_LISD_DisplaySwitch 0 "Default value" 1 "Display ON" 2 "Display OFF" 3 "Reserved" ;
VAL_ 1360 ICC_LISD_ParkingShowCMD 0 "Default value" 1 "ON" 2 "OFF" 3 "Reserved" ;
VAL_ 1360 ICC_RISD_DisplaySwitch 0 "Default value" 1 "Display ON" 2 "Display OFF" 3 "Reserved" ;
VAL_ 1360 ICC_RISD_ParkingShowCMD 0 "Default value" 1 "ON" 2 "OFF" 3 "Reserved" ;
VAL_ 1360 ICC_LogoParkingReq 0 "Not Active" 1 "ON" 2 "OFF" 3 "Reserved" ;
VAL_ 1360 ICC_LogoChargingReq 0 "Not Active" 1 "ON" 2 "OFF" 3 "Reserved" ;
VAL_ 1360 ICC_DRLSw 0 "Not active" 1 "ON" 2 "OFF" 3 "Reserved" ;
VAL_ 1360 ICC_LISD_ParkingShowMod 0 "Default value" 1 "Mode1" 2 "Mode2" 3 "Mode3" 4 "Mode4" 5 "Reserved" 6 "Reserved" 7 "Reserved" 8 "Reserved" 9 "Reserved" 10 "Reserved" 11 "Reserved" 12 "Reserved" 13 "Reserved" 14 "Reserved" 15 "Reserved" ;
VAL_ 1360 ICC_RISD_ParkingShowMod 0 "Default value" 1 "Mode1" 2 "Mode2" 3 "Mode3" 4 "Mode4" 5 "Reserved" 6 "Reserved" 7 "Reserved" 8 "Reserved" 9 "Reserved" 10 "Reserved" 11 "Reserved" 12 "Reserved" 13 "Reserved" 14 "Reserved" 15 "Reserved" ;
VAL_ 1360 ICC_LogoColorReq 0 "Not_Active" ;
VAL_ 1360 ICC_MusicLampShowSW 0 "Not active" 1 "OFF" 2 "ON" 3 "Reserved" ;
VAL_ 1360 ICC_PenetrationLampSetF 0 "Not_Active" 1 "ON" 2 "OFF" 3 "reserved" ;
VAL_ 1360 ICC_XDriveMode 0 "Not Active" 1 "unidentifiable" 2 "Normal" 3 "SNOW" 4 "MUD" 5 "ROCK" 6 "SAND" 7 "WATERSURFACE" 8 "Normal" 9 "SNOW" 10 "MUD" 11 "ROCK" 12 "SAND" 13 "WATERSURFACE" 14 "Normal" 15 "SNOW" 16 "MUD" 17 "ROCK" 18 "SAND" 19 "Reserved" 20 "Reserved" 21 "Reserved" 22 "Reserved" 23 "Reserved" 24 "Reserved" 25 "Reserved" 26 "Reserved" 27 "Reserved" 28 "Reserved" 29 "Reserved" 30 "Reserved" 31 "Reserved" ;
VAL_ 1360 ICC_DowWaringSw 0 "Not_Active" 1 "ON" 2 "OFF" 3 "reserved" ;
VAL_ 1360 ICC_CarSearhSetSwitchSts 0 "Not Active" 1 "Only Lighting" 2 "Sound and Lighting" 3 "Reserved" ;
VAL_ 1360 ICC_TDL_NightBright_SW_550h 0 "Not_Active" 1 "ON" 2 "OFF" 3 "reserved" ;
VAL_ 1361 EPC_LeftPedalSystem_Sts 0 "Normal" 1 "Voltage_protect" 2 "System_fault" 3 "Over_temperature" 4 "Disable_mode" 5 "Left_steer" 6 "Left_pedal_Anti-pinch" 7 "Reserved" 8 "Reserved" 9 "Reserved" 10 "Reserved" 11 "Reserved" 12 "Reserved" 13 "Reserved" 14 "Reserved" 15 "Reserved" ;
VAL_ 1361 EPC_RightPedalSystem_Sts 0 "Normal" 1 "Voltage_protect" 2 "System_fault" 3 "Over_temperature" 4 "Disable_mode" 5 "Right_steer" 6 "Right_pedal_Anti-pinch" 7 "Reserved" 8 "Reserved" 9 "Reserved" 10 "Reserved" 11 "Reserved" 12 "Reserved" 13 "Reserved" 14 "Reserved" 15 "Reserved" ;
VAL_ 1361 EPC_RightPedalRealTime_Sts 0 "Invalid" 1 "Right_pedal_retract_back_in_place" 2 "Right_pedal_is_retracting" 3 "Right_pedal_retract_failed" 4 "Right_pedal_spread_in_place" 5 "Right_pedal_is_spreading" 6 "Right_pedal_is_spread_failed" 7 "Reserved" ;
VAL_ 1361 EPC_LeftPedalBreakIce_Sts 0 "Invalid" 1 "Left_pedal_is_breaking_ice" 2 "Left_pedal_break_ice_successfully" 3 "Left_pedal_break_ice_failed" ;
VAL_ 1361 EPC_LeftPedalRealTime_Sts 0 "Invalid" 1 "Left_pedal_retract_back_in_place" 2 "Left_pedal_is_retracting" 3 "Left_pedal_retract_failed" 4 "Left_pedal_spread_in_place" 5 "Left_pedal_is_spreading" 6 "Left_pedal_is_spread_failed" 7 "Reserved" ;
VAL_ 1361 EPC_RightPedalCmdStatus 0 "Not active" 1 "Spread_RightPedal" 2 "Retract_RightPedal" 3 "Auto" ;
VAL_ 1361 EPC_LeftPedalCmdStatus 0 "Not active" 1 "Spread_LeftPedal" 2 "Retract_LeftPedal" 3 "Auto" ;
VAL_ 1361 EPC_Enable_CmdStatus 0 "Not active" 1 "ON" 2 "OFF" 3 "Invaild" ;
VAL_ 1361 EPC_RightPedalBreakIce_Sts 0 "Invalid" 1 "Right_pedal_is_breaking_ice" 2 "Right_pedal_break_ice_successfully" 3 "Right_pedal_break_ice_failed" ;
VAL_ 1361 EPC_RightPedal3D_Sts 0 "Not Active" 1 "Open" 2 "Close" 3 "Reserved" ;
VAL_ 1361 EPC_LeftPedal3D_Sts 0 "Not Active" 1 "Open" 2 "Close" 3 "Reserved" ;
VAL_ 1362 ICC_LISD_FrameCounter 0 "FrameCounter 0" 1 "FrameCounter 1" 2 "FrameCounter 2" 3 "FrameCounter 3" ;
VAL_ 1362 ICC_LISD_RollingCounter 0 "Counter 0" 1 "Counter 1" 2 "Counter 2" ;
VAL_ 1362 ICC_LISD_Pixel1_OnOff 0 "Pixel On" 1 "Pixel Off" ;
VAL_ 1362 ICC_LISD_Pixel2_OnOff 0 "Pixel On" 1 "Pixel Off" ;
VAL_ 1362 ICC_LISD_Pixel3_OnOff 0 "Pixel On" 1 "Pixel Off" ;
VAL_ 1362 ICC_LISD_Pixel4_OnOff 0 "Pixel On" 1 "Pixel Off" ;
VAL_ 1362 ICC_LISD_Pixel5_OnOff 0 "Pixel On" 1 "Pixel Off" ;
VAL_ 1362 ICC_LISD_Pixel6_OnOff 0 "Pixel On" 1 "Pixel Off" ;
VAL_ 1362 ICC_LISD_Pixel7_OnOff 0 "Pixel On" 1 "Pixel Off" ;
VAL_ 1362 ICC_LISD_Pixel8_OnOff 0 "Pixel On" 1 "Pixel Off" ;
VAL_ 1362 ICC_LISD_Pixel9_OnOff 0 "Pixel On" 1 "Pixel Off" ;
VAL_ 1362 ICC_LISD_Pixel10_OnOff 0 "Pixel On" 1 "Pixel Off" ;
VAL_ 1362 ICC_LISD_Pixel11_OnOff 0 "Pixel On" 1 "Pixel Off" ;
VAL_ 1362 ICC_LISD_Pixel12_OnOff 0 "Pixel On" 1 "Pixel Off" ;
VAL_ 1362 ICC_LISD_Pixel13_OnOff 0 "Pixel On" 1 "Pixel Off" ;
VAL_ 1362 ICC_LISD_Pixel14_OnOff 0 "Pixel On" 1 "Pixel Off" ;
VAL_ 1362 ICC_LISD_Pixel15_OnOff 0 "Pixel On" 1 "Pixel Off" ;
VAL_ 1362 ICC_LISD_Pixel16_OnOff 0 "Pixel On" 1 "Pixel Off" ;
VAL_ 1362 ICC_LISD_Pixel17_OnOff 0 "Pixel On" 1 "Pixel Off" ;
VAL_ 1362 ICC_LISD_Pixel18_OnOff 0 "Pixel On" 1 "Pixel Off" ;
VAL_ 1362 ICC_LISD_Pixel19_OnOff 0 "Pixel On" 1 "Pixel Off" ;
VAL_ 1362 ICC_LISD_Pixel20_OnOff 0 "Pixel On" 1 "Pixel Off" ;
VAL_ 1362 ICC_LISD_Pixel21_OnOff 0 "Pixel On" 1 "Pixel Off" ;
VAL_ 1362 ICC_LISD_Pixel22_OnOff 0 "Pixel On" 1 "Pixel Off" ;
VAL_ 1362 ICC_LISD_Pixel23_OnOff 0 "Pixel On" 1 "Pixel Off" ;
VAL_ 1362 ICC_LISD_Pixel24_OnOff 0 "Pixel On" 1 "Pixel Off" ;
VAL_ 1362 ICC_LISD_Pixel25_OnOff 0 "Pixel On" 1 "Pixel Off" ;
VAL_ 1362 ICC_LISD_Pixel26_OnOff 0 "Pixel On" 1 "Pixel Off" ;
VAL_ 1362 ICC_LISD_Pixel27_OnOff 0 "Pixel On" 1 "Pixel Off" ;
VAL_ 1362 ICC_LISD_Pixel28_OnOff 0 "Pixel On" 1 "Pixel Off" ;
VAL_ 1362 ICC_LISD_Pixel29_OnOff 0 "Pixel On" 1 "Pixel Off" ;
VAL_ 1362 ICC_LISD_Pixel30_OnOff 0 "Pixel On" 1 "Pixel Off" ;
VAL_ 1362 ICC_LISD_Pixel31_OnOff 0 "Pixel On" 1 "Pixel Off" ;
VAL_ 1362 ICC_LISD_Pixel32_OnOff 0 "Pixel On" 1 "Pixel Off" ;
VAL_ 1362 ICC_LISD_Pixel33_OnOff 0 "Pixel On" 1 "Pixel Off" ;
VAL_ 1362 ICC_LISD_Pixel34_OnOff 0 "Pixel On" 1 "Pixel Off" ;
VAL_ 1362 ICC_LISD_Pixel35_OnOff 0 "Pixel On" 1 "Pixel Off" ;
VAL_ 1362 ICC_LISD_Pixel36_OnOff 0 "Pixel On" 1 "Pixel Off" ;
VAL_ 1362 ICC_LISD_Pixel37_OnOff 0 "Pixel On" 1 "Pixel Off" ;
VAL_ 1362 ICC_LISD_Pixel38_OnOff 0 "Pixel On" 1 "Pixel Off" ;
VAL_ 1362 ICC_LISD_Pixel39_OnOff 0 "Pixel On" 1 "Pixel Off" ;
VAL_ 1362 ICC_LISD_Pixel40_OnOff 0 "Pixel On" 1 "Pixel Off" ;
VAL_ 1362 ICC_LISD_Pixel41_OnOff 0 "Pixel On" 1 "Pixel Off" ;
VAL_ 1362 ICC_LISD_Pixel42_OnOff 0 "Pixel On" 1 "Pixel Off" ;
VAL_ 1362 ICC_LISD_Pixel43_OnOff 0 "Pixel On" 1 "Pixel Off" ;
VAL_ 1362 ICC_LISD_Pixel44_OnOff 0 "Pixel On" 1 "Pixel Off" ;
VAL_ 1362 ICC_LISD_Pixel45_OnOff 0 "Pixel On" 1 "Pixel Off" ;
VAL_ 1362 ICC_LISD_Pixel46_OnOff 0 "Pixel On" 1 "Pixel Off" ;
VAL_ 1362 ICC_LISD_Pixel47_OnOff 0 "Pixel On" 1 "Pixel Off" ;
VAL_ 1362 ICC_LISD_Pixel48_OnOff 0 "Pixel On" 1 "Pixel Off" ;
VAL_ 1362 ICC_LISD_Pixel49_OnOff 0 "Pixel On" 1 "Pixel Off" ;
VAL_ 1362 ICC_LISD_Pixel50_OnOff 0 "Pixel On" 1 "Pixel Off" ;
VAL_ 1362 ICC_LISD_Pixel51_OnOff 0 "Pixel On" 1 "Pixel Off" ;
VAL_ 1362 ICC_LISD_Pixel52_OnOff 0 "Pixel On" 1 "Pixel Off" ;
VAL_ 1362 ICC_LISD_Pixel53_OnOff 0 "Pixel On" 1 "Pixel Off" ;
VAL_ 1362 ICC_LISD_Pixel54_OnOff 0 "Pixel On" 1 "Pixel Off" ;
VAL_ 1362 ICC_LISD_Pixel55_OnOff 0 "Pixel On" 1 "Pixel Off" ;
VAL_ 1362 ICC_LISD_Pixel56_OnOff 0 "Pixel On" 1 "Pixel Off" ;
VAL_ 1362 ICC_LISD_Pixel57_OnOff 0 "Pixel On" 1 "Pixel Off" ;
VAL_ 1362 ICC_LISD_Pixel58_OnOff 0 "Pixel On" 1 "Pixel Off" ;
VAL_ 1362 ICC_LISD_Pixel59_OnOff 0 "Pixel On" 1 "Pixel Off" ;
VAL_ 1362 ICC_LISD_Pixel60_OnOff 0 "Pixel On" 1 "Pixel Off" ;
VAL_ 1362 ICC_LISD_Pixel61_OnOff 0 "Pixel On" 1 "Pixel Off" ;
VAL_ 1362 ICC_LISD_Pixel62_OnOff 0 "Pixel On" 1 "Pixel Off" ;
VAL_ 1362 ICC_LISD_Pixel63_OnOff 0 "Pixel On" 1 "Pixel Off" ;
VAL_ 1362 ICC_LISD_Pixel64_OnOff 0 "Pixel On" 1 "Pixel Off" ;
VAL_ 1362 ICC_LISD_Pixel65_OnOff 0 "Pixel On" 1 "Pixel Off" ;
VAL_ 1362 ICC_LISD_Pixel66_OnOff 0 "Pixel On" 1 "Pixel Off" ;
VAL_ 1362 ICC_LISD_Pixel67_OnOff 0 "Pixel On" 1 "Pixel Off" ;
VAL_ 1362 ICC_LISD_Pixel68_OnOff 0 "Pixel On" 1 "Pixel Off" ;
VAL_ 1362 ICC_LISD_Pixel69_OnOff 0 "Pixel On" 1 "Pixel Off" ;
VAL_ 1362 ICC_LISD_Pixel70_OnOff 0 "Pixel On" 1 "Pixel Off" ;
VAL_ 1362 ICC_LISD_Pixel71_OnOff 0 "Pixel On" 1 "Pixel Off" ;
VAL_ 1362 ICC_LISD_Pixel72_OnOff 0 "Pixel On" 1 "Pixel Off" ;
VAL_ 1362 ICC_LISD_Pixel73_OnOff 0 "Pixel On" 1 "Pixel Off" ;
VAL_ 1362 ICC_LISD_Pixel74_OnOff 0 "Pixel On" 1 "Pixel Off" ;
VAL_ 1362 ICC_LISD_Pixel75_OnOff 0 "Pixel On" 1 "Pixel Off" ;
VAL_ 1362 ICC_LISD_Pixel76_OnOff 0 "Pixel On" 1 "Pixel Off" ;
VAL_ 1362 ICC_LISD_Pixel77_OnOff 0 "Pixel On" 1 "Pixel Off" ;
VAL_ 1362 ICC_LISD_Pixel78_OnOff 0 "Pixel On" 1 "Pixel Off" ;
VAL_ 1362 ICC_LISD_Pixel79_OnOff 0 "Pixel On" 1 "Pixel Off" ;
VAL_ 1362 ICC_LISD_Pixel80_OnOff 0 "Pixel On" 1 "Pixel Off" ;
VAL_ 1362 ICC_LISD_Pixel81_OnOff 0 "Pixel On" 1 "Pixel Off" ;
VAL_ 1362 ICC_LISD_Pixel82_OnOff 0 "Pixel On" 1 "Pixel Off" ;
VAL_ 1362 ICC_LISD_Pixel83_OnOff 0 "Pixel On" 1 "Pixel Off" ;
VAL_ 1362 ICC_LISD_Pixel84_OnOff 0 "Pixel On" 1 "Pixel Off" ;
VAL_ 1362 ICC_LISD_Pixel85_OnOff 0 "Pixel On" 1 "Pixel Off" ;
VAL_ 1362 ICC_LISD_Pixel86_OnOff 0 "Pixel On" 1 "Pixel Off" ;
VAL_ 1362 ICC_LISD_Pixel87_OnOff 0 "Pixel On" 1 "Pixel Off" ;
VAL_ 1362 ICC_LISD_Pixel88_OnOff 0 "Pixel On" 1 "Pixel Off" ;
VAL_ 1362 ICC_LISD_Pixel89_OnOff 0 "Pixel On" 1 "Pixel Off" ;
VAL_ 1362 ICC_LISD_Pixel90_OnOff 0 "Pixel On" 1 "Pixel Off" ;
VAL_ 1362 ICC_LISD_Pixel91_OnOff 0 "Pixel On" 1 "Pixel Off" ;
VAL_ 1362 ICC_LISD_Pixel92_OnOff 0 "Pixel On" 1 "Pixel Off" ;
VAL_ 1362 ICC_LISD_Pixel93_OnOff 0 "Pixel On" 1 "Pixel Off" ;
VAL_ 1362 ICC_LISD_Pixel94_OnOff 0 "Pixel On" 1 "Pixel Off" ;
VAL_ 1362 ICC_LISD_Pixel95_OnOff 0 "Pixel On" 1 "Pixel Off" ;
VAL_ 1362 ICC_LISD_Pixel96_OnOff 0 "Pixel On" 1 "Pixel Off" ;
VAL_ 1362 ICC_LISD_Pixel97_OnOff 0 "Pixel On" 1 "Pixel Off" ;
VAL_ 1362 ICC_LISD_Pixel98_OnOff 0 "Pixel On" 1 "Pixel Off" ;
VAL_ 1362 ICC_LISD_Pixel99_OnOff 0 "Pixel On" 1 "Pixel Off" ;
VAL_ 1362 ICC_LISD_Pixel100_OnOff 0 "Pixel On" 1 "Pixel Off" ;
VAL_ 1362 ICC_LISD_Pixel101_OnOff 0 "Pixel On" 1 "Pixel Off" ;
VAL_ 1362 ICC_LISD_Pixel102_OnOff 0 "Pixel On" 1 "Pixel Off" ;
VAL_ 1362 ICC_LISD_Pixel103_OnOff 0 "Pixel On" 1 "Pixel Off" ;
VAL_ 1362 ICC_LISD_Pixel104_OnOff 0 "Pixel On" 1 "Pixel Off" ;
VAL_ 1362 ICC_LISD_Pixel105_OnOff 0 "Pixel On" 1 "Pixel Off" ;
VAL_ 1362 ICC_LISD_Pixel106_OnOff 0 "Pixel On" 1 "Pixel Off" ;
VAL_ 1362 ICC_LISD_Pixel107_OnOff 0 "Pixel On" 1 "Pixel Off" ;
VAL_ 1362 ICC_LISD_Pixel108_OnOff 0 "Pixel On" 1 "Pixel Off" ;
VAL_ 1362 ICC_LISD_Pixel109_OnOff 0 "Pixel On" 1 "Pixel Off" ;
VAL_ 1362 ICC_LISD_Pixel110_OnOff 0 "Pixel On" 1 "Pixel Off" ;
VAL_ 1362 ICC_LISD_Pixel111_OnOff 0 "Pixel On" 1 "Pixel Off" ;
VAL_ 1362 ICC_LISD_Pixel112_OnOff 0 "Pixel On" 1 "Pixel Off" ;
VAL_ 1362 ICC_LISD_Pixel113_OnOff 0 "Pixel On" 1 "Pixel Off" ;
VAL_ 1362 ICC_LISD_Pixel114_OnOff 0 "Pixel On" 1 "Pixel Off" ;
VAL_ 1362 ICC_LISD_Pixel115_OnOff 0 "Pixel On" 1 "Pixel Off" ;
VAL_ 1362 ICC_LISD_Pixel116_OnOff 0 "Pixel On" 1 "Pixel Off" ;
VAL_ 1362 ICC_LISD_Pixel117_OnOff 0 "Pixel On" 1 "Pixel Off" ;
VAL_ 1362 ICC_LISD_Pixel118_OnOff 0 "Pixel On" 1 "Pixel Off" ;
VAL_ 1362 ICC_LISD_Pixel119_OnOff 0 "Pixel On" 1 "Pixel Off" ;
VAL_ 1362 ICC_LISD_Pixel120_OnOff 0 "Pixel On" 1 "Pixel Off" ;
VAL_ 1362 ICC_LISD_Pixel121_OnOff 0 "Pixel On" 1 "Pixel Off" ;
VAL_ 1362 ICC_LISD_Pixel122_OnOff 0 "Pixel On" 1 "Pixel Off" ;
VAL_ 1362 ICC_LISD_Pixel123_OnOff 0 "Pixel On" 1 "Pixel Off" ;
VAL_ 1362 ICC_LISD_Pixel124_OnOff 0 "Pixel On" 1 "Pixel Off" ;
VAL_ 1362 ICC_LISD_Pixel125_OnOff 0 "Pixel On" 1 "Pixel Off" ;
VAL_ 1362 ICC_LISD_Pixel126_OnOff 0 "Pixel On" 1 "Pixel Off" ;
VAL_ 1362 ICC_LISD_Pixel127_OnOff 0 "Pixel On" 1 "Pixel Off" ;
VAL_ 1362 ICC_LISD_Pixel128_OnOff 0 "Pixel On" 1 "Pixel Off" ;
VAL_ 1362 ICC_LISD_Pixel129_OnOff 0 "Pixel On" 1 "Pixel Off" ;
VAL_ 1362 ICC_LISD_Pixel130_OnOff 0 "Pixel On" 1 "Pixel Off" ;
VAL_ 1362 ICC_LISD_Pixel131_OnOff 0 "Pixel On" 1 "Pixel Off" ;
VAL_ 1362 ICC_LISD_Pixel132_OnOff 0 "Pixel On" 1 "Pixel Off" ;
VAL_ 1362 ICC_LISD_Pixel133_OnOff 0 "Pixel On" 1 "Pixel Off" ;
VAL_ 1362 ICC_LISD_Pixel134_OnOff 0 "Pixel On" 1 "Pixel Off" ;
VAL_ 1362 ICC_LISD_Pixel135_OnOff 0 "Pixel On" 1 "Pixel Off" ;
VAL_ 1362 ICC_LISD_Pixel136_OnOff 0 "Pixel On" 1 "Pixel Off" ;
VAL_ 1362 ICC_LISD_Pixel137_OnOff 0 "Pixel On" 1 "Pixel Off" ;
VAL_ 1362 ICC_LISD_Pixel138_OnOff 0 "Pixel On" 1 "Pixel Off" ;
VAL_ 1362 ICC_LISD_Pixel139_OnOff 0 "Pixel On" 1 "Pixel Off" ;
VAL_ 1362 ICC_LISD_Pixel140_OnOff 0 "Pixel On" 1 "Pixel Off" ;
VAL_ 1362 ICC_LISD_Pixel141_OnOff 0 "Pixel On" 1 "Pixel Off" ;
VAL_ 1362 ICC_LISD_Pixel142_OnOff 0 "Pixel On" 1 "Pixel Off" ;
VAL_ 1362 ICC_LISD_Pixel143_OnOff 0 "Pixel On" 1 "Pixel Off" ;
VAL_ 1362 ICC_LISD_Pixel144_OnOff 0 "Pixel On" 1 "Pixel Off" ;
VAL_ 1362 ICC_LISD_Pixel145_OnOff 0 "Pixel On" 1 "Pixel Off" ;
VAL_ 1362 ICC_LISD_Pixel146_OnOff 0 "Pixel On" 1 "Pixel Off" ;
VAL_ 1362 ICC_LISD_Pixel147_OnOff 0 "Pixel On" 1 "Pixel Off" ;
VAL_ 1362 ICC_LISD_Pixel148_OnOff 0 "Pixel On" 1 "Pixel Off" ;
VAL_ 1362 ICC_LISD_Pixel149_OnOff 0 "Pixel On" 1 "Pixel Off" ;
VAL_ 1362 ICC_LISD_Pixel150_OnOff 0 "Pixel On" 1 "Pixel Off" ;
VAL_ 1362 ICC_LISD_Pixel151_OnOff 0 "Pixel On" 1 "Pixel Off" ;
VAL_ 1362 ICC_LISD_Pixel152_OnOff 0 "Pixel On" 1 "Pixel Off" ;
VAL_ 1362 ICC_LISD_Pixel153_OnOff 0 "Pixel On" 1 "Pixel Off" ;
VAL_ 1362 ICC_LISD_Pixel154_OnOff 0 "Pixel On" 1 "Pixel Off" ;
VAL_ 1362 ICC_LISD_Pixel155_OnOff 0 "Pixel On" 1 "Pixel Off" ;
VAL_ 1362 ICC_LISD_Pixel156_OnOff 0 "Pixel On" 1 "Pixel Off" ;
VAL_ 1362 ICC_LISD_Pixel157_OnOff 0 "Pixel On" 1 "Pixel Off" ;
VAL_ 1362 ICC_LISD_Pixel158_OnOff 0 "Pixel On" 1 "Pixel Off" ;
VAL_ 1362 ICC_LISD_Pixel159_OnOff 0 "Pixel On" 1 "Pixel Off" ;
VAL_ 1362 ICC_LISD_Pixel160_OnOff 0 "Pixel On" 1 "Pixel Off" ;
VAL_ 1362 ICC_LISD_Pixel161_OnOff 0 "Pixel On" 1 "Pixel Off" ;
VAL_ 1362 ICC_LISD_Pixel162_OnOff 0 "Pixel On" 1 "Pixel Off" ;
VAL_ 1362 ICC_LISD_Pixel163_OnOff 0 "Pixel On" 1 "Pixel Off" ;
VAL_ 1362 ICC_LISD_Pixel164_OnOff 0 "Pixel On" 1 "Pixel Off" ;
VAL_ 1362 ICC_LISD_Pixel165_OnOff 0 "Pixel On" 1 "Pixel Off" ;
VAL_ 1362 ICC_LISD_Pixel166_OnOff 0 "Pixel On" 1 "Pixel Off" ;
VAL_ 1362 ICC_LISD_Pixel167_OnOff 0 "Pixel On" 1 "Pixel Off" ;
VAL_ 1362 ICC_LISD_Pixel168_OnOff 0 "Pixel On" 1 "Pixel Off" ;
VAL_ 1362 ICC_LISD_Pixel169_OnOff 0 "Pixel On" 1 "Pixel Off" ;
VAL_ 1362 ICC_LISD_Pixel170_OnOff 0 "Pixel On" 1 "Pixel Off" ;
VAL_ 1362 ICC_LISD_Pixel171_OnOff 0 "Pixel On" 1 "Pixel Off" ;
VAL_ 1362 ICC_LISD_Pixel172_OnOff 0 "Pixel On" 1 "Pixel Off" ;
VAL_ 1362 ICC_LISD_Pixel173_OnOff 0 "Pixel On" 1 "Pixel Off" ;
VAL_ 1362 ICC_LISD_Pixel174_OnOff 0 "Pixel On" 1 "Pixel Off" ;
VAL_ 1362 ICC_LISD_Pixel175_OnOff 0 "Pixel On" 1 "Pixel Off" ;
VAL_ 1362 ICC_LISD_Pixel176_OnOff 0 "Pixel On" 1 "Pixel Off" ;
VAL_ 1362 ICC_LISD_Pixel177_OnOff 0 "Pixel On" 1 "Pixel Off" ;
VAL_ 1362 ICC_LISD_Pixel178_OnOff 0 "Pixel On" 1 "Pixel Off" ;
VAL_ 1362 ICC_LISD_Pixel179_OnOff 0 "Pixel On" 1 "Pixel Off" ;
VAL_ 1362 ICC_LISD_Pixel180_OnOff 0 "Pixel On" 1 "Pixel Off" ;
VAL_ 1362 ICC_LISD_Pixel181_OnOff 0 "Pixel On" 1 "Pixel Off" ;
VAL_ 1362 ICC_LISD_Pixel182_OnOff 0 "Pixel On" 1 "Pixel Off" ;
VAL_ 1362 ICC_LISD_Pixel183_OnOff 0 "Pixel On" 1 "Pixel Off" ;
VAL_ 1362 ICC_LISD_Pixel184_OnOff 0 "Pixel On" 1 "Pixel Off" ;
VAL_ 1362 ICC_LISD_Pixel185_OnOff 0 "Pixel On" 1 "Pixel Off" ;
VAL_ 1362 ICC_LISD_Pixel186_OnOff 0 "Pixel On" 1 "Pixel Off" ;
VAL_ 1362 ICC_LISD_Pixel187_OnOff 0 "Pixel On" 1 "Pixel Off" ;
VAL_ 1362 ICC_LISD_Pixel188_OnOff 0 "Pixel On" 1 "Pixel Off" ;
VAL_ 1362 ICC_LISD_Pixel189_OnOff 0 "Pixel On" 1 "Pixel Off" ;
VAL_ 1362 ICC_LISD_Pixel190_OnOff 0 "Pixel On" 1 "Pixel Off" ;
VAL_ 1362 ICC_LISD_Pixel191_OnOff 0 "Pixel On" 1 "Pixel Off" ;
VAL_ 1362 ICC_LISD_Pixel192_OnOff 0 "Pixel On" 1 "Pixel Off" ;
VAL_ 1362 ICC_LISD_Pixel193_OnOff 0 "Pixel On" 1 "Pixel Off" ;
VAL_ 1362 ICC_LISD_Pixel194_OnOff 0 "Pixel On" 1 "Pixel Off" ;
VAL_ 1362 ICC_LISD_Pixel195_OnOff 0 "Pixel On" 1 "Pixel Off" ;
VAL_ 1362 ICC_LISD_Pixel196_OnOff 0 "Pixel On" 1 "Pixel Off" ;
VAL_ 1362 ICC_LISD_Pixel197_OnOff 0 "Pixel On" 1 "Pixel Off" ;
VAL_ 1362 ICC_LISD_Pixel198_OnOff 0 "Pixel On" 1 "Pixel Off" ;
VAL_ 1362 ICC_LISD_Pixel199_OnOff 0 "Pixel On" 1 "Pixel Off" ;
VAL_ 1362 ICC_LISD_Pixel200_OnOff 0 "Pixel On" 1 "Pixel Off" ;
VAL_ 1362 ICC_LISD_Pixel201_OnOff 0 "Pixel On" 1 "Pixel Off" ;
VAL_ 1362 ICC_LISD_Pixel202_OnOff 0 "Pixel On" 1 "Pixel Off" ;
VAL_ 1362 ICC_LISD_Pixel203_OnOff 0 "Pixel On" 1 "Pixel Off" ;
VAL_ 1362 ICC_LISD_Pixel204_OnOff 0 "Pixel On" 1 "Pixel Off" ;
VAL_ 1362 ICC_LISD_Pixel205_OnOff 0 "Pixel On" 1 "Pixel Off" ;
VAL_ 1362 ICC_LISD_Pixel206_OnOff 0 "Pixel On" 1 "Pixel Off" ;
VAL_ 1362 ICC_LISD_Pixel207_OnOff 0 "Pixel On" 1 "Pixel Off" ;
VAL_ 1362 ICC_LISD_Pixel208_OnOff 0 "Pixel On" 1 "Pixel Off" ;
VAL_ 1362 ICC_LISD_Pixel209_OnOff 0 "Pixel On" 1 "Pixel Off" ;
VAL_ 1362 ICC_LISD_Pixel210_OnOff 0 "Pixel On" 1 "Pixel Off" ;
VAL_ 1362 ICC_LISD_Pixel211_OnOff 0 "Pixel On" 1 "Pixel Off" ;
VAL_ 1362 ICC_LISD_Pixel212_OnOff 0 "Pixel On" 1 "Pixel Off" ;
VAL_ 1362 ICC_LISD_Pixel213_OnOff 0 "Pixel On" 1 "Pixel Off" ;
VAL_ 1362 ICC_LISD_Pixel214_OnOff 0 "Pixel On" 1 "Pixel Off" ;
VAL_ 1362 ICC_LISD_Pixel215_OnOff 0 "Pixel On" 1 "Pixel Off" ;
VAL_ 1362 ICC_LISD_Pixel216_OnOff 0 "Pixel On" 1 "Pixel Off" ;
VAL_ 1362 ICC_LISD_Pixel217_OnOff 0 "Pixel On" 1 "Pixel Off" ;
VAL_ 1362 ICC_LISD_Pixel218_OnOff 0 "Pixel On" 1 "Pixel Off" ;
VAL_ 1362 ICC_LISD_Pixel219_OnOff 0 "Pixel On" 1 "Pixel Off" ;
VAL_ 1362 ICC_LISD_Pixel220_OnOff 0 "Pixel On" 1 "Pixel Off" ;
VAL_ 1362 ICC_LISD_Pixel221_OnOff 0 "Pixel On" 1 "Pixel Off" ;
VAL_ 1362 ICC_LISD_Pixel222_OnOff 0 "Pixel On" 1 "Pixel Off" ;
VAL_ 1362 ICC_LISD_Pixel223_OnOff 0 "Pixel On" 1 "Pixel Off" ;
VAL_ 1362 ICC_LISD_Pixel224_OnOff 0 "Pixel On" 1 "Pixel Off" ;
VAL_ 1362 ICC_LISD_Pixel225_OnOff 0 "Pixel On" 1 "Pixel Off" ;
VAL_ 1362 ICC_LISD_Pixel226_OnOff 0 "Pixel On" 1 "Pixel Off" ;
VAL_ 1362 ICC_LISD_Pixel227_OnOff 0 "Pixel On" 1 "Pixel Off" ;
VAL_ 1362 ICC_LISD_Pixel228_OnOff 0 "Pixel On" 1 "Pixel Off" ;
VAL_ 1362 ICC_LISD_Pixel229_OnOff 0 "Pixel On" 1 "Pixel Off" ;
VAL_ 1362 ICC_LISD_Pixel230_OnOff 0 "Pixel On" 1 "Pixel Off" ;
VAL_ 1362 ICC_LISD_Pixel231_OnOff 0 "Pixel On" 1 "Pixel Off" ;
VAL_ 1362 ICC_LISD_Pixel232_OnOff 0 "Pixel On" 1 "Pixel Off" ;
VAL_ 1362 ICC_LISD_Pixel233_OnOff 0 "Pixel On" 1 "Pixel Off" ;
VAL_ 1362 ICC_LISD_Pixel234_OnOff 0 "Pixel On" 1 "Pixel Off" ;
VAL_ 1362 ICC_LISD_Pixel235_OnOff 0 "Pixel On" 1 "Pixel Off" ;
VAL_ 1362 ICC_LISD_Pixel236_OnOff 0 "Pixel On" 1 "Pixel Off" ;
VAL_ 1362 ICC_LISD_Pixel237_OnOff 0 "Pixel On" 1 "Pixel Off" ;
VAL_ 1362 ICC_LISD_Pixel238_OnOff 0 "Pixel On" 1 "Pixel Off" ;
VAL_ 1362 ICC_LISD_Pixel239_OnOff 0 "Pixel On" 1 "Pixel Off" ;
VAL_ 1362 ICC_LISD_Pixel240_OnOff 0 "Pixel On" 1 "Pixel Off" ;
VAL_ 1362 ICC_LISD_Pixel241_OnOff 0 "Pixel On" 1 "Pixel Off" ;
VAL_ 1362 ICC_LISD_Pixel242_OnOff 0 "Pixel On" 1 "Pixel Off" ;
VAL_ 1362 ICC_LISD_Pixel243_OnOff 0 "Pixel On" 1 "Pixel Off" ;
VAL_ 1362 ICC_LISD_Pixel244_OnOff 0 "Pixel On" 1 "Pixel Off" ;
VAL_ 1362 ICC_LISD_Pixel245_OnOff 0 "Pixel On" 1 "Pixel Off" ;
VAL_ 1362 ICC_LISD_Pixel246_OnOff 0 "Pixel On" 1 "Pixel Off" ;
VAL_ 1362 ICC_LISD_Pixel247_OnOff 0 "Pixel On" 1 "Pixel Off" ;
VAL_ 1362 ICC_LISD_Pixel248_OnOff 0 "Pixel On" 1 "Pixel Off" ;
VAL_ 1362 ICC_LISD_Pixel249_OnOff 0 "Pixel On" 1 "Pixel Off" ;
VAL_ 1362 ICC_LISD_Pixel250_OnOff 0 "Pixel On" 1 "Pixel Off" ;
VAL_ 1362 ICC_LISD_Pixel251_OnOff 0 "Pixel On" 1 "Pixel Off" ;
VAL_ 1362 ICC_LISD_Pixel252_OnOff 0 "Pixel On" 1 "Pixel Off" ;
VAL_ 1362 ICC_LISD_Pixel253_OnOff 0 "Pixel On" 1 "Pixel Off" ;
VAL_ 1362 ICC_LISD_Pixel254_OnOff 0 "Pixel On" 1 "Pixel Off" ;
VAL_ 1362 ICC_LISD_Pixel255_OnOff 0 "Pixel On" 1 "Pixel Off" ;
VAL_ 1362 ICC_LISD_Pixel256_OnOff 0 "Pixel On" 1 "Pixel Off" ;
VAL_ 1362 ICC_LISD_Pixel257_OnOff 0 "Pixel On" 1 "Pixel Off" ;
VAL_ 1362 ICC_LISD_Pixel258_OnOff 0 "Pixel On" 1 "Pixel Off" ;
VAL_ 1362 ICC_LISD_Pixel259_OnOff 0 "Pixel On" 1 "Pixel Off" ;
VAL_ 1362 ICC_LISD_Pixel260_OnOff 0 "Pixel On" 1 "Pixel Off" ;
VAL_ 1362 ICC_LISD_Pixel261_OnOff 0 "Pixel On" 1 "Pixel Off" ;
VAL_ 1362 ICC_LISD_Pixel262_OnOff 0 "Pixel On" 1 "Pixel Off" ;
VAL_ 1362 ICC_LISD_Pixel263_OnOff 0 "Pixel On" 1 "Pixel Off" ;
VAL_ 1362 ICC_LISD_Pixel264_OnOff 0 "Pixel On" 1 "Pixel Off" ;
VAL_ 1362 ICC_LISD_Pixel265_OnOff 0 "Pixel On" 1 "Pixel Off" ;
VAL_ 1362 ICC_LISD_Pixel266_OnOff 0 "Pixel On" 1 "Pixel Off" ;
VAL_ 1362 ICC_LISD_Pixel267_OnOff 0 "Pixel On" 1 "Pixel Off" ;
VAL_ 1362 ICC_LISD_Pixel268_OnOff 0 "Pixel On" 1 "Pixel Off" ;
VAL_ 1362 ICC_LISD_Pixel269_OnOff 0 "Pixel On" 1 "Pixel Off" ;
VAL_ 1362 ICC_LISD_Pixel270_OnOff 0 "Pixel On" 1 "Pixel Off" ;
VAL_ 1362 ICC_LISD_Pixel271_OnOff 0 "Pixel On" 1 "Pixel Off" ;
VAL_ 1362 ICC_LISD_Pixel272_OnOff 0 "Pixel On" 1 "Pixel Off" ;
VAL_ 1362 ICC_LISD_Pixel273_OnOff 0 "Pixel On" 1 "Pixel Off" ;
VAL_ 1362 ICC_LISD_Pixel274_OnOff 0 "Pixel On" 1 "Pixel Off" ;
VAL_ 1362 ICC_LISD_Pixel275_OnOff 0 "Pixel On" 1 "Pixel Off" ;
VAL_ 1362 ICC_LISD_Pixel276_OnOff 0 "Pixel On" 1 "Pixel Off" ;
VAL_ 1362 ICC_LISD_Pixel277_OnOff 0 "Pixel On" 1 "Pixel Off" ;
VAL_ 1362 ICC_LISD_Pixel278_OnOff 0 "Pixel On" 1 "Pixel Off" ;
VAL_ 1362 ICC_LISD_Pixel279_OnOff 0 "Pixel On" 1 "Pixel Off" ;
VAL_ 1362 ICC_LISD_Pixel280_OnOff 0 "Pixel On" 1 "Pixel Off" ;
VAL_ 1362 ICC_LISD_Pixel281_OnOff 0 "Pixel On" 1 "Pixel Off" ;
VAL_ 1362 ICC_LISD_Pixel282_OnOff 0 "Pixel On" 1 "Pixel Off" ;
VAL_ 1362 ICC_LISD_Pixel283_OnOff 0 "Pixel On" 1 "Pixel Off" ;
VAL_ 1362 ICC_LISD_Pixel284_OnOff 0 "Pixel On" 1 "Pixel Off" ;
VAL_ 1362 ICC_LISD_Pixel285_OnOff 0 "Pixel On" 1 "Pixel Off" ;
VAL_ 1362 ICC_LISD_Pixel286_OnOff 0 "Pixel On" 1 "Pixel Off" ;
VAL_ 1362 ICC_LISD_Pixel287_OnOff 0 "Pixel On" 1 "Pixel Off" ;
VAL_ 1362 ICC_LISD_Pixel288_OnOff 0 "Pixel On" 1 "Pixel Off" ;
VAL_ 1362 ICC_LISD_Pixel289_OnOff 0 "Pixel On" 1 "Pixel Off" ;
VAL_ 1362 ICC_LISD_Pixel290_OnOff 0 "Pixel On" 1 "Pixel Off" ;
VAL_ 1362 ICC_LISD_Pixel291_OnOff 0 "Pixel On" 1 "Pixel Off" ;
VAL_ 1362 ICC_LISD_Pixel292_OnOff 0 "Pixel On" 1 "Pixel Off" ;
VAL_ 1362 ICC_LISD_Pixel293_OnOff 0 "Pixel On" 1 "Pixel Off" ;
VAL_ 1362 ICC_LISD_Pixel294_OnOff 0 "Pixel On" 1 "Pixel Off" ;
VAL_ 1362 ICC_LISD_Pixel295_OnOff 0 "Pixel On" 1 "Pixel Off" ;
VAL_ 1362 ICC_LISD_Pixel296_OnOff 0 "Pixel On" 1 "Pixel Off" ;
VAL_ 1362 ICC_LISD_Pixel297_OnOff 0 "Pixel On" 1 "Pixel Off" ;
VAL_ 1362 ICC_LISD_Pixel298_OnOff 0 "Pixel On" 1 "Pixel Off" ;
VAL_ 1362 ICC_LISD_Pixel299_OnOff 0 "Pixel On" 1 "Pixel Off" ;
VAL_ 1362 ICC_LISD_Pixel300_OnOff 0 "Pixel On" 1 "Pixel Off" ;
VAL_ 1362 ICC_LISD_Pixel301_OnOff 0 "Pixel On" 1 "Pixel Off" ;
VAL_ 1362 ICC_LISD_Pixel302_OnOff 0 "Pixel On" 1 "Pixel Off" ;
VAL_ 1362 ICC_LISD_Pixel303_OnOff 0 "Pixel On" 1 "Pixel Off" ;
VAL_ 1362 ICC_LISD_Pixel304_OnOff 0 "Pixel On" 1 "Pixel Off" ;
VAL_ 1362 ICC_LISD_Pixel305_OnOff 0 "Pixel On" 1 "Pixel Off" ;
VAL_ 1362 ICC_LISD_Pixel306_OnOff 0 "Pixel On" 1 "Pixel Off" ;
VAL_ 1362 ICC_LISD_Pixel307_OnOff 0 "Pixel On" 1 "Pixel Off" ;
VAL_ 1362 ICC_LISD_Pixel308_OnOff 0 "Pixel On" 1 "Pixel Off" ;
VAL_ 1362 ICC_LISD_Pixel309_OnOff 0 "Pixel On" 1 "Pixel Off" ;
VAL_ 1362 ICC_LISD_Pixel310_OnOff 0 "Pixel On" 1 "Pixel Off" ;
VAL_ 1362 ICC_LISD_Pixel311_OnOff 0 "Pixel On" 1 "Pixel Off" ;
VAL_ 1362 ICC_LISD_Pixel312_OnOff 0 "Pixel On" 1 "Pixel Off" ;
VAL_ 1362 ICC_LISD_Pixel313_OnOff 0 "Pixel On" 1 "Pixel Off" ;
VAL_ 1362 ICC_LISD_Pixel314_OnOff 0 "Pixel On" 1 "Pixel Off" ;
VAL_ 1362 ICC_LISD_Pixel315_OnOff 0 "Pixel On" 1 "Pixel Off" ;
VAL_ 1362 ICC_LISD_Pixel316_OnOff 0 "Pixel On" 1 "Pixel Off" ;
VAL_ 1362 ICC_LISD_Pixel317_OnOff 0 "Pixel On" 1 "Pixel Off" ;
VAL_ 1362 ICC_LISD_Pixel318_OnOff 0 "Pixel On" 1 "Pixel Off" ;
VAL_ 1362 ICC_LISD_Pixel319_OnOff 0 "Pixel On" 1 "Pixel Off" ;
VAL_ 1362 ICC_LISD_Pixel320_OnOff 0 "Pixel On" 1 "Pixel Off" ;
VAL_ 1362 ICC_LISD_Pixel321_OnOff 0 "Pixel On" 1 "Pixel Off" ;
VAL_ 1362 ICC_LISD_Pixel322_OnOff 0 "Pixel On" 1 "Pixel Off" ;
VAL_ 1362 ICC_LISD_Pixel323_OnOff 0 "Pixel On" 1 "Pixel Off" ;
VAL_ 1362 ICC_LISD_Pixel324_OnOff 0 "Pixel On" 1 "Pixel Off" ;
VAL_ 1362 ICC_LISD_Pixel325_OnOff 0 "Pixel On" 1 "Pixel Off" ;
VAL_ 1362 ICC_LISD_Pixel326_OnOff 0 "Pixel On" 1 "Pixel Off" ;
VAL_ 1362 ICC_LISD_Pixel327_OnOff 0 "Pixel On" 1 "Pixel Off" ;
VAL_ 1362 ICC_LISD_Pixel328_OnOff 0 "Pixel On" 1 "Pixel Off" ;
VAL_ 1362 ICC_LISD_Pixel329_OnOff 0 "Pixel On" 1 "Pixel Off" ;
VAL_ 1362 ICC_LISD_Pixel330_OnOff 0 "Pixel On" 1 "Pixel Off" ;
VAL_ 1362 ICC_LISD_Pixel331_OnOff 0 "Pixel On" 1 "Pixel Off" ;
VAL_ 1362 ICC_LISD_Pixel332_OnOff 0 "Pixel On" 1 "Pixel Off" ;
VAL_ 1362 ICC_LISD_Pixel333_OnOff 0 "Pixel On" 1 "Pixel Off" ;
VAL_ 1362 ICC_LISD_Pixel334_OnOff 0 "Pixel On" 1 "Pixel Off" ;
VAL_ 1362 ICC_LISD_Pixel335_OnOff 0 "Pixel On" 1 "Pixel Off" ;
VAL_ 1362 ICC_LISD_Pixel336_OnOff 0 "Pixel On" 1 "Pixel Off" ;
VAL_ 1362 ICC_LISD_Pixel337_OnOff 0 "Pixel On" 1 "Pixel Off" ;
VAL_ 1362 ICC_LISD_Pixel338_OnOff 0 "Pixel On" 1 "Pixel Off" ;
VAL_ 1362 ICC_LISD_Pixel339_OnOff 0 "Pixel On" 1 "Pixel Off" ;
VAL_ 1362 ICC_LISD_Pixel340_OnOff 0 "Pixel On" 1 "Pixel Off" ;
VAL_ 1362 ICC_LISD_Pixel341_OnOff 0 "Pixel On" 1 "Pixel Off" ;
VAL_ 1362 ICC_LISD_Pixel342_OnOff 0 "Pixel On" 1 "Pixel Off" ;
VAL_ 1362 ICC_LISD_Pixel343_OnOff 0 "Pixel On" 1 "Pixel Off" ;
VAL_ 1362 ICC_LISD_Pixel344_OnOff 0 "Pixel On" 1 "Pixel Off" ;
VAL_ 1362 ICC_LISD_Pixel345_OnOff 0 "Pixel On" 1 "Pixel Off" ;
VAL_ 1362 ICC_LISD_Pixel346_OnOff 0 "Pixel On" 1 "Pixel Off" ;
VAL_ 1362 ICC_LISD_Pixel347_OnOff 0 "Pixel On" 1 "Pixel Off" ;
VAL_ 1362 ICC_LISD_Pixel348_OnOff 0 "Pixel On" 1 "Pixel Off" ;
VAL_ 1362 ICC_LISD_Pixel349_OnOff 0 "Pixel On" 1 "Pixel Off" ;
VAL_ 1362 ICC_LISD_Pixel350_OnOff 0 "Pixel On" 1 "Pixel Off" ;
VAL_ 1362 ICC_LISD_Pixel351_OnOff 0 "Pixel On" 1 "Pixel Off" ;
VAL_ 1362 ICC_LISD_Pixel352_OnOff 0 "Pixel On" 1 "Pixel Off" ;
VAL_ 1362 ICC_LISD_Pixel353_OnOff 0 "Pixel On" 1 "Pixel Off" ;
VAL_ 1362 ICC_LISD_Pixel354_OnOff 0 "Pixel On" 1 "Pixel Off" ;
VAL_ 1362 ICC_LISD_Pixel355_OnOff 0 "Pixel On" 1 "Pixel Off" ;
VAL_ 1362 ICC_LISD_Pixel356_OnOff 0 "Pixel On" 1 "Pixel Off" ;
VAL_ 1362 ICC_LISD_Pixel357_OnOff 0 "Pixel On" 1 "Pixel Off" ;
VAL_ 1362 ICC_LISD_Pixel358_OnOff 0 "Pixel On" 1 "Pixel Off" ;
VAL_ 1362 ICC_LISD_Pixel359_OnOff 0 "Pixel On" 1 "Pixel Off" ;
VAL_ 1362 ICC_LISD_Pixel360_OnOff 0 "Pixel On" 1 "Pixel Off" ;
VAL_ 1362 ICC_LISD_Pixel361_OnOff 0 "Pixel On" 1 "Pixel Off" ;
VAL_ 1362 ICC_LISD_Pixel362_OnOff 0 "Pixel On" 1 "Pixel Off" ;
VAL_ 1362 ICC_LISD_Pixel363_OnOff 0 "Pixel On" 1 "Pixel Off" ;
VAL_ 1362 ICC_LISD_Pixel364_OnOff 0 "Pixel On" 1 "Pixel Off" ;
VAL_ 1362 ICC_LISD_Pixel365_OnOff 0 "Pixel On" 1 "Pixel Off" ;
VAL_ 1362 ICC_LISD_Pixel366_OnOff 0 "Pixel On" 1 "Pixel Off" ;
VAL_ 1362 ICC_LISD_Pixel367_OnOff 0 "Pixel On" 1 "Pixel Off" ;
VAL_ 1362 ICC_LISD_Pixel368_OnOff 0 "Pixel On" 1 "Pixel Off" ;
VAL_ 1362 ICC_LISD_Pixel369_OnOff 0 "Pixel On" 1 "Pixel Off" ;
VAL_ 1362 ICC_LISD_Pixel370_OnOff 0 "Pixel On" 1 "Pixel Off" ;
VAL_ 1362 ICC_LISD_Pixel371_OnOff 0 "Pixel On" 1 "Pixel Off" ;
VAL_ 1362 ICC_LISD_Pixel372_OnOff 0 "Pixel On" 1 "Pixel Off" ;
VAL_ 1362 ICC_LISD_Pixel373_OnOff 0 "Pixel On" 1 "Pixel Off" ;
VAL_ 1362 ICC_LISD_Pixel374_OnOff 0 "Pixel On" 1 "Pixel Off" ;
VAL_ 1362 ICC_LISD_Pixel375_OnOff 0 "Pixel On" 1 "Pixel Off" ;
VAL_ 1362 ICC_LISD_Pixel376_OnOff 0 "Pixel On" 1 "Pixel Off" ;
VAL_ 1362 ICC_LISD_Pixel377_OnOff 0 "Pixel On" 1 "Pixel Off" ;
VAL_ 1362 ICC_LISD_Pixel378_OnOff 0 "Pixel On" 1 "Pixel Off" ;
VAL_ 1362 ICC_LISD_Pixel379_OnOff 0 "Pixel On" 1 "Pixel Off" ;
VAL_ 1362 ICC_LISD_Pixel380_OnOff 0 "Pixel On" 1 "Pixel Off" ;
VAL_ 1362 ICC_LISD_Pixel381_OnOff 0 "Pixel On" 1 "Pixel Off" ;
VAL_ 1362 ICC_LISD_Pixel382_OnOff 0 "Pixel On" 1 "Pixel Off" ;
VAL_ 1362 ICC_LISD_Pixel383_OnOff 0 "Pixel On" 1 "Pixel Off" ;
VAL_ 1362 ICC_LISD_Pixel384_OnOff 0 "Pixel On" 1 "Pixel Off" ;
VAL_ 1362 ICC_LISD_Pixel385_OnOff 0 "Pixel On" 1 "Pixel Off" ;
VAL_ 1362 ICC_LISD_Pixel386_OnOff 0 "Pixel On" 1 "Pixel Off" ;
VAL_ 1362 ICC_LISD_Pixel387_OnOff 0 "Pixel On" 1 "Pixel Off" ;
VAL_ 1362 ICC_LISD_Pixel388_OnOff 0 "Pixel On" 1 "Pixel Off" ;
VAL_ 1362 ICC_LISD_Pixel389_OnOff 0 "Pixel On" 1 "Pixel Off" ;
VAL_ 1362 ICC_LISD_Pixel390_OnOff 0 "Pixel On" 1 "Pixel Off" ;
VAL_ 1362 ICC_LISD_Pixel391_OnOff 0 "Pixel On" 1 "Pixel Off" ;
VAL_ 1362 ICC_LISD_Pixel392_OnOff 0 "Pixel On" 1 "Pixel Off" ;
VAL_ 1362 ICC_LISD_Pixel393_OnOff 0 "Pixel On" 1 "Pixel Off" ;
VAL_ 1362 ICC_LISD_Pixel394_OnOff 0 "Pixel On" 1 "Pixel Off" ;
VAL_ 1362 ICC_LISD_Pixel395_OnOff 0 "Pixel On" 1 "Pixel Off" ;
VAL_ 1362 ICC_LISD_Pixel396_OnOff 0 "Pixel On" 1 "Pixel Off" ;
VAL_ 1362 ICC_LISD_Pixel397_OnOff 0 "Pixel On" 1 "Pixel Off" ;
VAL_ 1362 ICC_LISD_Pixel398_OnOff 0 "Pixel On" 1 "Pixel Off" ;
VAL_ 1362 ICC_LISD_Pixel399_OnOff 0 "Pixel On" 1 "Pixel Off" ;
VAL_ 1362 ICC_LISD_Pixel400_OnOff 0 "Pixel On" 1 "Pixel Off" ;
VAL_ 1362 ICC_LISD_Pixel401_OnOff 0 "Pixel On" 1 "Pixel Off" ;
VAL_ 1362 ICC_LISD_Pixel402_OnOff 0 "Pixel On" 1 "Pixel Off" ;
VAL_ 1362 ICC_LISD_Pixel403_OnOff 0 "Pixel On" 1 "Pixel Off" ;
VAL_ 1362 ICC_LISD_Pixel404_OnOff 0 "Pixel On" 1 "Pixel Off" ;
VAL_ 1362 ICC_LISD_Pixel405_OnOff 0 "Pixel On" 1 "Pixel Off" ;
VAL_ 1362 ICC_LISD_Pixel406_OnOff 0 "Pixel On" 1 "Pixel Off" ;
VAL_ 1362 ICC_LISD_Pixel407_OnOff 0 "Pixel On" 1 "Pixel Off" ;
VAL_ 1362 ICC_LISD_Pixel408_OnOff 0 "Pixel On" 1 "Pixel Off" ;
VAL_ 1362 ICC_LISD_Pixel409_OnOff 0 "Pixel On" 1 "Pixel Off" ;
VAL_ 1362 ICC_LISD_Pixel410_OnOff 0 "Pixel On" 1 "Pixel Off" ;
VAL_ 1362 ICC_LISD_Pixel411_OnOff 0 "Pixel On" 1 "Pixel Off" ;
VAL_ 1362 ICC_LISD_Pixel412_OnOff 0 "Pixel On" 1 "Pixel Off" ;
VAL_ 1362 ICC_LISD_Pixel413_OnOff 0 "Pixel On" 1 "Pixel Off" ;
VAL_ 1362 ICC_LISD_Pixel414_OnOff 0 "Pixel On" 1 "Pixel Off" ;
VAL_ 1362 ICC_LISD_Pixel415_OnOff 0 "Pixel On" 1 "Pixel Off" ;
VAL_ 1362 ICC_LISD_Pixel416_OnOff 0 "Pixel On" 1 "Pixel Off" ;
VAL_ 1362 ICC_LISD_Pixel417_OnOff 0 "Pixel On" 1 "Pixel Off" ;
VAL_ 1362 ICC_LISD_Pixel418_OnOff 0 "Pixel On" 1 "Pixel Off" ;
VAL_ 1362 ICC_LISD_Pixel419_OnOff 0 "Pixel On" 1 "Pixel Off" ;
VAL_ 1362 ICC_LISD_Pixel420_OnOff 0 "Pixel On" 1 "Pixel Off" ;
VAL_ 1362 ICC_LISD_Pixel421_OnOff 0 "Pixel On" 1 "Pixel Off" ;
VAL_ 1362 ICC_LISD_Pixel422_OnOff 0 "Pixel On" 1 "Pixel Off" ;
VAL_ 1362 ICC_LISD_Pixel423_OnOff 0 "Pixel On" 1 "Pixel Off" ;
VAL_ 1362 ICC_LISD_Pixel424_OnOff 0 "Pixel On" 1 "Pixel Off" ;
VAL_ 1362 ICC_LISD_Pixel425_OnOff 0 "Pixel On" 1 "Pixel Off" ;
VAL_ 1362 ICC_LISD_Pixel426_OnOff 0 "Pixel On" 1 "Pixel Off" ;
VAL_ 1362 ICC_LISD_Pixel427_OnOff 0 "Pixel On" 1 "Pixel Off" ;
VAL_ 1362 ICC_LISD_Pixel428_OnOff 0 "Pixel On" 1 "Pixel Off" ;
VAL_ 1362 ICC_LISD_Pixel429_OnOff 0 "Pixel On" 1 "Pixel Off" ;
VAL_ 1362 ICC_LISD_Pixel430_OnOff 0 "Pixel On" 1 "Pixel Off" ;
VAL_ 1362 ICC_LISD_Pixel431_OnOff 0 "Pixel On" 1 "Pixel Off" ;
VAL_ 1362 ICC_LISD_Pixel432_OnOff 0 "Pixel On" 1 "Pixel Off" ;
VAL_ 1362 ICC_LISD_Pixel433_OnOff 0 "Pixel On" 1 "Pixel Off" ;
VAL_ 1362 ICC_LISD_Pixel434_OnOff 0 "Pixel On" 1 "Pixel Off" ;
VAL_ 1362 ICC_LISD_Pixel435_OnOff 0 "Pixel On" 1 "Pixel Off" ;
VAL_ 1362 ICC_LISD_Pixel436_OnOff 0 "Pixel On" 1 "Pixel Off" ;
VAL_ 1362 ICC_LISD_Pixel437_OnOff 0 "Pixel On" 1 "Pixel Off" ;
VAL_ 1362 ICC_LISD_Pixel438_OnOff 0 "Pixel On" 1 "Pixel Off" ;
VAL_ 1362 ICC_LISD_Pixel439_OnOff 0 "Pixel On" 1 "Pixel Off" ;
VAL_ 1362 ICC_LISD_Pixel440_OnOff 0 "Pixel On" 1 "Pixel Off" ;
VAL_ 1362 ICC_LISD_Pixel441_OnOff 0 "Pixel On" 1 "Pixel Off" ;
VAL_ 1362 ICC_LISD_Pixel442_OnOff 0 "Pixel On" 1 "Pixel Off" ;
VAL_ 1362 ICC_LISD_Pixel443_OnOff 0 "Pixel On" 1 "Pixel Off" ;
VAL_ 1362 ICC_LISD_Pixel444_OnOff 0 "Pixel On" 1 "Pixel Off" ;
VAL_ 1362 ICC_LISD_Pixel445_OnOff 0 "Pixel On" 1 "Pixel Off" ;
VAL_ 1362 ICC_LISD_Pixel446_OnOff 0 "Pixel On" 1 "Pixel Off" ;
VAL_ 1362 ICC_LISD_Pixel447_OnOff 0 "Pixel On" 1 "Pixel Off" ;
VAL_ 1362 ICC_LISD_Pixel448_OnOff 0 "Pixel On" 1 "Pixel Off" ;
VAL_ 1362 ICC_LISD_Pixel449_OnOff 0 "Pixel On" 1 "Pixel Off" ;
VAL_ 1362 ICC_LISD_Pixel450_OnOff 0 "Pixel On" 1 "Pixel Off" ;
VAL_ 1362 ICC_LISD_Pixel451_OnOff 0 "Pixel On" 1 "Pixel Off" ;
VAL_ 1362 ICC_LISD_Pixel452_OnOff 0 "Pixel On" 1 "Pixel Off" ;
VAL_ 1362 ICC_LISD_Pixel453_OnOff 0 "Pixel On" 1 "Pixel Off" ;
VAL_ 1362 ICC_LISD_Pixel454_OnOff 0 "Pixel On" 1 "Pixel Off" ;
VAL_ 1362 ICC_LISD_Pixel455_OnOff 0 "Pixel On" 1 "Pixel Off" ;
VAL_ 1362 ICC_LISD_Pixel456_OnOff 0 "Pixel On" 1 "Pixel Off" ;
VAL_ 1362 ICC_LISD_Pixel457_OnOff 0 "Pixel On" 1 "Pixel Off" ;
VAL_ 1362 ICC_LISD_Pixel458_OnOff 0 "Pixel On" 1 "Pixel Off" ;
VAL_ 1362 ICC_LISD_Pixel459_OnOff 0 "Pixel On" 1 "Pixel Off" ;
VAL_ 1362 ICC_LISD_Pixel460_OnOff 0 "Pixel On" 1 "Pixel Off" ;
VAL_ 1362 ICC_LISD_Pixel461_OnOff 0 "Pixel On" 1 "Pixel Off" ;
VAL_ 1362 ICC_LISD_Pixel462_OnOff 0 "Pixel On" 1 "Pixel Off" ;
VAL_ 1362 ICC_LISD_Pixel463_OnOff 0 "Pixel On" 1 "Pixel Off" ;
VAL_ 1362 ICC_LISD_Pixel464_OnOff 0 "Pixel On" 1 "Pixel Off" ;
VAL_ 1362 ICC_LISD_Pixel465_OnOff 0 "Pixel On" 1 "Pixel Off" ;
VAL_ 1362 ICC_LISD_Pixel466_OnOff 0 "Pixel On" 1 "Pixel Off" ;
VAL_ 1362 ICC_LISD_Pixel467_OnOff 0 "Pixel On" 1 "Pixel Off" ;
VAL_ 1362 ICC_LISD_Pixel468_OnOff 0 "Pixel On" 1 "Pixel Off" ;
VAL_ 1362 ICC_LISD_Pixel469_OnOff 0 "Pixel On" 1 "Pixel Off" ;
VAL_ 1362 ICC_LISD_Pixel470_OnOff 0 "Pixel On" 1 "Pixel Off" ;
VAL_ 1362 ICC_LISD_Pixel471_OnOff 0 "Pixel On" 1 "Pixel Off" ;
VAL_ 1362 ICC_LISD_Pixel472_OnOff 0 "Pixel On" 1 "Pixel Off" ;
VAL_ 1362 ICC_LISD_Pixel473_OnOff 0 "Pixel On" 1 "Pixel Off" ;
VAL_ 1362 ICC_LISD_Pixel474_OnOff 0 "Pixel On" 1 "Pixel Off" ;
VAL_ 1362 ICC_LISD_Pixel475_OnOff 0 "Pixel On" 1 "Pixel Off" ;
VAL_ 1362 ICC_LISD_Pixel476_OnOff 0 "Pixel On" 1 "Pixel Off" ;
VAL_ 1362 ICC_LISD_Pixel477_OnOff 0 "Pixel On" 1 "Pixel Off" ;
VAL_ 1362 ICC_LISD_Pixel478_OnOff 0 "Pixel On" 1 "Pixel Off" ;
VAL_ 1362 ICC_LISD_Pixel479_OnOff 0 "Pixel On" 1 "Pixel Off" ;
VAL_ 1362 ICC_LISD_Pixel480_OnOff 0 "Pixel On" 1 "Pixel Off" ;
VAL_ 1362 ICC_LISD_Pixel481_OnOff 0 "Pixel On" 1 "Pixel Off" ;
VAL_ 1362 ICC_LISD_Pixel482_OnOff 0 "Pixel On" 1 "Pixel Off" ;
VAL_ 1362 ICC_LISD_Pixel483_OnOff 0 "Pixel On" 1 "Pixel Off" ;
VAL_ 1362 ICC_LISD_Pixel484_OnOff 0 "Pixel On" 1 "Pixel Off" ;
VAL_ 1362 ICC_LISD_Pixel485_OnOff 0 "Pixel On" 1 "Pixel Off" ;
VAL_ 1362 ICC_LISD_Pixel486_OnOff 0 "Pixel On" 1 "Pixel Off" ;
VAL_ 1362 ICC_LISD_Pixel487_OnOff 0 "Pixel On" 1 "Pixel Off" ;
VAL_ 1362 ICC_LISD_Pixel488_OnOff 0 "Pixel On" 1 "Pixel Off" ;
VAL_ 1362 ICC_LISD_Pixel489_OnOff 0 "Pixel On" 1 "Pixel Off" ;
VAL_ 1362 ICC_LISD_Pixel490_OnOff 0 "Pixel On" 1 "Pixel Off" ;
VAL_ 1362 ICC_LISD_Pixel491_OnOff 0 "Pixel On" 1 "Pixel Off" ;
VAL_ 1362 ICC_LISD_Pixel492_OnOff 0 "Pixel On" 1 "Pixel Off" ;
VAL_ 1362 ICC_LISD_Pixel493_OnOff 0 "Pixel On" 1 "Pixel Off" ;
VAL_ 1362 ICC_LISD_Pixel494_OnOff 0 "Pixel On" 1 "Pixel Off" ;
VAL_ 1362 ICC_LISD_Pixel495_OnOff 0 "Pixel On" 1 "Pixel Off" ;
VAL_ 1362 ICC_LISD_Pixel496_OnOff 0 "Pixel On" 1 "Pixel Off" ;
VAL_ 1362 ICC_LISD_Pixel497_OnOff 0 "Pixel On" 1 "Pixel Off" ;
VAL_ 1362 ICC_LISD_Pixel498_OnOff 0 "Pixel On" 1 "Pixel Off" ;
VAL_ 1362 ICC_LISD_Pixel499_OnOff 0 "Pixel On" 1 "Pixel Off" ;
VAL_ 1362 ICC_LISD_Pixel500_OnOff 0 "Pixel On" 1 "Pixel Off" ;
VAL_ 1362 ICC_LISD_Pixel501_OnOff 0 "Pixel On" 1 "Pixel Off" ;
VAL_ 1362 ICC_LISD_Pixel502_OnOff 0 "Pixel On" 1 "Pixel Off" ;
VAL_ 1362 ICC_LISD_Pixel503_OnOff 0 "Pixel On" 1 "Pixel Off" ;
VAL_ 1362 ICC_LISD_Pixel504_OnOff 0 "Pixel On" 1 "Pixel Off" ;
